VERSION ""

NS_ :

BS_:

BU_: EBOOST_CE TRCM_CE CGM_CE EPS_JR_CE MSB1_CE MSB2_CE ARS_CE SDM_CE EBCM_OBD_CE HCP_T_CE LCMS_CE APA_CE HCP_CE EOCM_F_CE MCP_C_CE MCP_B_CE MCP_A_CE FCM_CE ICCM_CE Dummy_CE TestTool_CE ACC_CE RDCM_CE EBCM_CE SADS_CE IMU_CE SAS_CE EPS_CE

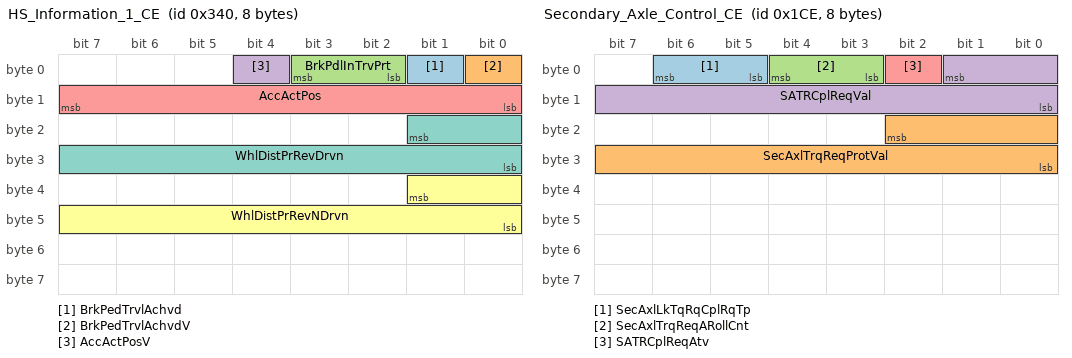
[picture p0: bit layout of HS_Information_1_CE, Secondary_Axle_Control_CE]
BO_ 832 HS_Information_1_CE: 8 EBCM_CE
 SG_ BrkPedTrvlAchvd : 1|1@0+ (1,0) [0|1] ""  SDM_CE,MSB1_CE,MSB2_CE,EPS_JR_CE
 SG_ BrkPedTrvlAchvdV : 0|1@0+ (1,0) [0|1] ""  SDM_CE,MSB1_CE,MSB2_CE,EPS_JR_CE
 SG_ BrkPdlInTrvPrt : 3|2@0+ (1,0) [0|3] ""  EPS_JR_CE
 SG_ AccActPosV : 4|1@0+ (1,0) [0|1] ""  FCM_CE,MSB1_CE,MSB2_CE
 SG_ AccActPos : 15|8@0+ (0.392157,0) [0|100.000035] "%"  FCM_CE,MSB1_CE,MSB2_CE
 SG_ WhlDistPrRevNDrvn : 33|10@0+ (3,800) [800|3869] "mm"  ARS_CE,EPS_CE,EPS_JR_CE,SDM_CE,APA_CE
 SG_ WhlDistPrRevDrvn : 17|10@0+ (3,800) [800|3869] "mm"  ARS_CE,EPS_JR_CE,EPS_CE,SDM_CE,APA_CE

BO_ 462 Secondary_Axle_Control_CE: 8 EBCM_CE
 SG_ SecAxlLkTqRqCplRqTp : 6|2@0+ (1,0) [0|3] ""  RDCM_CE
 SG_ SecAxlTrqReqProtVal : 18|11@0+ (1,0) [0|2047] "Counts"  RDCM_CE
 SG_ SecAxlTrqReqARollCnt : 4|2@0+ (1,0) [0|3] "Counts"  RDCM_CE
 SG_ SATRCplReqVal : 1|10@0+ (10,0) [0|10230] "Nm"  RDCM_CE
 SG_ SATRCplReqAtv : 2|1@0+ (1,0) [0|1] ""  RDCM_CE

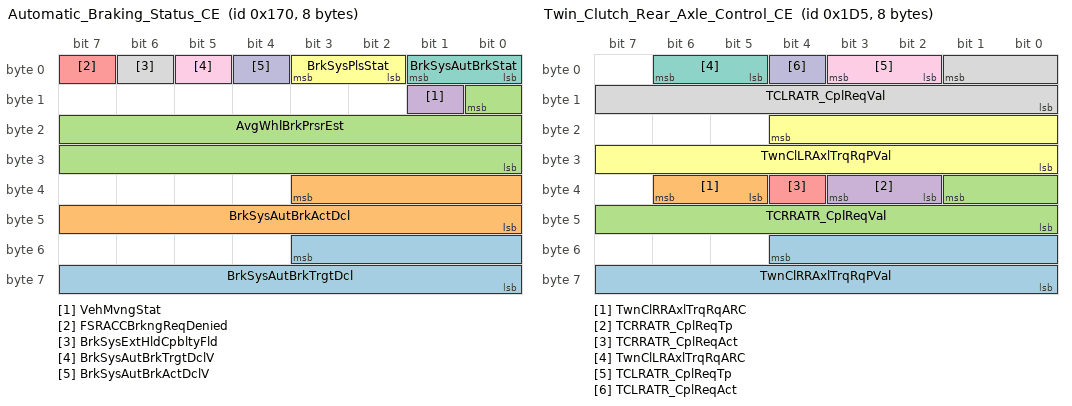
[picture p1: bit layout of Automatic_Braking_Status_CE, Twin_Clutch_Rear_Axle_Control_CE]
BO_ 368 Automatic_Braking_Status_CE: 8 EBCM_CE
 SG_ BrkSysAutBrkTrgtDcl : 51|12@0- (0.01,0) [-20.48|20.47] "m/s^2"  APA_CE,SADS_CE,ACC_CE,EOCM_F_CE
 SG_ BrkSysAutBrkActDcl : 35|12@0- (0.01,0) [-20.48|20.47] "m/s^2"  APA_CE,EOCM_F_CE,ACC_CE,SADS_CE
 SG_ AvgWhlBrkPrsrEst : 8|17@0+ (0.1,0) [0|13107.1] "kPa"  APA_CE,ACC_CE,EOCM_F_CE,SADS_CE
 SG_ VehMvngStat : 9|1@0+ (1,0) [0|1] ""  APA_CE,ACC_CE,EOCM_F_CE
 SG_ FSRACCBrkngReqDenied : 7|1@0+ (1,0) [0|1] ""  APA_CE,ACC_CE,EOCM_F_CE
 SG_ BrkSysPlsStat : 3|2@0+ (1,0) [0|3] ""  APA_CE,EOCM_F_CE
 SG_ BrkSysAutBrkStat : 1|2@0+ (1,0) [0|3] ""  ICCM_CE,APA_CE,SADS_CE,ACC_CE,EOCM_F_CE
 SG_ BrkSysExtHldCpbltyFld : 6|1@0+ (1,0) [0|1] ""  ICCM_CE,APA_CE,ACC_CE,EOCM_F_CE
 SG_ BrkSysAutBrkTrgtDclV : 5|1@0+ (1,0) [0|1] ""  APA_CE,SADS_CE,ACC_CE,EOCM_F_CE
 SG_ BrkSysAutBrkActDclV : 4|1@0+ (1,0) [0|1] ""  APA_CE,EOCM_F_CE,SADS_CE,ACC_CE

BO_ 469 Twin_Clutch_Rear_Axle_Control_CE: 8 EBCM_CE
 SG_ TwnClRRAxlTrqRqPVal : 52|13@0+ (1,0) [0|8191] ""  RDCM_CE
 SG_ TwnClRRAxlTrqRqARC : 38|2@0+ (1,0) [0|3] ""  RDCM_CE
 SG_ TCRRATR_CplReqVal : 33|10@0+ (10,0) [0|10230] "Nm"  RDCM_CE
 SG_ TCRRATR_CplReqTp : 35|2@0+ (1,0) [0|3] ""  RDCM_CE
 SG_ TCRRATR_CplReqAct : 36|1@0+ (1,0) [0|1] ""  RDCM_CE
 SG_ TwnClLRAxlTrqRqPVal : 20|13@0+ (1,0) [0|8191] ""  RDCM_CE
 SG_ TwnClLRAxlTrqRqARC : 6|2@0+ (1,0) [0|3] ""  RDCM_CE
 SG_ TCLRATR_CplReqVal : 1|10@0+ (10,0) [0|10230] "Nm"  RDCM_CE
 SG_ TCLRATR_CplReqTp : 3|2@0+ (1,0) [0|3] ""  RDCM_CE
 SG_ TCLRATR_CplReqAct : 4|1@0+ (1,0) [0|1] ""  RDCM_CE

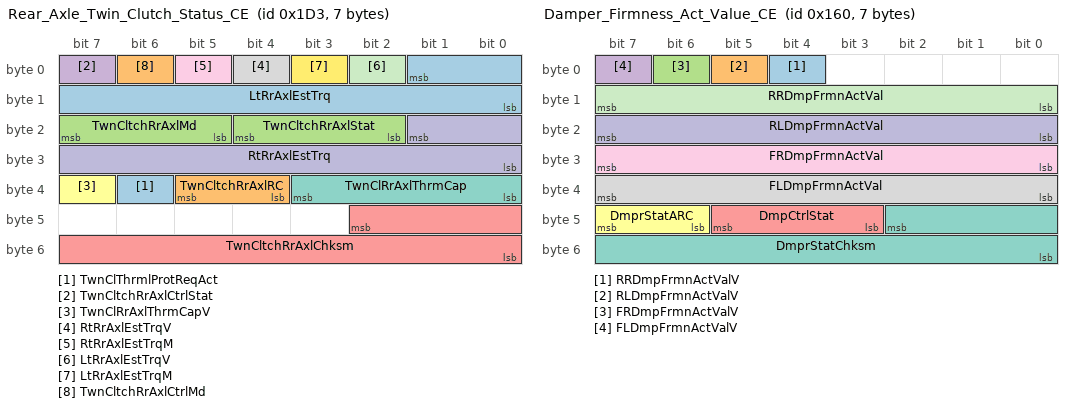
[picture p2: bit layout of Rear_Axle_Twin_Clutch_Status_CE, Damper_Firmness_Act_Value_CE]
BO_ 467 Rear_Axle_Twin_Clutch_Status_CE: 7 RDCM_CE
 SG_ TwnClThrmlProtReqAct : 38|1@0+ (1,0) [0|1] ""  EBCM_OBD_CE,EBCM_CE
 SG_ TwnCltchRrAxlRC : 37|2@0+ (1,0) [0|3] ""  EBCM_OBD_CE,EBCM_CE
 SG_ TwnCltchRrAxlMd : 23|3@0+ (1,0) [0|7] ""  EBCM_OBD_CE,EBCM_CE
 SG_ TwnCltchRrAxlCtrlStat : 7|1@0+ (1,0) [0|1] ""  EBCM_OBD_CE,EBCM_CE
 SG_ TwnCltchRrAxlChksm : 42|11@0+ (1,0) [0|2047] ""  EBCM_OBD_CE,EBCM_CE
 SG_ TwnClRrAxlThrmCapV : 39|1@0+ (1,0) [0|1] ""  EBCM_OBD_CE,EBCM_CE
 SG_ TwnClRrAxlThrmCap : 35|4@0+ (6.7,0) [0|100.5] "%"  EBCM_OBD_CE,EBCM_CE
 SG_ RtRrAxlEstTrqV : 4|1@0+ (1,0) [0|1] ""  EBCM_OBD_CE,EBCM_CE
 SG_ RtRrAxlEstTrqM : 5|1@0+ (1,0) [0|1] ""  EBCM_OBD_CE,EBCM_CE
 SG_ RtRrAxlEstTrq : 17|10@0+ (10,0) [0|10230] "Nm"  EBCM_OBD_CE,EBCM_CE
 SG_ LtRrAxlEstTrqV : 2|1@0+ (1,0) [0|1] ""  EBCM_OBD_CE,EBCM_CE
 SG_ LtRrAxlEstTrqM : 3|1@0+ (1,0) [0|1] ""  EBCM_OBD_CE,EBCM_CE
 SG_ LtRrAxlEstTrq : 1|10@0+ (10,0) [0|10230] "Nm"  EBCM_OBD_CE,EBCM_CE
 SG_ TwnCltchRrAxlCtrlMd : 6|1@0+ (1,0) [0|1] ""  EBCM_OBD_CE,EBCM_CE
 SG_ TwnCltchRrAxlStat : 20|3@0+ (1,0) [0|7] ""  EBCM_OBD_CE,EBCM_CE

BO_ 352 Damper_Firmness_Act_Value_CE: 7 SADS_CE
 SG_ RRDmpFrmnActValV : 4|1@0+ (1,0) [0|1] ""  EBCM_OBD_CE,EBCM_CE
 SG_ RLDmpFrmnActValV : 5|1@0+ (1,0) [0|1] ""  EBCM_OBD_CE,EBCM_CE
 SG_ FRDmpFrmnActValV : 6|1@0+ (1,0) [0|1] ""  EBCM_OBD_CE,EBCM_CE
 SG_ FLDmpFrmnActValV : 7|1@0+ (1,0) [0|1] ""  EBCM_OBD_CE,EBCM_CE
 SG_ DmpCtrlStat : 45|3@0+ (1,0) [0|7] ""  EBCM_OBD_CE,EBCM_CE
 SG_ DmprStatARC : 47|2@0+ (1,0) [0|3] "Counts"  EBCM_OBD_CE,EBCM_CE
 SG_ DmprStatChksm : 42|11@0+ (1,0) [0|2047] ""  EBCM_OBD_CE,EBCM_CE
 SG_ FLDmpFrmnActVal : 39|8@0+ (0.392157,0) [0|100.000035] "%"  EBCM_OBD_CE,EBCM_CE
 SG_ FRDmpFrmnActVal : 31|8@0+ (0.392157,0) [0|100.000035] "%"  EBCM_OBD_CE,EBCM_CE
 SG_ RLDmpFrmnActVal : 23|8@0+ (0.392157,0) [0|100.000035] "%"  EBCM_OBD_CE,EBCM_CE
 SG_ RRDmpFrmnActVal : 15|8@0+ (0.392157,0) [0|100.000035] "%"  EBCM_OBD_CE,EBCM_CE

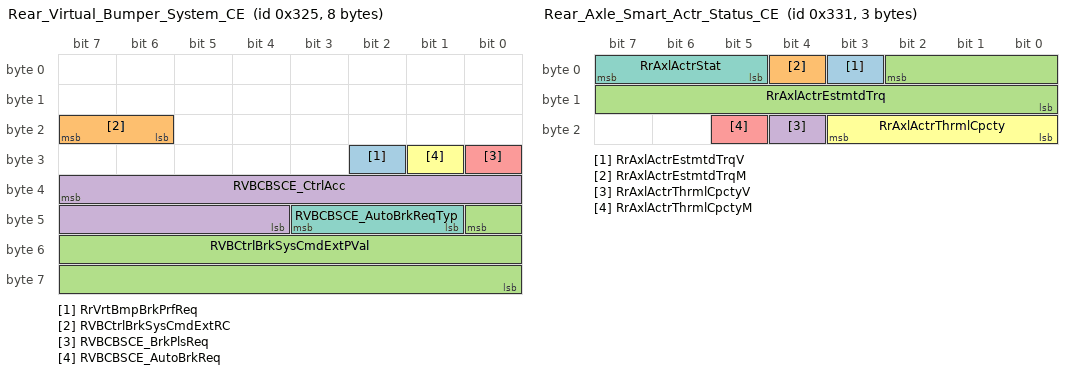
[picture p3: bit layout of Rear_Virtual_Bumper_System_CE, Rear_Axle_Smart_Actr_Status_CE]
BO_ 805 Rear_Virtual_Bumper_System_CE: 8 EOCM_F_CE
 SG_ RrVrtBmpBrkPrfReq : 26|1@0+ (1,0) [0|1] ""  EBCM_OBD_CE,EBCM_CE
 SG_ RVBCtrlBrkSysCmdExtRC : 23|2@0+ (1,0) [0|3] ""  EBCM_OBD_CE,EBCM_CE
 SG_ RVBCtrlBrkSysCmdExtPVal : 40|17@0+ (1,0) [0|131071] ""  EBCM_OBD_CE,EBCM_CE
 SG_ RVBCBSCE_CtrlAcc : 39|12@0- (0.01,0) [-20.48|20.47] "m/s^2"  EBCM_OBD_CE,EBCM_CE
 SG_ RVBCBSCE_BrkPlsReq : 24|1@0+ (1,0) [0|1] ""  EBCM_OBD_CE,EBCM_CE
 SG_ RVBCBSCE_AutoBrkReq : 25|1@0+ (1,0) [0|1] ""  EBCM_OBD_CE,EBCM_CE
 SG_ RVBCBSCE_AutoBrkReqTyp : 43|3@0+ (1,0) [0|7] ""  EBCM_OBD_CE,EBCM_CE

BO_ 257 USDT_Req_to_All_CE_ECUs: 8 TestTool_CE
 SG_ DgnInf : 7|64@0+ (1,0) [0|1.84467440737096E+019] ""  SDM_CE,EBCM_OBD_CE,HCP_T_CE,HCP_CE,ARS_CE,ICCM_CE,ACC_CE,MCP_C_CE,APA_CE,MCP_B_CE,MCP_A_CE,EBOOST_CE,MSB2_CE,MSB1_CE,SAS_CE,SADS_CE,RDCM_CE,IMU_CE,Dummy_CE,EPS_JR_CE,EPS_CE,EBCM_CE,CGM_CE,TRCM_CE,EOCM_F_CE,FCM_CE

BO_ 1375 UUDT_Resp_From_Free_5F_CE: 8 Dummy_CE
 SG_ DgnInf_CE55F : 7|64@0+ (1,0) [0|1.84467440737096E+019] ""  TestTool_CE

BO_ 1374 UUDT_Resp_From_Free_5E_CE: 8 Dummy_CE
 SG_ DgnInf_CE55E : 7|64@0+ (1,0) [0|1.84467440737096E+019] ""  TestTool_CE

BO_ 1373 UUDT_Resp_From_ARS_CE: 8 ARS_CE
 SG_ DgnInf_CE55D : 7|64@0+ (1,0) [0|1.84467440737096E+019] ""  TestTool_CE

BO_ 1371 UUDT_Resp_From_ACC_CE: 8 ACC_CE
 SG_ DgnInf_CE55B : 7|64@0+ (1,0) [0|1.84467440737096E+019] ""  TestTool_CE

BO_ 1370 UUDT_Resp_From_MCP_C_CE: 8 MCP_C_CE
 SG_ DgnInf_CE55A : 7|64@0+ (1,0) [0|1.84467440737096E+019] ""  TestTool_CE

BO_ 1369 UUDT_Resp_From_APA_CE: 8 APA_CE
 SG_ DgnInf_CE559 : 7|64@0+ (1,0) [0|1.84467440737096E+019] ""  TestTool_CE

BO_ 1372 UUDT_Resp_From_ICCM_CE: 8 ICCM_CE
 SG_ DgnInf_CE55C : 7|64@0+ (1,0) [0|1.84467440737096E+019] ""  TestTool_CE

BO_ 1367 UUDT_Resp_From_MCP_A_CE: 8 MCP_A_CE
 SG_ DgnInf_CE557 : 7|64@0+ (1,0) [0|1.84467440737096E+019] ""  TestTool_CE

BO_ 1366 UUDT_Resp_From_Free_56_CE: 8 Dummy_CE
 SG_ DgnInf_CE556 : 7|64@0+ (1,0) [0|1.84467440737096E+019] ""  TestTool_CE

BO_ 1365 UUDT_Resp_From_TRCM_CE: 8 TRCM_CE
 SG_ DgnInf_CE555 : 7|64@0+ (1,0) [0|1.84467440737096E+019] ""  TestTool_CE

BO_ 1368 UUDT_Resp_From_MCP_B_CE: 8 MCP_B_CE
 SG_ DgnInf_CE558 : 7|64@0+ (1,0) [0|1.84467440737096E+019] ""  TestTool_CE

BO_ 1363 UUDT_Resp_From_CGM_CE: 8 CGM_CE
 SG_ DgnInf_CE553 : 7|64@0+ (1,0) [0|1.84467440737096E+019] ""  TestTool_CE

BO_ 1362 UUDT_Resp_From_Free_52_CE: 8 Dummy_CE
 SG_ DgnInf_CE552 : 7|64@0+ (1,0) [0|1.84467440737096E+019] ""  TestTool_CE

BO_ 1361 UUDT_Resp_From_Free_51_CE: 8 Dummy_CE
 SG_ DgnInf_CE551 : 7|64@0+ (1,0) [0|1.84467440737096E+019] ""  TestTool_CE

BO_ 1518 UUDT_Resp_From_EBOOST_CE: 8 EBOOST_CE
 SG_ DgnInf_CE554 : 7|64@0+ (1,0) [0|1.84467440737096E+019] ""  TestTool_CE

BO_ 1359 UUDT_Resp_From_RDCM_CE: 8 RDCM_CE
 SG_ DgnInf_CE54F : 7|64@0+ (1,0) [0|1.84467440737096E+019] ""  TestTool_CE

BO_ 1358 UUDT_Resp_From_SADS_CE: 8 SADS_CE
 SG_ DgnInf_CE54E : 7|64@0+ (1,0) [0|1.84467440737096E+019] ""  TestTool_CE

BO_ 1357 UUDT_Resp_From_Free_4D_CE: 8 Dummy_CE
 SG_ DgnInf_CE54D : 7|64@0+ (1,0) [0|1.84467440737096E+019] ""  TestTool_CE

BO_ 1360 UUDT_Resp_From_Free_50_CE: 8 Dummy_CE
 SG_ DgnInf_CE550 : 7|64@0+ (1,0) [0|1.84467440737096E+019] ""  TestTool_CE

BO_ 1355 UUDT_Resp_From_EOCM_FCM_CE: 8 FCM_CE
 SG_ DgnInf_CE54B : 7|64@0+ (1,0) [0|1.84467440737096E+019] ""  TestTool_CE

BO_ 1352 UUDT_Resp_From_MSB1_CE: 8 MSB1_CE
 SG_ DgnInf_CE548 : 7|64@0+ (1,0) [0|1.84467440737096E+019] ""  TestTool_CE

BO_ 1353 UUDT_Resp_From_MSB2_CE: 8 MSB2_CE
 SG_ DgnInf_CE549 : 7|64@0+ (1,0) [0|1.84467440737096E+019] ""  TestTool_CE

BO_ 1351 UUDT_Resp_From_SDM_CE: 8 SDM_CE
 SG_ DgnInf_CE547 : 7|64@0+ (1,0) [0|1.84467440737096E+019] ""  TestTool_CE

BO_ 1350 UUDT_Resp_From_Free_46_CE: 8 Dummy_CE
 SG_ DgnInf_CE546 : 7|64@0+ (1,0) [0|1.84467440737096E+019] ""  TestTool_CE

BO_ 1349 UUDT_Resp_From_Free_45_CE: 8 Dummy_CE
 SG_ DgnInf_CE545 : 7|64@0+ (1,0) [0|1.84467440737096E+019] ""  TestTool_CE

BO_ 1356 UUDT_Resp_From_Free_48_CE: 8 Dummy_CE
 SG_ DgnInf_CE54C : 7|64@0+ (1,0) [0|1.84467440737096E+019] ""  TestTool_CE

BO_ 1348 UUDT_Resp_From_IMU_CE: 8 IMU_CE
 SG_ DgnInf_CE544 : 7|64@0+ (1,0) [0|1.84467440737096E+019] ""  TestTool_CE

BO_ 1347 UUDT_Resp_From_EBCM_CE: 8 EBCM_CE
 SG_ DgnInf_CE543 : 7|64@0+ (1,0) [0|1.84467440737096E+019] ""  TestTool_CE

BO_ 1354 UUDT_Resp_From_EPS_EPS_JR_CE: 8 EPS_CE
 SG_ DgnInf_CE542 : 7|64@0+ (1,0) [0|1.84467440737096E+019] ""  TestTool_CE

BO_ 1345 UUDT_Resp_From_Free_41_CE: 8 Dummy_CE
 SG_ DgnInf_CE541 : 7|64@0+ (1,0) [0|1.84467440737096E+019] ""  TestTool_CE

BO_ 1631 USDT_Resp_From_Free_5F_CE: 8 Dummy_CE
 SG_ DgnInf : 7|64@0+ (1,0) [0|1.84467440737096E+019] ""  TestTool_CE

BO_ 1630 USDT_Resp_From_Free_5E_CE: 8 Dummy_CE
 SG_ DgnInf : 7|64@0+ (1,0) [0|1.84467440737096E+019] ""  TestTool_CE

BO_ 1629 USDT_Resp_From_ARS_CE: 8 ARS_CE
 SG_ DgnInf : 7|64@0+ (1,0) [0|1.84467440737096E+019] ""  TestTool_CE

BO_ 1627 USDT_Resp_From_ACC_CE: 8 ACC_CE
 SG_ DgnInf : 7|64@0+ (1,0) [0|1.84467440737096E+019] ""  TestTool_CE

BO_ 1626 USDT_Resp_From_MCP_C_CE: 8 MCP_C_CE
 SG_ DgnInf : 7|64@0+ (1,0) [0|1.84467440737096E+019] ""  TestTool_CE

BO_ 1625 USDT_Resp_From_APA_CE: 8 APA_CE
 SG_ DgnInf : 7|64@0+ (1,0) [0|1.84467440737096E+019] ""  TestTool_CE

BO_ 1628 USDT_Resp_From_ICCM_CE: 8 ICCM_CE
 SG_ DgnInf : 7|64@0+ (1,0) [0|1.84467440737096E+019] ""  TestTool_CE

BO_ 1623 USDT_Resp_From_MCP_A_CE: 8 MCP_A_CE
 SG_ DgnInf : 7|64@0+ (1,0) [0|1.84467440737096E+019] ""  TestTool_CE

BO_ 1622 USDT_Resp_From_Free_56_CE: 8 Dummy_CE
 SG_ DgnInf : 7|64@0+ (1,0) [0|1.84467440737096E+019] ""  TestTool_CE

BO_ 1621 USDT_Resp_From_TRCM_CE: 8 TRCM_CE
 SG_ DgnInf : 7|64@0+ (1,0) [0|1.84467440737096E+019] ""  TestTool_CE

BO_ 1624 USDT_Resp_From_MCP_B_CE: 8 MCP_B_CE
 SG_ DgnInf : 7|64@0+ (1,0) [0|1.84467440737096E+019] ""  TestTool_CE

BO_ 1619 USDT_Resp_From_CGM_CE: 8 CGM_CE
 SG_ DgnInf : 7|64@0+ (1,0) [0|1.84467440737096E+019] ""  TestTool_CE

BO_ 1618 USDT_Resp_From_Free_52_CE: 8 Dummy_CE
 SG_ DgnInf : 7|64@0+ (1,0) [0|1.84467440737096E+019] ""  TestTool_CE

BO_ 1617 USDT_Resp_From_Free_51_CE: 8 Dummy_CE
 SG_ DgnInf : 7|64@0+ (1,0) [0|1.84467440737096E+019] ""  TestTool_CE

BO_ 2030 USDT_Resp_From_EBOOST_CE: 8 EBOOST_CE
 SG_ DgnInf : 7|64@0+ (1,0) [0|1.84467440737096E+019] ""  TestTool_CE

BO_ 1615 USDT_Resp_From_RDCM_CE: 8 RDCM_CE
 SG_ DgnInf : 7|64@0+ (1,0) [0|1.84467440737096E+019] ""  TestTool_CE

BO_ 1614 USDT_Resp_From_SADS_CE: 8 SADS_CE
 SG_ DgnInf : 7|64@0+ (1,0) [0|1.84467440737096E+019] ""  TestTool_CE

BO_ 1613 USDT_Resp_From_Free_4D_CE: 8 Dummy_CE
 SG_ DgnInf : 7|64@0+ (1,0) [0|1.84467440737096E+019] ""  TestTool_CE

BO_ 1616 USDT_Resp_From_Free_50_CE: 8 Dummy_CE
 SG_ DgnInf : 7|64@0+ (1,0) [0|1.84467440737096E+019] ""  TestTool_CE

BO_ 1611 USDT_Resp_From_EOCM_FCM_CE: 8 FCM_CE
 SG_ DgnInf : 7|64@0+ (1,0) [0|1.84467440737096E+019] ""  TestTool_CE

BO_ 1608 USDT_Resp_From_MSB1_CE: 8 MSB1_CE
 SG_ DgnInf : 7|64@0+ (1,0) [0|1.84467440737096E+019] ""  TestTool_CE

BO_ 1609 USDT_Resp_From_MSB2_CE: 8 MSB2_CE
 SG_ DgnInf : 7|64@0+ (1,0) [0|1.84467440737096E+019] ""  TestTool_CE

BO_ 1607 USDT_Resp_From_SDM_CE: 8 SDM_CE
 SG_ DgnInf : 7|64@0+ (1,0) [0|1.84467440737096E+019] ""  TestTool_CE

BO_ 1606 USDT_Resp_From_Free_46_CE: 8 Dummy_CE
 SG_ DgnInf : 7|64@0+ (1,0) [0|1.84467440737096E+019] ""  TestTool_CE

BO_ 1605 USDT_Resp_From_Free_45_CE: 8 Dummy_CE
 SG_ DgnInf : 7|64@0+ (1,0) [0|1.84467440737096E+019] ""  TestTool_CE

BO_ 1612 USDT_Resp_From_Free_48_CE: 8 Dummy_CE
 SG_ DgnInf : 7|64@0+ (1,0) [0|1.84467440737096E+019] ""  TestTool_CE

BO_ 1604 USDT_Resp_From_IMU_CE: 8 IMU_CE
 SG_ DgnInf : 7|64@0+ (1,0) [0|1.84467440737096E+019] ""  TestTool_CE

BO_ 1603 USDT_Resp_From_EBCM_CE: 8 EBCM_CE
 SG_ DgnInf : 7|64@0+ (1,0) [0|1.84467440737096E+019] ""  TestTool_CE

BO_ 1610 USDT_Resp_From_EPS_EPS_JR_CE: 8 EPS_CE
 SG_ DgnInf : 7|64@0+ (1,0) [0|1.84467440737096E+019] ""  TestTool_CE

BO_ 1601 USDT_Resp_From_Free_41_CE: 8 Dummy_CE
 SG_ DgnInf : 7|64@0+ (1,0) [0|1.84467440737096E+019] ""  TestTool_CE

BO_ 607 USDT_Req_to_Free_5F_CE: 8 TestTool_CE
 SG_ DgnInf : 7|64@0+ (1,0) [0|1.84467440737096E+019] ""  Dummy_CE

BO_ 606 USDT_Req_to_Free_5E_CE: 8 TestTool_CE
 SG_ DgnInf : 7|64@0+ (1,0) [0|1.84467440737096E+019] ""  Dummy_CE

BO_ 605 USDT_Req_to_ARS_CE: 8 TestTool_CE
 SG_ DgnInf : 7|64@0+ (1,0) [0|1.84467440737096E+019] ""  ARS_CE

BO_ 604 USDT_Req_to_ICCM_CE: 8 TestTool_CE
 SG_ DgnInf : 7|64@0+ (1,0) [0|1.84467440737096E+019] ""  ICCM_CE

BO_ 603 USDT_Req_to_ACC_CE: 8 TestTool_CE
 SG_ DgnInf : 7|64@0+ (1,0) [0|1.84467440737096E+019] ""  ACC_CE

BO_ 602 USDT_Req_to_MCP_C_CE: 8 TestTool_CE
 SG_ DgnInf : 7|64@0+ (1,0) [0|1.84467440737096E+019] ""  MCP_C_CE

BO_ 601 USDT_Req_to_APA_CE: 8 TestTool_CE
 SG_ DgnInf : 7|64@0+ (1,0) [0|1.84467440737096E+019] ""  APA_CE

BO_ 600 USDT_Req_to_MCP_B_CE: 8 TestTool_CE
 SG_ DgnInf : 7|64@0+ (1,0) [0|1.84467440737096E+019] ""  MCP_B_CE

BO_ 599 USDT_Req_to_MCP_A_CE: 8 TestTool_CE
 SG_ DgnInf : 7|64@0+ (1,0) [0|1.84467440737096E+019] ""  MCP_A_CE

BO_ 598 USDT_Req_to_Free_56_CE: 8 TestTool_CE
 SG_ DgnInf : 7|64@0+ (1,0) [0|1.84467440737096E+019] ""  Dummy_CE

BO_ 597 USDT_Req_To_TRCM_CE: 8 TestTool_CE
 SG_ DgnInf : 7|64@0+ (1,0) [0|1.84467440737096E+019] ""  TRCM_CE

BO_ 2022 USDT_Req_to_EBOOST_CE: 8 TestTool_CE
 SG_ DgnInf : 7|64@0+ (1,0) [0|1.84467440737096E+019] ""  EBOOST_CE

BO_ 595 USDT_Req_to_CGM_CE: 8 TestTool_CE
 SG_ DgnInf : 7|64@0+ (1,0) [0|1.84467440737096E+019] ""  CGM_CE

BO_ 594 USDT_Req_to_Free_52_CE: 8 TestTool_CE
 SG_ DgnInf : 7|64@0+ (1,0) [0|1.84467440737096E+019] ""  Dummy_CE

BO_ 593 USDT_Req_to_Free_51_CE: 8 TestTool_CE
 SG_ DgnInf : 7|64@0+ (1,0) [0|1.84467440737096E+019] ""  Dummy_CE

BO_ 592 USDT_Req_to_Free_50_CE: 8 TestTool_CE
 SG_ DgnInf : 7|64@0+ (1,0) [0|1.84467440737096E+019] ""  Dummy_CE

BO_ 591 USDT_Req_to_RDCM_CE: 8 TestTool_CE
 SG_ DgnInf : 7|64@0+ (1,0) [0|1.84467440737096E+019] ""  RDCM_CE

BO_ 590 USDT_Req_to_SADS_CE: 8 TestTool_CE
 SG_ DgnInf : 7|64@0+ (1,0) [0|1.84467440737096E+019] ""  SADS_CE

BO_ 589 USDT_Req_to_Free_4D_CE: 8 TestTool_CE
 SG_ DgnInf : 7|64@0+ (1,0) [0|1.84467440737096E+019] ""  Dummy_CE

BO_ 585 USDT_Req_to_MSB2_CE: 8 TestTool_CE
 SG_ DgnInf : 7|64@0+ (1,0) [0|1.84467440737096E+019] ""  MSB2_CE

BO_ 587 USDT_Req_to_EOCM_CE: 8 TestTool_CE
 SG_ DgnInf : 7|64@0+ (1,0) [0|1.84467440737096E+019] ""  EOCM_F_CE,FCM_CE

BO_ 584 USDT_Req_to_MSB1_CE: 8 TestTool_CE
 SG_ DgnInf : 7|64@0+ (1,0) [0|1.84467440737096E+019] ""  MSB1_CE

BO_ 588 USDT_Req_to_Free_48_CE: 8 TestTool_CE
 SG_ DgnInf : 7|64@0+ (1,0) [0|1.84467440737096E+019] ""  Dummy_CE

BO_ 583 USDT_Req_to_SDM_CE: 8 TestTool_CE
 SG_ DgnInf : 7|64@0+ (1,0) [0|1.84467440737096E+019] ""  SDM_CE

BO_ 582 USDT_Req_to_Free_46_CE: 8 TestTool_CE
 SG_ DgnInf : 7|64@0+ (1,0) [0|1.84467440737096E+019] ""  Dummy_CE

BO_ 581 USDT_Req_to_Free_45_CE: 8 TestTool_CE
 SG_ DgnInf : 7|64@0+ (1,0) [0|1.84467440737096E+019] ""  Dummy_CE

BO_ 817 Rear_Axle_Smart_Actr_Status_CE: 3 RDCM_CE
 SG_ RrAxlActrEstmtdTrqV : 3|1@0+ (1,0) [0|1] ""  ICCM_CE
 SG_ RrAxlActrEstmtdTrqM : 4|1@0+ (1,0) [0|1] ""  ICCM_CE
 SG_ RrAxlActrEstmtdTrq : 2|11@0+ (5,-5120) [-5120|5115] "Nm"  ICCM_CE
 SG_ RrAxlActrThrmlCpctyV : 20|1@0+ (1,0) [0|1] ""  ICCM_CE
 SG_ RrAxlActrThrmlCpctyM : 21|1@0+ (1,0) [0|1] ""  ICCM_CE
 SG_ RrAxlActrThrmlCpcty : 19|4@0+ (6.7,0) [0|100.5] "%"  ICCM_CE
 SG_ RrAxlActrStat : 7|3@0+ (1,0) [0|7] ""  ICCM_CE

BO_ 580 USDT_Req_to_IMU_CE: 8 TestTool_CE
 SG_ DgnInf : 7|64@0+ (1,0) [0|1.84467440737096E+019] ""  IMU_CE

BO_ 579 USDT_Req_to_EBCM_CE: 8 TestTool_CE
 SG_ DgnInf : 7|64@0+ (1,0) [0|1.84467440737096E+019] ""  EBCM_CE

BO_ 578 USDT_Req_to_EPS_EPS_JR_CE: 8 TestTool_CE
 SG_ DgnInf : 7|64@0+ (1,0) [0|1.84467440737096E+019] ""  EPS_JR_CE,EPS_CE

BO_ 577 USDT_Req_to_Free_41_CE: 8 TestTool_CE
 SG_ DgnInf : 7|64@0+ (1,0) [0|1.84467440737096E+019] ""  Dummy_CE

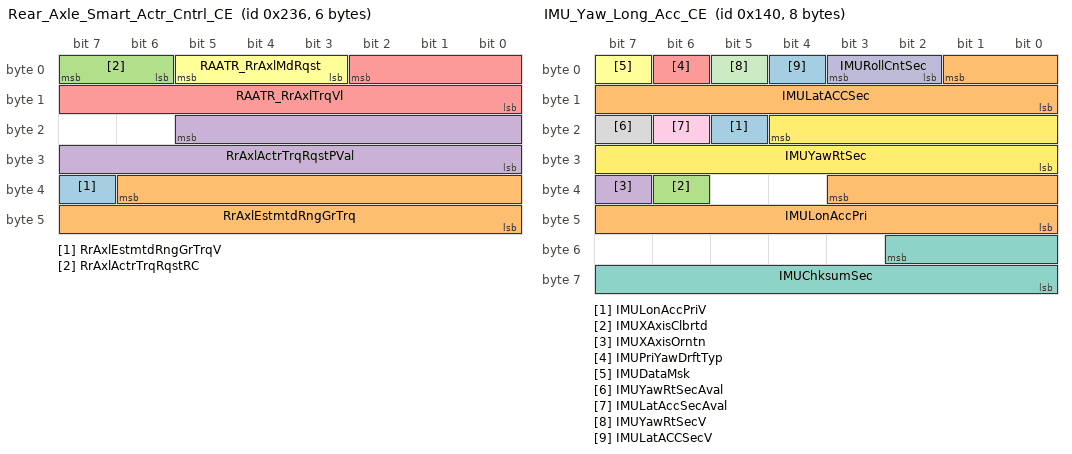
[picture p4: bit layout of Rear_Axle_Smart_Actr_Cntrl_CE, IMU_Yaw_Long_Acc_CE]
BO_ 566 Rear_Axle_Smart_Actr_Cntrl_CE: 6 ICCM_CE
 SG_ RrAxlEstmtdRngGrTrqV : 39|1@0+ (1,0) [0|1] ""  RDCM_CE
 SG_ RrAxlEstmtdRngGrTrq : 38|15@0+ (2,-22534) [-22534|43000] "Nm"  RDCM_CE
 SG_ RrAxlActrTrqRqstRC : 7|2@0+ (1,0) [0|3] ""  RDCM_CE
 SG_ RrAxlActrTrqRqstPVal : 21|14@0+ (1,0) [0|16383] ""  RDCM_CE
 SG_ RAATR_RrAxlTrqVl : 2|11@0+ (5,-5120) [-5120|5115] "Nm"  RDCM_CE
 SG_ RAATR_RrAxlMdRqst : 5|3@0+ (1,0) [0|7] ""  RDCM_CE

BO_ 320 IMU_Yaw_Long_Acc_CE: 8 IMU_CE
 SG_ IMULonAccPriV : 21|1@0+ (1,0) [0|1] ""  FCM_CE,ICCM_CE,APA_CE,SADS_CE,ACC_CE,EBCM_OBD_CE,EBCM_CE,RDCM_CE,SDM_CE,EOCM_F_CE,EPS_JR_CE,EPS_CE
 SG_ IMULonAccPri : 35|12@0- (0.015625,0) [-32|31.984375] "m/s^2"  FCM_CE,ICCM_CE,APA_CE,SADS_CE,ACC_CE,EBCM_OBD_CE,EBCM_CE,RDCM_CE,SDM_CE,EOCM_F_CE,EPS_JR_CE,EPS_CE
 SG_ IMUXAxisClbrtd : 38|1@0+ (1,0) [0|1] ""  APA_CE,FCM_CE,ICCM_CE,ACC_CE,SADS_CE,RDCM_CE,EBCM_OBD_CE,EBCM_CE,SDM_CE,EOCM_F_CE,EPS_JR_CE,EPS_CE
 SG_ IMUXAxisOrntn : 39|1@0+ (1,0) [0|1] ""  APA_CE,FCM_CE,ICCM_CE,ACC_CE,SADS_CE,RDCM_CE,EBCM_OBD_CE,EBCM_CE,SDM_CE,EOCM_F_CE,EPS_JR_CE,EPS_CE
 SG_ IMUPriYawDrftTyp : 6|1@0+ (1,0) [0|1] ""  APA_CE,FCM_CE,ICCM_CE,ACC_CE,SADS_CE,RDCM_CE,EBCM_OBD_CE,EBCM_CE,SDM_CE,EOCM_F_CE,EPS_JR_CE,EPS_CE
 SG_ IMUDataMsk : 7|1@0+ (1,0) [0|1] ""  APA_CE,EPS_JR_CE,FCM_CE,ACC_CE,SADS_CE,RDCM_CE,EBCM_OBD_CE,EBCM_CE,EPS_CE,SDM_CE,EOCM_F_CE
 SG_ IMUChksumSec : 50|11@0+ (1,0) [0|2047] ""  APA_CE,FCM_CE,ICCM_CE,ACC_CE,SDM_CE,EOCM_F_CE,RDCM_CE,EPS_JR_CE,EPS_CE,EBCM_OBD_CE,EBCM_CE,SADS_CE
 SG_ IMUYawRtSecAval : 23|1@0+ (1,0) [0|1] ""  APA_CE,FCM_CE,ICCM_CE,SADS_CE,SDM_CE,ACC_CE,EOCM_F_CE,EPS_JR_CE,EPS_CE,EBCM_OBD_CE,EBCM_CE,RDCM_CE
 SG_ IMULatAccSecAval : 22|1@0+ (1,0) [0|1] ""  APA_CE,FCM_CE,ICCM_CE,ACC_CE,SADS_CE,SDM_CE,RDCM_CE,EOCM_F_CE,EPS_JR_CE,EPS_CE,EBCM_OBD_CE,EBCM_CE
 SG_ IMURollCntSec : 3|2@0+ (1,0) [0|3] ""  APA_CE,FCM_CE,ICCM_CE,ACC_CE,SADS_CE,SDM_CE,EOCM_F_CE,RDCM_CE,EPS_JR_CE,EPS_CE,EBCM_OBD_CE,EBCM_CE
 SG_ IMUYawRtSecV : 5|1@0+ (1,0) [0|1] ""  APA_CE,FCM_CE,ICCM_CE,SADS_CE,SDM_CE,ACC_CE,EOCM_F_CE,EPS_JR_CE,EPS_CE,EBCM_OBD_CE,EBCM_CE,RDCM_CE
 SG_ IMUYawRtSec : 20|13@0- (0.024,0) [-98.304|98.28] "deg/sec"  APA_CE,FCM_CE,ICCM_CE,SADS_CE,SDM_CE,ACC_CE,EOCM_F_CE,EPS_JR_CE,EPS_CE,EBCM_OBD_CE,EBCM_CE,RDCM_CE
 SG_ IMULatACCSecV : 4|1@0+ (1,0) [0|1] ""  APA_CE,FCM_CE,ICCM_CE,SADS_CE,SDM_CE,ACC_CE,RDCM_CE,EPS_JR_CE,EOCM_F_CE,EPS_CE,EBCM_OBD_CE,EBCM_CE
 SG_ IMULatACCSec : 1|10@0- (0.0625,0) [-32|31.9375] "m/s^2"  APA_CE,FCM_CE,ICCM_CE,SADS_CE,SDM_CE,ACC_CE,RDCM_CE,EOCM_F_CE,EPS_JR_CE,EPS_CE,EBCM_OBD_CE,EBCM_CE

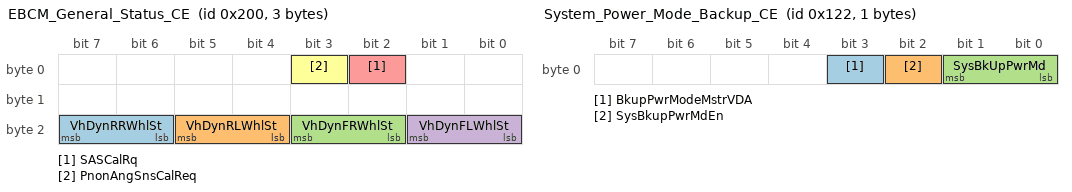
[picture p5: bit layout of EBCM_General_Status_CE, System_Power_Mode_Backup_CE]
BO_ 512 EBCM_General_Status_CE: 3 EBCM_CE
 SG_ VhDynRRWhlSt : 23|2@0+ (1,0) [0|3] ""  SADS_CE
 SG_ VhDynRLWhlSt : 21|2@0+ (1,0) [0|3] ""  SADS_CE
 SG_ VhDynFRWhlSt : 19|2@0+ (1,0) [0|3] ""  SADS_CE
 SG_ VhDynFLWhlSt : 17|2@0+ (1,0) [0|3] ""  SADS_CE
 SG_ SASCalRq : 2|1@0+ (1,0) [0|1] ""  SAS_CE
 SG_ PnonAngSnsCalReq : 3|1@0+ (1,0) [0|1] ""  SAS_CE

BO_ 290 System_Power_Mode_Backup_CE: 1 EBCM_CE
 SG_ BkupPwrModeMstrVDA : 3|1@0+ (1,0) [0|1] ""  EBOOST_CE,TRCM_CE,EPS_JR_CE,MSB1_CE,MSB2_CE,SDM_CE,FCM_CE,IMU_CE,SAS_CE
 SG_ SysBkupPwrMdEn : 2|1@0+ (1,0) [0|1] ""  EBOOST_CE,TRCM_CE,EPS_JR_CE,MSB1_CE,MSB2_CE,SDM_CE,FCM_CE,IMU_CE,SAS_CE
 SG_ SysBkUpPwrMd : 1|2@0+ (1,0) [0|3] ""  EBOOST_CE,TRCM_CE,EPS_JR_CE,MSB1_CE,MSB2_CE,SDM_CE,FCM_CE,IMU_CE,SAS_CE

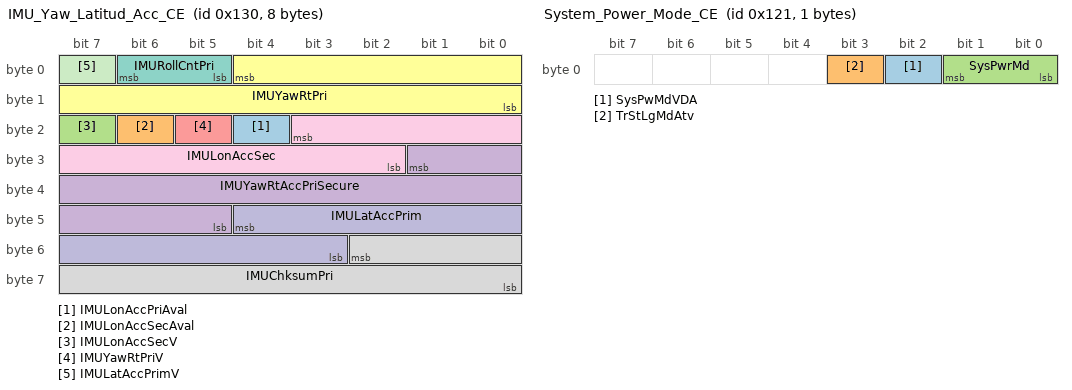
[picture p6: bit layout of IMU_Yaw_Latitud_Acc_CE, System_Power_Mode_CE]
BO_ 304 IMU_Yaw_Latitud_Acc_CE: 8 IMU_CE
 SG_ IMULonAccPriAval : 20|1@0+ (1,0) [0|1] ""  APA_CE,FCM_CE,ICCM_CE,SADS_CE,RDCM_CE,EBCM_OBD_CE,EBCM_CE,ACC_CE,SDM_CE,EOCM_F_CE,EPS_JR_CE,EPS_CE
 SG_ IMULonAccSecAval : 22|1@0+ (1,0) [0|1] ""  APA_CE,FCM_CE,ICCM_CE,SADS_CE,RDCM_CE,EBCM_OBD_CE,EBCM_CE,ACC_CE,SDM_CE,EOCM_F_CE,EPS_JR_CE,EPS_CE
 SG_ IMULonAccSecV : 23|1@0+ (1,0) [0|1] ""  APA_CE,FCM_CE,ICCM_CE,SADS_CE,RDCM_CE,EBCM_OBD_CE,EBCM_CE,ACC_CE,SDM_CE,EOCM_F_CE,EPS_JR_CE,EPS_CE
 SG_ IMUYawRtAccPriSecure : 25|13@0- (0.25,0) [-1024|1023.75] "deg/s^2"  APA_CE,FCM_CE,ICCM_CE,SADS_CE,RDCM_CE,EBCM_OBD_CE,EBCM_CE,ACC_CE,EOCM_F_CE,EPS_JR_CE,SDM_CE,EPS_CE
 SG_ IMUYawRtPriV : 21|1@0+ (1,0) [0|1] ""  FCM_CE,ICCM_CE,APA_CE,EPS_JR_CE,EOCM_F_CE,SDM_CE,EPS_CE,ACC_CE,EBCM_OBD_CE,EBCM_CE,RDCM_CE,SADS_CE
 SG_ IMUYawRtPri : 4|13@0- (0.024,0) [-98.304|98.28] "deg/sec"  FCM_CE,ICCM_CE,APA_CE,EPS_JR_CE,EOCM_F_CE,SDM_CE,EPS_CE,ACC_CE,EBCM_OBD_CE,EBCM_CE,RDCM_CE,SADS_CE
 SG_ IMURollCntPri : 6|2@0+ (1,0) [0|3] ""  APA_CE,FCM_CE,ICCM_CE,SDM_CE,EOCM_F_CE,EPS_JR_CE,EPS_CE,ACC_CE,EBCM_OBD_CE,EBCM_CE,RDCM_CE,SADS_CE
 SG_ IMUChksumPri : 50|11@0+ (1,0) [0|2047] ""  APA_CE,FCM_CE,ICCM_CE,SDM_CE,EOCM_F_CE,EPS_JR_CE,EPS_CE,EBCM_OBD_CE,EBCM_CE,RDCM_CE,SADS_CE,ACC_CE
 SG_ IMULonAccSec : 19|10@0- (0.0625,0) [-32|31.9375] "m/s^2"  APA_CE,FCM_CE,ICCM_CE,SADS_CE,RDCM_CE,EBCM_OBD_CE,EBCM_CE,ACC_CE,SDM_CE,EOCM_F_CE,EPS_JR_CE,EPS_CE
 SG_ IMULatAccPrim : 44|10@0- (0.0625,0) [-32|31.9375] "m/s^2"  FCM_CE,ICCM_CE,SDM_CE,APA_CE,EPS_JR_CE,EPS_CE,EOCM_F_CE,EBCM_OBD_CE,EBCM_CE,RDCM_CE,SADS_CE,ACC_CE
 SG_ IMULatAccPrimV : 7|1@0+ (1,0) [0|1] ""  FCM_CE,ICCM_CE,SDM_CE,APA_CE,EPS_JR_CE,EPS_CE,EOCM_F_CE,EBCM_OBD_CE,EBCM_CE,RDCM_CE,SADS_CE,ACC_CE

BO_ 289 System_Power_Mode_CE: 1 EBCM_CE
 SG_ SysPwMdVDA : 2|1@0+ (1,0) [0|1] ""  EBOOST_CE,TRCM_CE,EPS_JR_CE,MSB1_CE,MSB2_CE,SDM_CE,FCM_CE,IMU_CE,SAS_CE
 SG_ TrStLgMdAtv : 3|1@0+ (1,0) [0|1] ""  EBOOST_CE,TRCM_CE,EPS_JR_CE,MSB1_CE,MSB2_CE,FCM_CE,IMU_CE,SAS_CE
 SG_ SysPwrMd : 1|2@0+ (1,0) [0|3] ""  RDCM_CE,EBOOST_CE,TRCM_CE,EPS_JR_CE,MSB1_CE,MSB2_CE,SDM_CE,FCM_CE,IMU_CE,SAS_CE

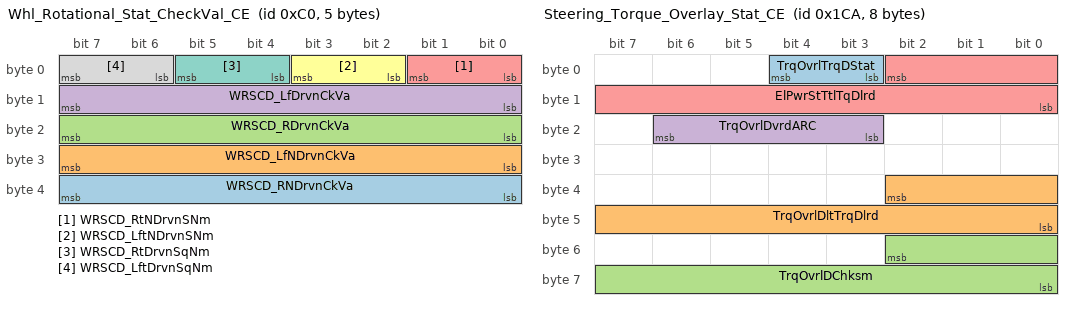
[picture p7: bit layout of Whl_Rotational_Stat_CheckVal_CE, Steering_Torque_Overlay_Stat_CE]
BO_ 192 Whl_Rotational_Stat_CheckVal_CE: 5 EBCM_CE
 SG_ WRSCD_RNDrvnCkVa : 39|8@0+ (1,0) [0|255] ""  EPS_JR_CE,ARS_CE,EOCM_F_CE
 SG_ WRSCD_LfNDrvnCkVa : 31|8@0+ (1,0) [0|255] ""  EPS_JR_CE,ARS_CE,EOCM_F_CE
 SG_ WRSCD_RDrvnCkVa : 23|8@0+ (1,0) [0|255] ""  EPS_JR_CE,ARS_CE,EOCM_F_CE
 SG_ WRSCD_LfDrvnCkVa : 15|8@0+ (1,0) [0|255] ""  EPS_JR_CE,ARS_CE,EOCM_F_CE
 SG_ WRSCD_RtNDrvnSNm : 1|2@0+ (1,0) [0|3] ""  EPS_JR_CE,ARS_CE,EOCM_F_CE
 SG_ WRSCD_LftNDrvnSNm : 3|2@0+ (1,0) [0|3] ""  EPS_JR_CE,ARS_CE,EOCM_F_CE
 SG_ WRSCD_RtDrvnSqNm : 5|2@0+ (1,0) [0|3] ""  EPS_JR_CE,ARS_CE,EOCM_F_CE
 SG_ WRSCD_LftDrvnSqNm : 7|2@0+ (1,0) [0|3] ""  EPS_JR_CE,ARS_CE,EOCM_F_CE

BO_ 328 Power_Steering_Information_CE: 1 EPS_JR_CE
 SG_ StrngAsstRdcdIO : 1|1@0+ (1,0) [0|1] ""  EBCM_OBD_CE,EBCM_CE
 SG_ PwrStrIO : 0|1@0+ (1,0) [0|1] ""  EBCM_OBD_CE,EBCM_CE

BO_ 458 Steering_Torque_Overlay_Stat_CE: 8 EPS_JR_CE
 SG_ TrqOvrlTrqDStat : 4|2@0+ (1,0) [0|3] ""  EBCM_OBD_CE,EBCM_CE
 SG_ TrqOvrlDltTrqDlrd : 34|11@0- (0.01,0) [-10.24|10.23] "Nm"  EBCM_OBD_CE,EBCM_CE
 SG_ TrqOvrlDChksm : 50|11@0+ (1,0) [0|2047] ""  EBCM_OBD_CE,EBCM_CE
 SG_ TrqOvrlDvrdARC : 22|4@0+ (1,0) [0|15] "counts"  EBCM_OBD_CE,EBCM_CE
 SG_ ElPwrStTtlTqDlrd : 2|11@0- (0.01,0) [-10.24|10.23] "Nm"  EBCM_OBD_CE,EBCM_CE

BO_TX_BU_ 832 : EBCM_OBD_CE,EBCM_CE;
BO_TX_BU_ 462 : EBCM_OBD_CE,EBCM_CE;
BO_TX_BU_ 368 : EBCM_OBD_CE,EBCM_CE;
BO_TX_BU_ 469 : EBCM_OBD_CE,EBCM_CE;
BO_TX_BU_ 1355 : EOCM_F_CE,FCM_CE;
BO_TX_BU_ 1354 : EPS_JR_CE,EPS_CE;
BO_TX_BU_ 1611 : EOCM_F_CE,FCM_CE;
BO_TX_BU_ 1610 : EPS_JR_CE,EPS_CE;
BO_TX_BU_ 320 : SDM_CE,IMU_CE;
BO_TX_BU_ 512 : EBCM_OBD_CE,EBCM_CE;
BO_TX_BU_ 290 : EBCM_OBD_CE,EBCM_CE;
BO_TX_BU_ 304 : SDM_CE,IMU_CE;
BO_TX_BU_ 289 : EBCM_OBD_CE,EBCM_CE;
BO_TX_BU_ 192 : EBCM_OBD_CE,EBCM_CE;
CM_ BO_ 805 "Application Is Tx ing this frame at the rate of 40 ms
";
CM_ SG_ 304 IMULatAccPrim "Inertial Measurement Unit Lateral Acceleration Primary";
CM_ BO_ 192 "Application Is Tx ing this frame at the rate of 10 ms";
BA_DEF_ SG_  "VNSigSLHS_VNReq" ENUM  "No","Yes";
BA_DEF_ SG_  "VNSigSLHSSharedDiagnostic" ENUM  "No","Yes";
BA_DEF_ SG_  "SignalType" STRING ;
BA_DEF_ SG_  "PacketOrder" INT 0 65535;
BA_DEF_ SG_  "SignalLongName" STRING ;
BA_DEF_ SG_  "GenSigStartValue" INT 0 65535;
BA_DEF_ SG_  "VNSigAllNodes" ENUM  "No","Yes";
BA_DEF_ SG_  "GenSigDeltaValue" INT 0 0;
BA_DEF_ SG_  "GenSigSendType" ENUM  "not used","not used","not used","not used","not used","not used","not used","NoSigSendType","not used","not used","OnAnyChange","OnChangeIfActive","OnDelta";
BA_DEF_ SG_  "GenSigSendOnInit" ENUM  "Not Initialized","Application","Handler";
BA_DEF_ BO_  "AppGenMsgCycleTime" INT 0 0;
BA_DEF_ BO_  "GenMsgILSupport" ENUM  "No","Yes";
BA_DEF_ BO_  "TpApplType" STRING ;
BA_DEF_ BO_  "Prio" INT 0 7;
BA_DEF_ BO_  "MessageSubnet" ENUM  "LS","MS","HS","CE","PE","HV","FO","S1","HE","LE","HE2";
BA_DEF_ BO_  "GenMsgMandatoryToSupervision" ENUM  "No","Yes";
BA_DEF_ BO_  "DiagState" ENUM  "No","Yes";
BA_DEF_ BO_  "GenMsgDelayTime" INT 0 100000;
BA_DEF_ BO_  "GenMsgCycleTime" INT 0 100000;
BA_DEF_ BO_  "GenMsgSendType" ENUM  "cyclicX","spontanX","cyclicIfActiveX","spontanWithDelay","cyclicAndSpontanX","cyclicAndSpontanWithDelay","spontanWithRepitition","cyclicIfActiveAndSpontanWD";
BA_DEF_ BO_  "DiagResponse" ENUM  "No","Yes";
BA_DEF_ BO_  "DiagRequest" ENUM  "No","Yes";
BA_DEF_ BO_  "NmMessage" ENUM  "No","Yes";
BA_DEF_REL_ BU_SG_REL_  "GenSigSuprvRespComment" STRING ;
BA_DEF_REL_ BU_SG_REL_  "GenSigVBitResp" ENUM  "No","Yes";
BA_DEF_REL_ BU_SG_REL_  "GenSigVBitRespComment" STRING ;
BA_DEF_REL_ BU_SG_REL_  "GenSigVDAFailComment" STRING ;
BA_DEF_REL_ BU_SG_REL_  "GenSigVDAFailResp" ENUM  "No","Yes";
BA_DEF_REL_ BU_SG_REL_  "GenSigRxStartValue" STRING ;
BA_DEF_REL_ BU_SG_REL_  "GenSigSuprvResp" ENUM  "None","Notify App","Substitute Default";
BA_DEF_REL_ BU_SG_REL_  "GenSigTimeoutMsg" HEX -2147483648 268435455;
BA_DEF_REL_ BU_SG_REL_  "GenSigTimeoutTime" INT 0 15000;
BA_DEF_DEF_  "VNSigSLHS_VNReq" "No";
BA_DEF_DEF_  "VNSigSLHSSharedDiagnostic" "No";
BA_DEF_DEF_  "SignalType" "";
BA_DEF_DEF_  "PacketOrder" 0;
BA_DEF_DEF_  "SignalLongName" "";
BA_DEF_DEF_  "GenSigStartValue" 0;
BA_DEF_DEF_  "VNSigAllNodes" "No";
BA_DEF_DEF_  "GenSigDeltaValue" 0;
BA_DEF_DEF_  "GenSigSendType" "NoSigSendType";
BA_DEF_DEF_  "GenSigSendOnInit" "Not Initialized";
BA_DEF_DEF_  "AppGenMsgCycleTime" 0;
BA_DEF_DEF_  "GenMsgILSupport" "Yes";
BA_DEF_DEF_  "TpApplType" "";
BA_DEF_DEF_  "Prio" 4;
BA_DEF_DEF_  "MessageSubnet" "FO";
BA_DEF_DEF_  "GenMsgMandatoryToSupervision" "No";
BA_DEF_DEF_  "DiagState" "No";
BA_DEF_DEF_  "GenMsgDelayTime" 0;
BA_DEF_DEF_  "GenMsgCycleTime" 0;
BA_DEF_DEF_  "GenMsgSendType" "spontanX";
BA_DEF_DEF_  "DiagResponse" "No";
BA_DEF_DEF_  "DiagRequest" "No";
BA_DEF_DEF_  "NmMessage" "No";
BA_DEF_DEF_REL_ "GenSigSuprvRespComment" "";
BA_DEF_DEF_REL_ "GenSigVBitResp" "No";
BA_DEF_DEF_REL_ "GenSigVBitRespComment" "";
BA_DEF_DEF_REL_ "GenSigVDAFailComment" "";
BA_DEF_DEF_REL_ "GenSigVDAFailResp" "No";
BA_DEF_DEF_REL_ "GenSigRxStartValue" "";
BA_DEF_DEF_REL_ "GenSigSuprvResp" "None";
BA_DEF_DEF_REL_ "GenSigTimeoutMsg" 0;
BA_DEF_DEF_REL_ "GenSigTimeoutTime" 0;
BA_ "GenMsgSendType" BO_ 832 0;
BA_ "GenMsgCycleTime" BO_ 832 100;
BA_ "MessageSubnet" BO_ 832 3;
BA_ "Prio" BO_ 832 0;
BA_ "GenMsgSendType" BO_ 462 0;
BA_ "GenMsgCycleTime" BO_ 462 20;
BA_ "MessageSubnet" BO_ 462 3;
BA_ "Prio" BO_ 462 0;
BA_ "GenMsgSendType" BO_ 368 0;
BA_ "GenMsgCycleTime" BO_ 368 10;
BA_ "MessageSubnet" BO_ 368 3;
BA_ "Prio" BO_ 368 0;
BA_ "GenMsgSendType" BO_ 469 0;
BA_ "GenMsgCycleTime" BO_ 469 20;
BA_ "MessageSubnet" BO_ 469 3;
BA_ "Prio" BO_ 469 0;
BA_ "GenMsgSendType" BO_ 467 0;
BA_ "GenMsgCycleTime" BO_ 467 20;
BA_ "MessageSubnet" BO_ 467 3;
BA_ "Prio" BO_ 467 0;
BA_ "GenMsgSendType" BO_ 352 0;
BA_ "GenMsgCycleTime" BO_ 352 10;
BA_ "MessageSubnet" BO_ 352 3;
BA_ "Prio" BO_ 352 0;
BA_ "MessageSubnet" BO_ 805 3;
BA_ "Prio" BO_ 805 0;
BA_ "AppGenMsgCycleTime" BO_ 805 40;
BA_ "DiagState" BO_ 257 1;
BA_ "MessageSubnet" BO_ 257 3;
BA_ "Prio" BO_ 257 0;
BA_ "GenMsgILSupport" BO_ 257 0;
BA_ "MessageSubnet" BO_ 1375 3;
BA_ "Prio" BO_ 1375 0;
BA_ "TpApplType" BO_ 1375 "DiagUUDTResponse";
BA_ "GenMsgILSupport" BO_ 1375 0;
BA_ "MessageSubnet" BO_ 1374 3;
BA_ "Prio" BO_ 1374 0;
BA_ "TpApplType" BO_ 1374 "DiagUUDTResponse";
BA_ "GenMsgILSupport" BO_ 1374 0;
BA_ "MessageSubnet" BO_ 1373 3;
BA_ "Prio" BO_ 1373 0;
BA_ "TpApplType" BO_ 1373 "DiagUUDTResponse";
BA_ "GenMsgILSupport" BO_ 1373 0;
BA_ "MessageSubnet" BO_ 1371 3;
BA_ "Prio" BO_ 1371 0;
BA_ "TpApplType" BO_ 1371 "DiagUUDTResponse";
BA_ "GenMsgILSupport" BO_ 1371 0;
BA_ "MessageSubnet" BO_ 1370 3;
BA_ "Prio" BO_ 1370 0;
BA_ "TpApplType" BO_ 1370 "DiagUUDTResponse";
BA_ "GenMsgILSupport" BO_ 1370 0;
BA_ "MessageSubnet" BO_ 1369 3;
BA_ "Prio" BO_ 1369 0;
BA_ "TpApplType" BO_ 1369 "DiagUUDTResponse";
BA_ "GenMsgILSupport" BO_ 1369 0;
BA_ "MessageSubnet" BO_ 1372 3;
BA_ "Prio" BO_ 1372 0;
BA_ "TpApplType" BO_ 1372 "DiagUUDTResponse";
BA_ "GenMsgILSupport" BO_ 1372 0;
BA_ "MessageSubnet" BO_ 1367 3;
BA_ "Prio" BO_ 1367 0;
BA_ "TpApplType" BO_ 1367 "DiagUUDTResponse";
BA_ "GenMsgILSupport" BO_ 1367 0;
BA_ "MessageSubnet" BO_ 1366 3;
BA_ "Prio" BO_ 1366 0;
BA_ "TpApplType" BO_ 1366 "DiagUUDTResponse";
BA_ "GenMsgILSupport" BO_ 1366 0;
BA_ "MessageSubnet" BO_ 1365 3;
BA_ "Prio" BO_ 1365 0;
BA_ "TpApplType" BO_ 1365 "DiagUUDTResponse";
BA_ "GenMsgILSupport" BO_ 1365 0;
BA_ "MessageSubnet" BO_ 1368 3;
BA_ "Prio" BO_ 1368 0;
BA_ "TpApplType" BO_ 1368 "DiagUUDTResponse";
BA_ "GenMsgILSupport" BO_ 1368 0;
BA_ "MessageSubnet" BO_ 1363 3;
BA_ "Prio" BO_ 1363 0;
BA_ "TpApplType" BO_ 1363 "DiagUUDTResponse";
BA_ "GenMsgILSupport" BO_ 1363 0;
BA_ "MessageSubnet" BO_ 1362 3;
BA_ "Prio" BO_ 1362 0;
BA_ "TpApplType" BO_ 1362 "DiagUUDTResponse";
BA_ "GenMsgILSupport" BO_ 1362 0;
BA_ "MessageSubnet" BO_ 1361 3;
BA_ "Prio" BO_ 1361 0;
BA_ "TpApplType" BO_ 1361 "DiagUUDTResponse";
BA_ "GenMsgILSupport" BO_ 1361 0;
BA_ "MessageSubnet" BO_ 1518 3;
BA_ "Prio" BO_ 1518 0;
BA_ "TpApplType" BO_ 1518 "DiagUUDTResponse";
BA_ "GenMsgILSupport" BO_ 1518 0;
BA_ "MessageSubnet" BO_ 1359 3;
BA_ "Prio" BO_ 1359 0;
BA_ "TpApplType" BO_ 1359 "DiagUUDTResponse";
BA_ "GenMsgILSupport" BO_ 1359 0;
BA_ "MessageSubnet" BO_ 1358 3;
BA_ "Prio" BO_ 1358 0;
BA_ "TpApplType" BO_ 1358 "DiagUUDTResponse";
BA_ "GenMsgILSupport" BO_ 1358 0;
BA_ "MessageSubnet" BO_ 1357 3;
BA_ "Prio" BO_ 1357 0;
BA_ "TpApplType" BO_ 1357 "DiagUUDTResponse";
BA_ "GenMsgILSupport" BO_ 1357 0;
BA_ "MessageSubnet" BO_ 1360 3;
BA_ "Prio" BO_ 1360 0;
BA_ "TpApplType" BO_ 1360 "DiagUUDTResponse";
BA_ "GenMsgILSupport" BO_ 1360 0;
BA_ "MessageSubnet" BO_ 1355 3;
BA_ "Prio" BO_ 1355 0;
BA_ "TpApplType" BO_ 1355 "DiagUUDTResponse";
BA_ "GenMsgILSupport" BO_ 1355 0;
BA_ "MessageSubnet" BO_ 1352 3;
BA_ "Prio" BO_ 1352 0;
BA_ "TpApplType" BO_ 1352 "DiagUUDTResponse";
BA_ "GenMsgILSupport" BO_ 1352 0;
BA_ "MessageSubnet" BO_ 1353 3;
BA_ "Prio" BO_ 1353 0;
BA_ "TpApplType" BO_ 1353 "DiagUUDTResponse";
BA_ "GenMsgILSupport" BO_ 1353 0;
BA_ "MessageSubnet" BO_ 1351 3;
BA_ "Prio" BO_ 1351 0;
BA_ "TpApplType" BO_ 1351 "DiagUUDTResponse";
BA_ "GenMsgILSupport" BO_ 1351 0;
BA_ "MessageSubnet" BO_ 1350 3;
BA_ "Prio" BO_ 1350 0;
BA_ "TpApplType" BO_ 1350 "DiagUUDTResponse";
BA_ "GenMsgILSupport" BO_ 1350 0;
BA_ "MessageSubnet" BO_ 1349 3;
BA_ "Prio" BO_ 1349 0;
BA_ "TpApplType" BO_ 1349 "DiagUUDTResponse";
BA_ "GenMsgILSupport" BO_ 1349 0;
BA_ "MessageSubnet" BO_ 1356 3;
BA_ "Prio" BO_ 1356 0;
BA_ "TpApplType" BO_ 1356 "DiagUUDTResponse";
BA_ "GenMsgILSupport" BO_ 1356 0;
BA_ "MessageSubnet" BO_ 1348 3;
BA_ "Prio" BO_ 1348 0;
BA_ "TpApplType" BO_ 1348 "DiagUUDTResponse";
BA_ "GenMsgILSupport" BO_ 1348 0;
BA_ "MessageSubnet" BO_ 1347 3;
BA_ "Prio" BO_ 1347 0;
BA_ "TpApplType" BO_ 1347 "DiagUUDTResponse";
BA_ "GenMsgILSupport" BO_ 1347 0;
BA_ "MessageSubnet" BO_ 1354 3;
BA_ "Prio" BO_ 1354 0;
BA_ "TpApplType" BO_ 1354 "DiagUUDTResponse";
BA_ "GenMsgILSupport" BO_ 1354 0;
BA_ "MessageSubnet" BO_ 1345 3;
BA_ "Prio" BO_ 1345 0;
BA_ "TpApplType" BO_ 1345 "DiagUUDTResponse";
BA_ "GenMsgILSupport" BO_ 1345 0;
BA_ "DiagResponse" BO_ 1631 1;
BA_ "MessageSubnet" BO_ 1631 3;
BA_ "Prio" BO_ 1631 0;
BA_ "DiagResponse" BO_ 1630 1;
BA_ "MessageSubnet" BO_ 1630 3;
BA_ "Prio" BO_ 1630 0;
BA_ "DiagResponse" BO_ 1629 1;
BA_ "MessageSubnet" BO_ 1629 3;
BA_ "Prio" BO_ 1629 0;
BA_ "GenMsgILSupport" BO_ 1629 0;
BA_ "DiagResponse" BO_ 1627 1;
BA_ "MessageSubnet" BO_ 1627 3;
BA_ "Prio" BO_ 1627 0;
BA_ "DiagResponse" BO_ 1626 1;
BA_ "MessageSubnet" BO_ 1626 3;
BA_ "Prio" BO_ 1626 0;
BA_ "DiagResponse" BO_ 1625 1;
BA_ "MessageSubnet" BO_ 1625 3;
BA_ "Prio" BO_ 1625 0;
BA_ "GenMsgILSupport" BO_ 1625 0;
BA_ "DiagResponse" BO_ 1628 1;
BA_ "MessageSubnet" BO_ 1628 3;
BA_ "Prio" BO_ 1628 0;
BA_ "GenMsgILSupport" BO_ 1628 0;
BA_ "DiagResponse" BO_ 1623 1;
BA_ "MessageSubnet" BO_ 1623 3;
BA_ "Prio" BO_ 1623 0;
BA_ "DiagResponse" BO_ 1622 1;
BA_ "MessageSubnet" BO_ 1622 3;
BA_ "Prio" BO_ 1622 0;
BA_ "DiagResponse" BO_ 1621 1;
BA_ "MessageSubnet" BO_ 1621 3;
BA_ "Prio" BO_ 1621 0;
BA_ "GenMsgILSupport" BO_ 1621 0;
BA_ "DiagResponse" BO_ 1624 1;
BA_ "MessageSubnet" BO_ 1624 3;
BA_ "Prio" BO_ 1624 0;
BA_ "DiagResponse" BO_ 1619 1;
BA_ "MessageSubnet" BO_ 1619 3;
BA_ "Prio" BO_ 1619 0;
BA_ "DiagResponse" BO_ 1618 1;
BA_ "MessageSubnet" BO_ 1618 3;
BA_ "Prio" BO_ 1618 0;
BA_ "DiagResponse" BO_ 1617 1;
BA_ "MessageSubnet" BO_ 1617 3;
BA_ "Prio" BO_ 1617 0;
BA_ "DiagResponse" BO_ 2030 1;
BA_ "MessageSubnet" BO_ 2030 3;
BA_ "Prio" BO_ 2030 0;
BA_ "DiagResponse" BO_ 1615 1;
BA_ "MessageSubnet" BO_ 1615 3;
BA_ "Prio" BO_ 1615 0;
BA_ "DiagResponse" BO_ 1614 1;
BA_ "MessageSubnet" BO_ 1614 3;
BA_ "Prio" BO_ 1614 0;
BA_ "DiagResponse" BO_ 1613 1;
BA_ "MessageSubnet" BO_ 1613 3;
BA_ "Prio" BO_ 1613 0;
BA_ "DiagResponse" BO_ 1616 1;
BA_ "MessageSubnet" BO_ 1616 3;
BA_ "Prio" BO_ 1616 0;
BA_ "DiagResponse" BO_ 1611 1;
BA_ "MessageSubnet" BO_ 1611 3;
BA_ "Prio" BO_ 1611 0;
BA_ "GenMsgILSupport" BO_ 1611 0;
BA_ "DiagResponse" BO_ 1608 1;
BA_ "MessageSubnet" BO_ 1608 3;
BA_ "Prio" BO_ 1608 0;
BA_ "DiagResponse" BO_ 1609 1;
BA_ "MessageSubnet" BO_ 1609 3;
BA_ "Prio" BO_ 1609 0;
BA_ "DiagResponse" BO_ 1607 1;
BA_ "MessageSubnet" BO_ 1607 3;
BA_ "Prio" BO_ 1607 0;
BA_ "GenMsgILSupport" BO_ 1607 0;
BA_ "DiagResponse" BO_ 1606 1;
BA_ "MessageSubnet" BO_ 1606 3;
BA_ "Prio" BO_ 1606 0;
BA_ "DiagResponse" BO_ 1605 1;
BA_ "MessageSubnet" BO_ 1605 3;
BA_ "Prio" BO_ 1605 0;
BA_ "DiagResponse" BO_ 1612 1;
BA_ "MessageSubnet" BO_ 1612 3;
BA_ "Prio" BO_ 1612 0;
BA_ "DiagResponse" BO_ 1604 1;
BA_ "MessageSubnet" BO_ 1604 3;
BA_ "Prio" BO_ 1604 0;
BA_ "DiagResponse" BO_ 1603 1;
BA_ "MessageSubnet" BO_ 1603 3;
BA_ "Prio" BO_ 1603 0;
BA_ "DiagResponse" BO_ 1610 1;
BA_ "MessageSubnet" BO_ 1610 3;
BA_ "Prio" BO_ 1610 0;
BA_ "DiagResponse" BO_ 1601 1;
BA_ "MessageSubnet" BO_ 1601 3;
BA_ "Prio" BO_ 1601 0;
BA_ "DiagRequest" BO_ 607 1;
BA_ "MessageSubnet" BO_ 607 3;
BA_ "Prio" BO_ 607 0;
BA_ "DiagRequest" BO_ 606 1;
BA_ "MessageSubnet" BO_ 606 3;
BA_ "Prio" BO_ 606 0;
BA_ "DiagRequest" BO_ 605 1;
BA_ "MessageSubnet" BO_ 605 3;
BA_ "Prio" BO_ 605 0;
BA_ "GenMsgILSupport" BO_ 605 0;
BA_ "DiagRequest" BO_ 604 1;
BA_ "MessageSubnet" BO_ 604 3;
BA_ "Prio" BO_ 604 0;
BA_ "GenMsgILSupport" BO_ 604 0;
BA_ "DiagRequest" BO_ 603 1;
BA_ "MessageSubnet" BO_ 603 3;
BA_ "Prio" BO_ 603 0;
BA_ "DiagRequest" BO_ 602 1;
BA_ "MessageSubnet" BO_ 602 3;
BA_ "Prio" BO_ 602 0;
BA_ "DiagRequest" BO_ 601 1;
BA_ "MessageSubnet" BO_ 601 3;
BA_ "Prio" BO_ 601 0;
BA_ "GenMsgILSupport" BO_ 601 0;
BA_ "DiagRequest" BO_ 600 1;
BA_ "MessageSubnet" BO_ 600 3;
BA_ "Prio" BO_ 600 0;
BA_ "DiagRequest" BO_ 599 1;
BA_ "MessageSubnet" BO_ 599 3;
BA_ "Prio" BO_ 599 0;
BA_ "DiagRequest" BO_ 598 1;
BA_ "MessageSubnet" BO_ 598 3;
BA_ "Prio" BO_ 598 0;
BA_ "DiagRequest" BO_ 597 1;
BA_ "MessageSubnet" BO_ 597 3;
BA_ "Prio" BO_ 597 0;
BA_ "GenMsgILSupport" BO_ 597 0;
BA_ "DiagRequest" BO_ 2022 1;
BA_ "MessageSubnet" BO_ 2022 3;
BA_ "Prio" BO_ 2022 0;
BA_ "DiagRequest" BO_ 595 1;
BA_ "MessageSubnet" BO_ 595 3;
BA_ "Prio" BO_ 595 0;
BA_ "DiagRequest" BO_ 594 1;
BA_ "MessageSubnet" BO_ 594 3;
BA_ "Prio" BO_ 594 0;
BA_ "DiagRequest" BO_ 593 1;
BA_ "MessageSubnet" BO_ 593 3;
BA_ "Prio" BO_ 593 0;
BA_ "DiagRequest" BO_ 592 1;
BA_ "MessageSubnet" BO_ 592 3;
BA_ "Prio" BO_ 592 0;
BA_ "DiagRequest" BO_ 591 1;
BA_ "MessageSubnet" BO_ 591 3;
BA_ "Prio" BO_ 591 0;
BA_ "DiagRequest" BO_ 590 1;
BA_ "MessageSubnet" BO_ 590 3;
BA_ "Prio" BO_ 590 0;
BA_ "DiagRequest" BO_ 589 1;
BA_ "MessageSubnet" BO_ 589 3;
BA_ "Prio" BO_ 589 0;
BA_ "DiagRequest" BO_ 585 1;
BA_ "MessageSubnet" BO_ 585 3;
BA_ "Prio" BO_ 585 0;
BA_ "DiagRequest" BO_ 587 1;
BA_ "MessageSubnet" BO_ 587 3;
BA_ "Prio" BO_ 587 0;
BA_ "DiagRequest" BO_ 584 1;
BA_ "MessageSubnet" BO_ 584 3;
BA_ "Prio" BO_ 584 0;
BA_ "DiagRequest" BO_ 588 1;
BA_ "MessageSubnet" BO_ 588 3;
BA_ "Prio" BO_ 588 0;
BA_ "DiagRequest" BO_ 583 1;
BA_ "MessageSubnet" BO_ 583 3;
BA_ "Prio" BO_ 583 0;
BA_ "GenMsgILSupport" BO_ 583 0;
BA_ "DiagRequest" BO_ 582 1;
BA_ "MessageSubnet" BO_ 582 3;
BA_ "Prio" BO_ 582 0;
BA_ "DiagRequest" BO_ 581 1;
BA_ "MessageSubnet" BO_ 581 3;
BA_ "Prio" BO_ 581 0;
BA_ "GenMsgSendType" BO_ 817 0;
BA_ "GenMsgCycleTime" BO_ 817 10;
BA_ "MessageSubnet" BO_ 817 3;
BA_ "Prio" BO_ 817 0;
BA_ "DiagRequest" BO_ 580 1;
BA_ "MessageSubnet" BO_ 580 3;
BA_ "Prio" BO_ 580 0;
BA_ "DiagRequest" BO_ 579 1;
BA_ "MessageSubnet" BO_ 579 3;
BA_ "Prio" BO_ 579 0;
BA_ "DiagRequest" BO_ 578 1;
BA_ "MessageSubnet" BO_ 578 3;
BA_ "Prio" BO_ 578 0;
BA_ "DiagRequest" BO_ 577 1;
BA_ "MessageSubnet" BO_ 577 3;
BA_ "Prio" BO_ 577 0;
BA_ "GenMsgSendType" BO_ 566 0;
BA_ "GenMsgCycleTime" BO_ 566 12;
BA_ "MessageSubnet" BO_ 566 3;
BA_ "Prio" BO_ 566 0;
BA_ "GenMsgSendType" BO_ 320 0;
BA_ "GenMsgCycleTime" BO_ 320 10;
BA_ "MessageSubnet" BO_ 320 3;
BA_ "Prio" BO_ 320 0;
BA_ "GenMsgSendType" BO_ 512 0;
BA_ "GenMsgCycleTime" BO_ 512 100;
BA_ "MessageSubnet" BO_ 512 3;
BA_ "Prio" BO_ 512 0;
BA_ "GenMsgSendType" BO_ 290 0;
BA_ "GenMsgCycleTime" BO_ 290 100;
BA_ "GenMsgMandatoryToSupervision" BO_ 290 1;
BA_ "MessageSubnet" BO_ 290 3;
BA_ "Prio" BO_ 290 0;
BA_ "GenMsgSendType" BO_ 304 0;
BA_ "GenMsgCycleTime" BO_ 304 10;
BA_ "MessageSubnet" BO_ 304 3;
BA_ "Prio" BO_ 304 0;
BA_ "GenMsgSendType" BO_ 289 0;
BA_ "GenMsgCycleTime" BO_ 289 100;
BA_ "MessageSubnet" BO_ 289 3;
BA_ "Prio" BO_ 289 0;
BA_ "MessageSubnet" BO_ 192 3;
BA_ "Prio" BO_ 192 0;
BA_ "AppGenMsgCycleTime" BO_ 192 10;
BA_ "GenMsgSendType" BO_ 328 0;
BA_ "GenMsgCycleTime" BO_ 328 1000;
BA_ "MessageSubnet" BO_ 328 3;
BA_ "Prio" BO_ 328 0;
BA_ "GenMsgSendType" BO_ 458 0;
BA_ "GenMsgCycleTime" BO_ 458 100;
BA_ "MessageSubnet" BO_ 458 3;
BA_ "Prio" BO_ 458 0;
BA_ "VNSigAllNodes" SG_ 832 BrkPedTrvlAchvd 1;
BA_ "SignalLongName" SG_ 832 BrkPedTrvlAchvd "Brake Pedal Initial Travel Achieved Status : Brake Pedal Initial Travel Achieved";
BA_ "PacketOrder" SG_ 832 BrkPedTrvlAchvd 1;
BA_ "SignalType" SG_ 832 BrkPedTrvlAchvd "BLN";
BA_ "VNSigAllNodes" SG_ 832 BrkPedTrvlAchvdV 1;
BA_ "SignalLongName" SG_ 832 BrkPedTrvlAchvdV "Brake Pedal Initial Travel Achieved Status : Brake Pedal Initial Travel Achieved Validity";
BA_ "PacketOrder" SG_ 832 BrkPedTrvlAchvdV 2;
BA_ "SignalType" SG_ 832 BrkPedTrvlAchvdV "ENM";
BA_ "VNSigAllNodes" SG_ 832 BrkPdlInTrvPrt 1;
BA_ "SignalLongName" SG_ 832 BrkPdlInTrvPrt "Brake Pedal Initial Travel Achieved Protection";
BA_ "SignalType" SG_ 832 BrkPdlInTrvPrt "UNM";
BA_ "VNSigAllNodes" SG_ 832 AccActPosV 1;
BA_ "SignalLongName" SG_ 832 AccActPosV "Accelerator Actual Position Validity";
BA_ "SignalType" SG_ 832 AccActPosV "ENM";
BA_ "VNSigAllNodes" SG_ 832 AccActPos 1;
BA_ "SignalLongName" SG_ 832 AccActPos "Accelerator Actual Position";
BA_ "SignalType" SG_ 832 AccActPos "UNM";
BA_ "VNSigAllNodes" SG_ 832 WhlDistPrRevNDrvn 1;
BA_ "SignalLongName" SG_ 832 WhlDistPrRevNDrvn "Wheel Distance Per Revolution Non Driven";
BA_ "SignalType" SG_ 832 WhlDistPrRevNDrvn "UNM";
BA_ "VNSigAllNodes" SG_ 832 WhlDistPrRevDrvn 1;
BA_ "SignalLongName" SG_ 832 WhlDistPrRevDrvn "Wheel Distance Per Revolution Driven";
BA_ "SignalType" SG_ 832 WhlDistPrRevDrvn "UNM";
BA_ "VNSigAllNodes" SG_ 462 SecAxlLkTqRqCplRqTp 1;
BA_ "SignalLongName" SG_ 462 SecAxlLkTqRqCplRqTp "Secondary Axle Locking Torque Request Coupling Request Type";
BA_ "SignalType" SG_ 462 SecAxlLkTqRqCplRqTp "ENM";
BA_ "VNSigAllNodes" SG_ 462 SecAxlTrqReqProtVal 1;
BA_ "SignalLongName" SG_ 462 SecAxlTrqReqProtVal "Secondary Axle Torque Request Protection Value";
BA_ "SignalType" SG_ 462 SecAxlTrqReqProtVal "UNM";
BA_ "VNSigAllNodes" SG_ 462 SecAxlTrqReqARollCnt 1;
BA_ "SignalLongName" SG_ 462 SecAxlTrqReqARollCnt "Secondary Axle Torque Request Alive Rolling Count";
BA_ "SignalType" SG_ 462 SecAxlTrqReqARollCnt "UNM";
BA_ "VNSigAllNodes" SG_ 462 SATRCplReqVal 1;
BA_ "SignalLongName" SG_ 462 SATRCplReqVal "Secondary Axle Torque Request : Coupling Request Value";
BA_ "PacketOrder" SG_ 462 SATRCplReqVal 2;
BA_ "SignalType" SG_ 462 SATRCplReqVal "UNM";
BA_ "VNSigAllNodes" SG_ 462 SATRCplReqAtv 1;
BA_ "SignalLongName" SG_ 462 SATRCplReqAtv "Secondary Axle Torque Request : Coupling Request Active";
BA_ "PacketOrder" SG_ 462 SATRCplReqAtv 1;
BA_ "SignalType" SG_ 462 SATRCplReqAtv "BLN";
BA_ "VNSigAllNodes" SG_ 368 BrkSysAutBrkTrgtDcl 1;
BA_ "SignalLongName" SG_ 368 BrkSysAutBrkTrgtDcl "Brake System Automatic Braking Target Deceleration";
BA_ "SignalType" SG_ 368 BrkSysAutBrkTrgtDcl "SNM";
BA_ "VNSigAllNodes" SG_ 368 BrkSysAutBrkActDcl 1;
BA_ "SignalLongName" SG_ 368 BrkSysAutBrkActDcl "Brake System Automatic Braking Actual Deceleration";
BA_ "SignalType" SG_ 368 BrkSysAutBrkActDcl "SNM";
BA_ "VNSigAllNodes" SG_ 368 AvgWhlBrkPrsrEst 1;
BA_ "SignalLongName" SG_ 368 AvgWhlBrkPrsrEst "Average Wheel Brake Pressure Estimated";
BA_ "SignalType" SG_ 368 AvgWhlBrkPrsrEst "UNM";
BA_ "VNSigAllNodes" SG_ 368 VehMvngStat 1;
BA_ "SignalLongName" SG_ 368 VehMvngStat "Vehicle Moving Status";
BA_ "SignalType" SG_ 368 VehMvngStat "ENM";
BA_ "VNSigAllNodes" SG_ 368 FSRACCBrkngReqDenied 1;
BA_ "SignalLongName" SG_ 368 FSRACCBrkngReqDenied "Full Speed Range Adaptive Cruise Control Braking Request Denied";
BA_ "SignalType" SG_ 368 FSRACCBrkngReqDenied "BLN";
BA_ "VNSigAllNodes" SG_ 368 BrkSysPlsStat 1;
BA_ "SignalLongName" SG_ 368 BrkSysPlsStat "Brake System Pulse Status";
BA_ "SignalType" SG_ 368 BrkSysPlsStat "ENM";
BA_ "VNSigAllNodes" SG_ 368 BrkSysAutBrkStat 1;
BA_ "SignalLongName" SG_ 368 BrkSysAutBrkStat "Brake System Automatic Braking Status";
BA_ "SignalType" SG_ 368 BrkSysAutBrkStat "ENM";
BA_ "VNSigAllNodes" SG_ 368 BrkSysExtHldCpbltyFld 1;
BA_ "SignalLongName" SG_ 368 BrkSysExtHldCpbltyFld "Brake System Extended Hold Capability Failed";
BA_ "SignalType" SG_ 368 BrkSysExtHldCpbltyFld "BLN";
BA_ "VNSigAllNodes" SG_ 368 BrkSysAutBrkTrgtDclV 1;
BA_ "SignalLongName" SG_ 368 BrkSysAutBrkTrgtDclV "Brake System Automatic Braking Target Deceleration Validity";
BA_ "SignalType" SG_ 368 BrkSysAutBrkTrgtDclV "ENM";
BA_ "VNSigAllNodes" SG_ 368 BrkSysAutBrkActDclV 1;
BA_ "SignalLongName" SG_ 368 BrkSysAutBrkActDclV "Brake System Automatic Braking Actual Deceleration Validity";
BA_ "SignalType" SG_ 368 BrkSysAutBrkActDclV "ENM";
BA_ "VNSigAllNodes" SG_ 469 TwnClRRAxlTrqRqPVal 1;
BA_ "SignalLongName" SG_ 469 TwnClRRAxlTrqRqPVal "Twin Clutch Right Rear Axle Torque Request Protection Value";
BA_ "SignalType" SG_ 469 TwnClRRAxlTrqRqPVal "UNM";
BA_ "VNSigAllNodes" SG_ 469 TwnClRRAxlTrqRqARC 1;
BA_ "SignalLongName" SG_ 469 TwnClRRAxlTrqRqARC "Twin Clutch Right Rear Axle Torque Request Alive Rolling Count";
BA_ "SignalType" SG_ 469 TwnClRRAxlTrqRqARC "UNM";
BA_ "VNSigAllNodes" SG_ 469 TCRRATR_CplReqVal 1;
BA_ "SignalLongName" SG_ 469 TCRRATR_CplReqVal "Twin Clutch Right Rear Axle Torque Request : Coupling Request Value";
BA_ "PacketOrder" SG_ 469 TCRRATR_CplReqVal 3;
BA_ "SignalType" SG_ 469 TCRRATR_CplReqVal "UNM";
BA_ "VNSigAllNodes" SG_ 469 TCRRATR_CplReqTp 1;
BA_ "SignalLongName" SG_ 469 TCRRATR_CplReqTp "Twin Clutch Right Rear Axle Torque Request : Coupling Request Type";
BA_ "PacketOrder" SG_ 469 TCRRATR_CplReqTp 2;
BA_ "SignalType" SG_ 469 TCRRATR_CplReqTp "ENM";
BA_ "VNSigAllNodes" SG_ 469 TCRRATR_CplReqAct 1;
BA_ "SignalLongName" SG_ 469 TCRRATR_CplReqAct "Twin Clutch Right Rear Axle Torque Request : Coupling Request Active";
BA_ "PacketOrder" SG_ 469 TCRRATR_CplReqAct 1;
BA_ "SignalType" SG_ 469 TCRRATR_CplReqAct "BLN";
BA_ "VNSigAllNodes" SG_ 469 TwnClLRAxlTrqRqPVal 1;
BA_ "SignalLongName" SG_ 469 TwnClLRAxlTrqRqPVal "Twin Clutch Left Rear Axle Torque Request Protection Value";
BA_ "SignalType" SG_ 469 TwnClLRAxlTrqRqPVal "UNM";
BA_ "VNSigAllNodes" SG_ 469 TwnClLRAxlTrqRqARC 1;
BA_ "SignalLongName" SG_ 469 TwnClLRAxlTrqRqARC "Twin Clutch Left Rear Axle Torque Request Alive Rolling Count";
BA_ "SignalType" SG_ 469 TwnClLRAxlTrqRqARC "UNM";
BA_ "VNSigAllNodes" SG_ 469 TCLRATR_CplReqVal 1;
BA_ "SignalLongName" SG_ 469 TCLRATR_CplReqVal "Twin Clutch Left Rear Axle Torque Request : Coupling Request Value";
BA_ "PacketOrder" SG_ 469 TCLRATR_CplReqVal 3;
BA_ "SignalType" SG_ 469 TCLRATR_CplReqVal "UNM";
BA_ "VNSigAllNodes" SG_ 469 TCLRATR_CplReqTp 1;
BA_ "SignalLongName" SG_ 469 TCLRATR_CplReqTp "Twin Clutch Left Rear Axle Torque Request : Coupling Request Type";
BA_ "PacketOrder" SG_ 469 TCLRATR_CplReqTp 2;
BA_ "SignalType" SG_ 469 TCLRATR_CplReqTp "ENM";
BA_ "VNSigAllNodes" SG_ 469 TCLRATR_CplReqAct 1;
BA_ "SignalLongName" SG_ 469 TCLRATR_CplReqAct "Twin Clutch Left Rear Axle Torque Request : Coupling Request Active";
BA_ "PacketOrder" SG_ 469 TCLRATR_CplReqAct 1;
BA_ "SignalType" SG_ 469 TCLRATR_CplReqAct "BLN";
BA_ "VNSigAllNodes" SG_ 467 TwnClThrmlProtReqAct 1;
BA_ "SignalLongName" SG_ 467 TwnClThrmlProtReqAct "Twin Clutch Thermal Protection Request Active";
BA_ "SignalType" SG_ 467 TwnClThrmlProtReqAct "BLN";
BA_ "VNSigAllNodes" SG_ 467 TwnCltchRrAxlRC 1;
BA_ "SignalLongName" SG_ 467 TwnCltchRrAxlRC "Twin Clutch Rear Axle Rolling Count";
BA_ "SignalType" SG_ 467 TwnCltchRrAxlRC "UNM";
BA_ "VNSigAllNodes" SG_ 467 TwnCltchRrAxlMd 1;
BA_ "SignalLongName" SG_ 467 TwnCltchRrAxlMd "Twin Clutch Rear Axle Mode";
BA_ "SignalType" SG_ 467 TwnCltchRrAxlMd "ENM";
BA_ "VNSigAllNodes" SG_ 467 TwnCltchRrAxlCtrlStat 1;
BA_ "SignalLongName" SG_ 467 TwnCltchRrAxlCtrlStat "Twin Clutch Rear Axle Control Status";
BA_ "SignalType" SG_ 467 TwnCltchRrAxlCtrlStat "ENM";
BA_ "VNSigAllNodes" SG_ 467 TwnCltchRrAxlChksm 1;
BA_ "SignalLongName" SG_ 467 TwnCltchRrAxlChksm "Twin Clutch Rear Axle Checksum";
BA_ "SignalType" SG_ 467 TwnCltchRrAxlChksm "UNM";
BA_ "VNSigAllNodes" SG_ 467 TwnClRrAxlThrmCapV 1;
BA_ "SignalLongName" SG_ 467 TwnClRrAxlThrmCapV "Twin Clutch Rear Axle Thermal Capacity Validity";
BA_ "SignalType" SG_ 467 TwnClRrAxlThrmCapV "ENM";
BA_ "VNSigAllNodes" SG_ 467 TwnClRrAxlThrmCap 1;
BA_ "SignalLongName" SG_ 467 TwnClRrAxlThrmCap "Twin Clutch Rear Axle Thermal Capacity";
BA_ "SignalType" SG_ 467 TwnClRrAxlThrmCap "UNM";
BA_ "VNSigAllNodes" SG_ 467 RtRrAxlEstTrqV 1;
BA_ "SignalLongName" SG_ 467 RtRrAxlEstTrqV "Right Rear Axle Estimated Torque Validity";
BA_ "SignalType" SG_ 467 RtRrAxlEstTrqV "ENM";
BA_ "VNSigAllNodes" SG_ 467 RtRrAxlEstTrqM 1;
BA_ "SignalLongName" SG_ 467 RtRrAxlEstTrqM "Right Rear Axle Estimated Torque Mask";
BA_ "SignalType" SG_ 467 RtRrAxlEstTrqM "ENM";
BA_ "VNSigAllNodes" SG_ 467 RtRrAxlEstTrq 1;
BA_ "SignalLongName" SG_ 467 RtRrAxlEstTrq "Right Rear Axle Estimated Torque";
BA_ "SignalType" SG_ 467 RtRrAxlEstTrq "UNM";
BA_ "VNSigAllNodes" SG_ 467 LtRrAxlEstTrqV 1;
BA_ "SignalLongName" SG_ 467 LtRrAxlEstTrqV "Left Rear Axle Estimated Torque Validity";
BA_ "SignalType" SG_ 467 LtRrAxlEstTrqV "ENM";
BA_ "VNSigAllNodes" SG_ 467 LtRrAxlEstTrqM 1;
BA_ "SignalLongName" SG_ 467 LtRrAxlEstTrqM "Left Rear Axle Estimated Torque Mask";
BA_ "SignalType" SG_ 467 LtRrAxlEstTrqM "ENM";
BA_ "VNSigAllNodes" SG_ 467 LtRrAxlEstTrq 1;
BA_ "SignalLongName" SG_ 467 LtRrAxlEstTrq "Left Rear Axle Estimated Torque";
BA_ "SignalType" SG_ 467 LtRrAxlEstTrq "UNM";
BA_ "VNSigAllNodes" SG_ 467 TwnCltchRrAxlCtrlMd 1;
BA_ "SignalLongName" SG_ 467 TwnCltchRrAxlCtrlMd "Twin Clutch Rear Axle Control Mode";
BA_ "SignalType" SG_ 467 TwnCltchRrAxlCtrlMd "ENM";
BA_ "VNSigAllNodes" SG_ 467 TwnCltchRrAxlStat 1;
BA_ "SignalLongName" SG_ 467 TwnCltchRrAxlStat "Twin Clutch Rear Axle Status";
BA_ "SignalType" SG_ 467 TwnCltchRrAxlStat "ENM";
BA_ "VNSigAllNodes" SG_ 352 RRDmpFrmnActValV 1;
BA_ "SignalLongName" SG_ 352 RRDmpFrmnActValV "Rear Right Damper Firmness Actual Value Validity";
BA_ "SignalType" SG_ 352 RRDmpFrmnActValV "ENM";
BA_ "VNSigAllNodes" SG_ 352 RLDmpFrmnActValV 1;
BA_ "SignalLongName" SG_ 352 RLDmpFrmnActValV "Rear Left Damper Firmness Actual Value Validity";
BA_ "SignalType" SG_ 352 RLDmpFrmnActValV "ENM";
BA_ "VNSigAllNodes" SG_ 352 FRDmpFrmnActValV 1;
BA_ "SignalLongName" SG_ 352 FRDmpFrmnActValV "Front Right Damper Firmness Actual Value Validity";
BA_ "SignalType" SG_ 352 FRDmpFrmnActValV "ENM";
BA_ "VNSigAllNodes" SG_ 352 FLDmpFrmnActValV 1;
BA_ "SignalLongName" SG_ 352 FLDmpFrmnActValV "Front Left Damper Firmness Actual Value Validity";
BA_ "SignalType" SG_ 352 FLDmpFrmnActValV "ENM";
BA_ "VNSigAllNodes" SG_ 352 DmpCtrlStat 1;
BA_ "SignalLongName" SG_ 352 DmpCtrlStat "Damper Control Status";
BA_ "SignalType" SG_ 352 DmpCtrlStat "ENM";
BA_ "VNSigAllNodes" SG_ 352 DmprStatARC 1;
BA_ "SignalLongName" SG_ 352 DmprStatARC "Damper Status Alive Rolling Count";
BA_ "SignalType" SG_ 352 DmprStatARC "UNM";
BA_ "VNSigAllNodes" SG_ 352 DmprStatChksm 1;
BA_ "SignalLongName" SG_ 352 DmprStatChksm "Damper Status Checksum";
BA_ "SignalType" SG_ 352 DmprStatChksm "UNM";
BA_ "VNSigAllNodes" SG_ 352 FLDmpFrmnActVal 1;
BA_ "SignalLongName" SG_ 352 FLDmpFrmnActVal "Front Left Damper Firmness Actual Value";
BA_ "SignalType" SG_ 352 FLDmpFrmnActVal "UNM";
BA_ "VNSigAllNodes" SG_ 352 FRDmpFrmnActVal 1;
BA_ "SignalLongName" SG_ 352 FRDmpFrmnActVal "Front Right Damper Firmness Actual Value";
BA_ "SignalType" SG_ 352 FRDmpFrmnActVal "UNM";
BA_ "VNSigAllNodes" SG_ 352 RLDmpFrmnActVal 1;
BA_ "SignalLongName" SG_ 352 RLDmpFrmnActVal "Rear Left Damper Firmness Actual Value";
BA_ "SignalType" SG_ 352 RLDmpFrmnActVal "UNM";
BA_ "VNSigAllNodes" SG_ 352 RRDmpFrmnActVal 1;
BA_ "SignalLongName" SG_ 352 RRDmpFrmnActVal "Rear Right Damper Firmness Actual Value";
BA_ "SignalType" SG_ 352 RRDmpFrmnActVal "UNM";
BA_ "VNSigAllNodes" SG_ 805 RrVrtBmpBrkPrfReq 1;
BA_ "SignalLongName" SG_ 805 RrVrtBmpBrkPrfReq "Rear Virtual Bumper Brake Prefill Request";
BA_ "SignalType" SG_ 805 RrVrtBmpBrkPrfReq "BLN";
BA_ "VNSigAllNodes" SG_ 805 RVBCtrlBrkSysCmdExtRC 1;
BA_ "SignalLongName" SG_ 805 RVBCtrlBrkSysCmdExtRC "Rear Virtual Bumper Control Brake System Command Extended Rolling Count";
BA_ "SignalType" SG_ 805 RVBCtrlBrkSysCmdExtRC "UNM";
BA_ "VNSigAllNodes" SG_ 805 RVBCtrlBrkSysCmdExtPVal 1;
BA_ "SignalLongName" SG_ 805 RVBCtrlBrkSysCmdExtPVal "Rear Virtual Bumper Control Brake System Command Extended Protection Value";
BA_ "SignalType" SG_ 805 RVBCtrlBrkSysCmdExtPVal "UNM";
BA_ "VNSigAllNodes" SG_ 805 RVBCBSCE_CtrlAcc 1;
BA_ "SignalLongName" SG_ 805 RVBCBSCE_CtrlAcc "Rear Virtual Bumper Control Brake System Command Extended : Control Acceleration";
BA_ "PacketOrder" SG_ 805 RVBCBSCE_CtrlAcc 3;
BA_ "SignalType" SG_ 805 RVBCBSCE_CtrlAcc "SNM";
BA_ "VNSigAllNodes" SG_ 805 RVBCBSCE_BrkPlsReq 1;
BA_ "SignalLongName" SG_ 805 RVBCBSCE_BrkPlsReq "Rear Virtual Bumper Control Brake System Command Extended : Brake Pulse Requested";
BA_ "PacketOrder" SG_ 805 RVBCBSCE_BrkPlsReq 2;
BA_ "SignalType" SG_ 805 RVBCBSCE_BrkPlsReq "BLN";
BA_ "VNSigAllNodes" SG_ 805 RVBCBSCE_AutoBrkReq 1;
BA_ "SignalLongName" SG_ 805 RVBCBSCE_AutoBrkReq "Rear Virtual Bumper Control Brake System Command Extended : Automatic Braking Requested";
BA_ "PacketOrder" SG_ 805 RVBCBSCE_AutoBrkReq 1;
BA_ "SignalType" SG_ 805 RVBCBSCE_AutoBrkReq "BLN";
BA_ "VNSigAllNodes" SG_ 805 RVBCBSCE_AutoBrkReqTyp 1;
BA_ "SignalLongName" SG_ 805 RVBCBSCE_AutoBrkReqTyp "Rear Virtual Bumper Control Brake System Command Extended : Automatic Braking Request Type";
BA_ "PacketOrder" SG_ 805 RVBCBSCE_AutoBrkReqTyp 4;
BA_ "SignalType" SG_ 805 RVBCBSCE_AutoBrkReqTyp "ENM";
BA_ "VNSigAllNodes" SG_ 257 DgnInf 1;
BA_ "SignalLongName" SG_ 257 DgnInf "Diagnostic Information";
BA_ "SignalType" SG_ 257 DgnInf "UNM";
BA_ "VNSigSLHSSharedDiagnostic" SG_ 257 DgnInf 1;
BA_ "VNSigAllNodes" SG_ 1375 DgnInf_CE55F 1;
BA_ "SignalLongName" SG_ 1375 DgnInf_CE55F "Diagnostic Information CE55F";
BA_ "SignalType" SG_ 1375 DgnInf_CE55F "UNM";
BA_ "VNSigSLHSSharedDiagnostic" SG_ 1375 DgnInf_CE55F 1;
BA_ "VNSigAllNodes" SG_ 1374 DgnInf_CE55E 1;
BA_ "SignalLongName" SG_ 1374 DgnInf_CE55E "Diagnostic Information CE55E";
BA_ "SignalType" SG_ 1374 DgnInf_CE55E "UNM";
BA_ "VNSigSLHSSharedDiagnostic" SG_ 1374 DgnInf_CE55E 1;
BA_ "VNSigAllNodes" SG_ 1373 DgnInf_CE55D 1;
BA_ "SignalLongName" SG_ 1373 DgnInf_CE55D "Diagnostic Information CE55D";
BA_ "SignalType" SG_ 1373 DgnInf_CE55D "UNM";
BA_ "VNSigSLHSSharedDiagnostic" SG_ 1373 DgnInf_CE55D 1;
BA_ "VNSigAllNodes" SG_ 1371 DgnInf_CE55B 1;
BA_ "SignalLongName" SG_ 1371 DgnInf_CE55B "Diagnostic Information CE55B";
BA_ "SignalType" SG_ 1371 DgnInf_CE55B "UNM";
BA_ "VNSigSLHSSharedDiagnostic" SG_ 1371 DgnInf_CE55B 1;
BA_ "VNSigAllNodes" SG_ 1370 DgnInf_CE55A 1;
BA_ "SignalLongName" SG_ 1370 DgnInf_CE55A "Diagnostic Information CE55A";
BA_ "SignalType" SG_ 1370 DgnInf_CE55A "UNM";
BA_ "VNSigSLHSSharedDiagnostic" SG_ 1370 DgnInf_CE55A 1;
BA_ "VNSigAllNodes" SG_ 1369 DgnInf_CE559 1;
BA_ "SignalLongName" SG_ 1369 DgnInf_CE559 "Diagnostic Information CE559";
BA_ "SignalType" SG_ 1369 DgnInf_CE559 "UNM";
BA_ "VNSigSLHSSharedDiagnostic" SG_ 1369 DgnInf_CE559 1;
BA_ "VNSigAllNodes" SG_ 1372 DgnInf_CE55C 1;
BA_ "SignalLongName" SG_ 1372 DgnInf_CE55C "Diagnostic Information CE55C";
BA_ "SignalType" SG_ 1372 DgnInf_CE55C "UNM";
BA_ "VNSigSLHSSharedDiagnostic" SG_ 1372 DgnInf_CE55C 1;
BA_ "VNSigAllNodes" SG_ 1367 DgnInf_CE557 1;
BA_ "SignalLongName" SG_ 1367 DgnInf_CE557 "Diagnostic Information CE557";
BA_ "SignalType" SG_ 1367 DgnInf_CE557 "UNM";
BA_ "VNSigSLHSSharedDiagnostic" SG_ 1367 DgnInf_CE557 1;
BA_ "VNSigAllNodes" SG_ 1366 DgnInf_CE556 1;
BA_ "SignalLongName" SG_ 1366 DgnInf_CE556 "Diagnostic Information CE556";
BA_ "SignalType" SG_ 1366 DgnInf_CE556 "UNM";
BA_ "VNSigSLHSSharedDiagnostic" SG_ 1366 DgnInf_CE556 1;
BA_ "VNSigAllNodes" SG_ 1365 DgnInf_CE555 1;
BA_ "SignalLongName" SG_ 1365 DgnInf_CE555 "Diagnostic Information CE555";
BA_ "SignalType" SG_ 1365 DgnInf_CE555 "UNM";
BA_ "VNSigSLHSSharedDiagnostic" SG_ 1365 DgnInf_CE555 1;
BA_ "GenSigDeltaValue" SG_ 1365 DgnInf_CE555 1;
BA_ "VNSigAllNodes" SG_ 1368 DgnInf_CE558 1;
BA_ "SignalLongName" SG_ 1368 DgnInf_CE558 "Diagnostic Information CE558";
BA_ "SignalType" SG_ 1368 DgnInf_CE558 "UNM";
BA_ "VNSigSLHSSharedDiagnostic" SG_ 1368 DgnInf_CE558 1;
BA_ "VNSigAllNodes" SG_ 1363 DgnInf_CE553 1;
BA_ "SignalLongName" SG_ 1363 DgnInf_CE553 "Diagnostic Information CE553";
BA_ "SignalType" SG_ 1363 DgnInf_CE553 "UNM";
BA_ "VNSigSLHSSharedDiagnostic" SG_ 1363 DgnInf_CE553 1;
BA_ "VNSigAllNodes" SG_ 1362 DgnInf_CE552 1;
BA_ "SignalLongName" SG_ 1362 DgnInf_CE552 "Diagnostic Information CE552";
BA_ "SignalType" SG_ 1362 DgnInf_CE552 "UNM";
BA_ "VNSigSLHSSharedDiagnostic" SG_ 1362 DgnInf_CE552 1;
BA_ "VNSigAllNodes" SG_ 1361 DgnInf_CE551 1;
BA_ "SignalLongName" SG_ 1361 DgnInf_CE551 "Diagnostic Information CE551";
BA_ "SignalType" SG_ 1361 DgnInf_CE551 "UNM";
BA_ "VNSigSLHSSharedDiagnostic" SG_ 1361 DgnInf_CE551 1;
BA_ "VNSigAllNodes" SG_ 1518 DgnInf_CE554 1;
BA_ "SignalLongName" SG_ 1518 DgnInf_CE554 "Diagnostic Information CE554";
BA_ "SignalType" SG_ 1518 DgnInf_CE554 "UNM";
BA_ "VNSigSLHSSharedDiagnostic" SG_ 1518 DgnInf_CE554 1;
BA_ "VNSigAllNodes" SG_ 1359 DgnInf_CE54F 1;
BA_ "SignalLongName" SG_ 1359 DgnInf_CE54F "Diagnostic Information CE54F";
BA_ "SignalType" SG_ 1359 DgnInf_CE54F "UNM";
BA_ "VNSigSLHSSharedDiagnostic" SG_ 1359 DgnInf_CE54F 1;
BA_ "VNSigAllNodes" SG_ 1358 DgnInf_CE54E 1;
BA_ "SignalLongName" SG_ 1358 DgnInf_CE54E "Diagnostic Information CE54E";
BA_ "SignalType" SG_ 1358 DgnInf_CE54E "UNM";
BA_ "VNSigSLHSSharedDiagnostic" SG_ 1358 DgnInf_CE54E 1;
BA_ "VNSigAllNodes" SG_ 1357 DgnInf_CE54D 1;
BA_ "SignalLongName" SG_ 1357 DgnInf_CE54D "Diagnostic Information CE54D";
BA_ "SignalType" SG_ 1357 DgnInf_CE54D "UNM";
BA_ "VNSigSLHSSharedDiagnostic" SG_ 1357 DgnInf_CE54D 1;
BA_ "VNSigAllNodes" SG_ 1360 DgnInf_CE550 1;
BA_ "SignalLongName" SG_ 1360 DgnInf_CE550 "Diagnostic Information CE550";
BA_ "SignalType" SG_ 1360 DgnInf_CE550 "UNM";
BA_ "VNSigSLHSSharedDiagnostic" SG_ 1360 DgnInf_CE550 1;
BA_ "VNSigAllNodes" SG_ 1355 DgnInf_CE54B 1;
BA_ "SignalLongName" SG_ 1355 DgnInf_CE54B "Diagnostic Information CE54B";
BA_ "SignalType" SG_ 1355 DgnInf_CE54B "UNM";
BA_ "VNSigSLHSSharedDiagnostic" SG_ 1355 DgnInf_CE54B 1;
BA_ "VNSigAllNodes" SG_ 1352 DgnInf_CE548 1;
BA_ "SignalLongName" SG_ 1352 DgnInf_CE548 "Diagnostic Information CE548";
BA_ "SignalType" SG_ 1352 DgnInf_CE548 "UNM";
BA_ "VNSigSLHSSharedDiagnostic" SG_ 1352 DgnInf_CE548 1;
BA_ "VNSigAllNodes" SG_ 1353 DgnInf_CE549 1;
BA_ "SignalLongName" SG_ 1353 DgnInf_CE549 "Diagnostic Information CE549";
BA_ "SignalType" SG_ 1353 DgnInf_CE549 "UNM";
BA_ "VNSigSLHSSharedDiagnostic" SG_ 1353 DgnInf_CE549 1;
BA_ "VNSigAllNodes" SG_ 1351 DgnInf_CE547 1;
BA_ "SignalLongName" SG_ 1351 DgnInf_CE547 "Diagnostic Information CE547";
BA_ "SignalType" SG_ 1351 DgnInf_CE547 "UNM";
BA_ "VNSigSLHSSharedDiagnostic" SG_ 1351 DgnInf_CE547 1;
BA_ "VNSigAllNodes" SG_ 1350 DgnInf_CE546 1;
BA_ "SignalLongName" SG_ 1350 DgnInf_CE546 "Diagnostic Information CE546";
BA_ "SignalType" SG_ 1350 DgnInf_CE546 "UNM";
BA_ "VNSigSLHSSharedDiagnostic" SG_ 1350 DgnInf_CE546 1;
BA_ "VNSigAllNodes" SG_ 1349 DgnInf_CE545 1;
BA_ "SignalLongName" SG_ 1349 DgnInf_CE545 "Diagnostic Information CE545";
BA_ "SignalType" SG_ 1349 DgnInf_CE545 "UNM";
BA_ "VNSigSLHSSharedDiagnostic" SG_ 1349 DgnInf_CE545 1;
BA_ "VNSigAllNodes" SG_ 1356 DgnInf_CE54C 1;
BA_ "SignalLongName" SG_ 1356 DgnInf_CE54C "Diagnostic Information CE54C";
BA_ "SignalType" SG_ 1356 DgnInf_CE54C "UNM";
BA_ "VNSigSLHSSharedDiagnostic" SG_ 1356 DgnInf_CE54C 1;
BA_ "VNSigAllNodes" SG_ 1348 DgnInf_CE544 1;
BA_ "SignalLongName" SG_ 1348 DgnInf_CE544 "Diagnostic Information CE544";
BA_ "SignalType" SG_ 1348 DgnInf_CE544 "UNM";
BA_ "VNSigSLHSSharedDiagnostic" SG_ 1348 DgnInf_CE544 1;
BA_ "VNSigAllNodes" SG_ 1347 DgnInf_CE543 1;
BA_ "SignalLongName" SG_ 1347 DgnInf_CE543 "Diagnostic Information CE543";
BA_ "SignalType" SG_ 1347 DgnInf_CE543 "UNM";
BA_ "VNSigSLHSSharedDiagnostic" SG_ 1347 DgnInf_CE543 1;
BA_ "VNSigAllNodes" SG_ 1354 DgnInf_CE542 1;
BA_ "SignalLongName" SG_ 1354 DgnInf_CE542 "Diagnostic Information CE542";
BA_ "SignalType" SG_ 1354 DgnInf_CE542 "UNM";
BA_ "VNSigSLHSSharedDiagnostic" SG_ 1354 DgnInf_CE542 1;
BA_ "VNSigAllNodes" SG_ 1345 DgnInf_CE541 1;
BA_ "SignalLongName" SG_ 1345 DgnInf_CE541 "Diagnostic Information CE541";
BA_ "SignalType" SG_ 1345 DgnInf_CE541 "UNM";
BA_ "VNSigSLHSSharedDiagnostic" SG_ 1345 DgnInf_CE541 1;
BA_ "VNSigAllNodes" SG_ 1631 DgnInf 1;
BA_ "SignalLongName" SG_ 1631 DgnInf "Diagnostic Information";
BA_ "SignalType" SG_ 1631 DgnInf "UNM";
BA_ "VNSigSLHSSharedDiagnostic" SG_ 1631 DgnInf 1;
BA_ "VNSigAllNodes" SG_ 1630 DgnInf 1;
BA_ "SignalLongName" SG_ 1630 DgnInf "Diagnostic Information";
BA_ "SignalType" SG_ 1630 DgnInf "UNM";
BA_ "VNSigSLHSSharedDiagnostic" SG_ 1630 DgnInf 1;
BA_ "VNSigAllNodes" SG_ 1629 DgnInf 1;
BA_ "SignalLongName" SG_ 1629 DgnInf "Diagnostic Information";
BA_ "SignalType" SG_ 1629 DgnInf "UNM";
BA_ "VNSigSLHSSharedDiagnostic" SG_ 1629 DgnInf 1;
BA_ "VNSigAllNodes" SG_ 1627 DgnInf 1;
BA_ "SignalLongName" SG_ 1627 DgnInf "Diagnostic Information";
BA_ "SignalType" SG_ 1627 DgnInf "UNM";
BA_ "VNSigSLHSSharedDiagnostic" SG_ 1627 DgnInf 1;
BA_ "VNSigAllNodes" SG_ 1626 DgnInf 1;
BA_ "SignalLongName" SG_ 1626 DgnInf "Diagnostic Information";
BA_ "SignalType" SG_ 1626 DgnInf "UNM";
BA_ "VNSigSLHSSharedDiagnostic" SG_ 1626 DgnInf 1;
BA_ "VNSigAllNodes" SG_ 1625 DgnInf 1;
BA_ "SignalLongName" SG_ 1625 DgnInf "Diagnostic Information";
BA_ "SignalType" SG_ 1625 DgnInf "UNM";
BA_ "VNSigSLHSSharedDiagnostic" SG_ 1625 DgnInf 1;
BA_ "VNSigAllNodes" SG_ 1628 DgnInf 1;
BA_ "SignalLongName" SG_ 1628 DgnInf "Diagnostic Information";
BA_ "SignalType" SG_ 1628 DgnInf "UNM";
BA_ "VNSigSLHSSharedDiagnostic" SG_ 1628 DgnInf 1;
BA_ "VNSigAllNodes" SG_ 1623 DgnInf 1;
BA_ "SignalLongName" SG_ 1623 DgnInf "Diagnostic Information";
BA_ "SignalType" SG_ 1623 DgnInf "UNM";
BA_ "VNSigSLHSSharedDiagnostic" SG_ 1623 DgnInf 1;
BA_ "VNSigAllNodes" SG_ 1622 DgnInf 1;
BA_ "SignalLongName" SG_ 1622 DgnInf "Diagnostic Information";
BA_ "SignalType" SG_ 1622 DgnInf "UNM";
BA_ "VNSigSLHSSharedDiagnostic" SG_ 1622 DgnInf 1;
BA_ "VNSigAllNodes" SG_ 1621 DgnInf 1;
BA_ "SignalLongName" SG_ 1621 DgnInf "Diagnostic Information";
BA_ "SignalType" SG_ 1621 DgnInf "UNM";
BA_ "VNSigSLHSSharedDiagnostic" SG_ 1621 DgnInf 1;
BA_ "VNSigAllNodes" SG_ 1624 DgnInf 1;
BA_ "SignalLongName" SG_ 1624 DgnInf "Diagnostic Information";
BA_ "SignalType" SG_ 1624 DgnInf "UNM";
BA_ "VNSigSLHSSharedDiagnostic" SG_ 1624 DgnInf 1;
BA_ "VNSigAllNodes" SG_ 1619 DgnInf 1;
BA_ "SignalLongName" SG_ 1619 DgnInf "Diagnostic Information";
BA_ "SignalType" SG_ 1619 DgnInf "UNM";
BA_ "VNSigSLHSSharedDiagnostic" SG_ 1619 DgnInf 1;
BA_ "VNSigAllNodes" SG_ 1618 DgnInf 1;
BA_ "SignalLongName" SG_ 1618 DgnInf "Diagnostic Information";
BA_ "SignalType" SG_ 1618 DgnInf "UNM";
BA_ "VNSigSLHSSharedDiagnostic" SG_ 1618 DgnInf 1;
BA_ "VNSigAllNodes" SG_ 1617 DgnInf 1;
BA_ "SignalLongName" SG_ 1617 DgnInf "Diagnostic Information";
BA_ "SignalType" SG_ 1617 DgnInf "UNM";
BA_ "VNSigSLHSSharedDiagnostic" SG_ 1617 DgnInf 1;
BA_ "VNSigAllNodes" SG_ 2030 DgnInf 1;
BA_ "SignalLongName" SG_ 2030 DgnInf "Diagnostic Information";
BA_ "SignalType" SG_ 2030 DgnInf "UNM";
BA_ "VNSigSLHSSharedDiagnostic" SG_ 2030 DgnInf 1;
BA_ "VNSigAllNodes" SG_ 1615 DgnInf 1;
BA_ "SignalLongName" SG_ 1615 DgnInf "Diagnostic Information";
BA_ "SignalType" SG_ 1615 DgnInf "UNM";
BA_ "VNSigSLHSSharedDiagnostic" SG_ 1615 DgnInf 1;
BA_ "VNSigAllNodes" SG_ 1614 DgnInf 1;
BA_ "SignalLongName" SG_ 1614 DgnInf "Diagnostic Information";
BA_ "SignalType" SG_ 1614 DgnInf "UNM";
BA_ "VNSigSLHSSharedDiagnostic" SG_ 1614 DgnInf 1;
BA_ "VNSigAllNodes" SG_ 1613 DgnInf 1;
BA_ "SignalLongName" SG_ 1613 DgnInf "Diagnostic Information";
BA_ "SignalType" SG_ 1613 DgnInf "UNM";
BA_ "VNSigSLHSSharedDiagnostic" SG_ 1613 DgnInf 1;
BA_ "VNSigAllNodes" SG_ 1616 DgnInf 1;
BA_ "SignalLongName" SG_ 1616 DgnInf "Diagnostic Information";
BA_ "SignalType" SG_ 1616 DgnInf "UNM";
BA_ "VNSigSLHSSharedDiagnostic" SG_ 1616 DgnInf 1;
BA_ "VNSigAllNodes" SG_ 1611 DgnInf 1;
BA_ "SignalLongName" SG_ 1611 DgnInf "Diagnostic Information";
BA_ "SignalType" SG_ 1611 DgnInf "UNM";
BA_ "VNSigSLHSSharedDiagnostic" SG_ 1611 DgnInf 1;
BA_ "VNSigAllNodes" SG_ 1608 DgnInf 1;
BA_ "SignalLongName" SG_ 1608 DgnInf "Diagnostic Information";
BA_ "SignalType" SG_ 1608 DgnInf "UNM";
BA_ "VNSigSLHSSharedDiagnostic" SG_ 1608 DgnInf 1;
BA_ "VNSigAllNodes" SG_ 1609 DgnInf 1;
BA_ "SignalLongName" SG_ 1609 DgnInf "Diagnostic Information";
BA_ "SignalType" SG_ 1609 DgnInf "UNM";
BA_ "VNSigSLHSSharedDiagnostic" SG_ 1609 DgnInf 1;
BA_ "VNSigAllNodes" SG_ 1607 DgnInf 1;
BA_ "SignalLongName" SG_ 1607 DgnInf "Diagnostic Information";
BA_ "SignalType" SG_ 1607 DgnInf "UNM";
BA_ "VNSigSLHSSharedDiagnostic" SG_ 1607 DgnInf 1;
BA_ "VNSigAllNodes" SG_ 1606 DgnInf 1;
BA_ "SignalLongName" SG_ 1606 DgnInf "Diagnostic Information";
BA_ "SignalType" SG_ 1606 DgnInf "UNM";
BA_ "VNSigSLHSSharedDiagnostic" SG_ 1606 DgnInf 1;
BA_ "VNSigAllNodes" SG_ 1605 DgnInf 1;
BA_ "SignalLongName" SG_ 1605 DgnInf "Diagnostic Information";
BA_ "SignalType" SG_ 1605 DgnInf "UNM";
BA_ "VNSigSLHSSharedDiagnostic" SG_ 1605 DgnInf 1;
BA_ "VNSigAllNodes" SG_ 1612 DgnInf 1;
BA_ "SignalLongName" SG_ 1612 DgnInf "Diagnostic Information";
BA_ "SignalType" SG_ 1612 DgnInf "UNM";
BA_ "VNSigSLHSSharedDiagnostic" SG_ 1612 DgnInf 1;
BA_ "VNSigAllNodes" SG_ 1604 DgnInf 1;
BA_ "SignalLongName" SG_ 1604 DgnInf "Diagnostic Information";
BA_ "SignalType" SG_ 1604 DgnInf "UNM";
BA_ "VNSigSLHSSharedDiagnostic" SG_ 1604 DgnInf 1;
BA_ "VNSigAllNodes" SG_ 1603 DgnInf 1;
BA_ "SignalLongName" SG_ 1603 DgnInf "Diagnostic Information";
BA_ "SignalType" SG_ 1603 DgnInf "UNM";
BA_ "VNSigSLHSSharedDiagnostic" SG_ 1603 DgnInf 1;
BA_ "VNSigAllNodes" SG_ 1610 DgnInf 1;
BA_ "SignalLongName" SG_ 1610 DgnInf "Diagnostic Information";
BA_ "SignalType" SG_ 1610 DgnInf "UNM";
BA_ "VNSigSLHSSharedDiagnostic" SG_ 1610 DgnInf 1;
BA_ "VNSigAllNodes" SG_ 1601 DgnInf 1;
BA_ "SignalLongName" SG_ 1601 DgnInf "Diagnostic Information";
BA_ "SignalType" SG_ 1601 DgnInf "UNM";
BA_ "VNSigSLHSSharedDiagnostic" SG_ 1601 DgnInf 1;
BA_ "VNSigAllNodes" SG_ 607 DgnInf 1;
BA_ "SignalLongName" SG_ 607 DgnInf "Diagnostic Information";
BA_ "SignalType" SG_ 607 DgnInf "UNM";
BA_ "VNSigSLHSSharedDiagnostic" SG_ 607 DgnInf 1;
BA_ "VNSigAllNodes" SG_ 606 DgnInf 1;
BA_ "SignalLongName" SG_ 606 DgnInf "Diagnostic Information";
BA_ "SignalType" SG_ 606 DgnInf "UNM";
BA_ "VNSigSLHSSharedDiagnostic" SG_ 606 DgnInf 1;
BA_ "VNSigAllNodes" SG_ 605 DgnInf 1;
BA_ "SignalLongName" SG_ 605 DgnInf "Diagnostic Information";
BA_ "SignalType" SG_ 605 DgnInf "UNM";
BA_ "VNSigSLHSSharedDiagnostic" SG_ 605 DgnInf 1;
BA_ "VNSigAllNodes" SG_ 604 DgnInf 1;
BA_ "SignalLongName" SG_ 604 DgnInf "Diagnostic Information";
BA_ "SignalType" SG_ 604 DgnInf "UNM";
BA_ "VNSigSLHSSharedDiagnostic" SG_ 604 DgnInf 1;
BA_ "VNSigAllNodes" SG_ 603 DgnInf 1;
BA_ "SignalLongName" SG_ 603 DgnInf "Diagnostic Information";
BA_ "SignalType" SG_ 603 DgnInf "UNM";
BA_ "VNSigSLHSSharedDiagnostic" SG_ 603 DgnInf 1;
BA_ "VNSigAllNodes" SG_ 602 DgnInf 1;
BA_ "SignalLongName" SG_ 602 DgnInf "Diagnostic Information";
BA_ "SignalType" SG_ 602 DgnInf "UNM";
BA_ "VNSigSLHSSharedDiagnostic" SG_ 602 DgnInf 1;
BA_ "VNSigAllNodes" SG_ 601 DgnInf 1;
BA_ "SignalLongName" SG_ 601 DgnInf "Diagnostic Information";
BA_ "SignalType" SG_ 601 DgnInf "UNM";
BA_ "VNSigSLHSSharedDiagnostic" SG_ 601 DgnInf 1;
BA_ "VNSigAllNodes" SG_ 600 DgnInf 1;
BA_ "SignalLongName" SG_ 600 DgnInf "Diagnostic Information";
BA_ "SignalType" SG_ 600 DgnInf "UNM";
BA_ "VNSigSLHSSharedDiagnostic" SG_ 600 DgnInf 1;
BA_ "VNSigAllNodes" SG_ 599 DgnInf 1;
BA_ "SignalLongName" SG_ 599 DgnInf "Diagnostic Information";
BA_ "SignalType" SG_ 599 DgnInf "UNM";
BA_ "VNSigSLHSSharedDiagnostic" SG_ 599 DgnInf 1;
BA_ "VNSigAllNodes" SG_ 598 DgnInf 1;
BA_ "SignalLongName" SG_ 598 DgnInf "Diagnostic Information";
BA_ "SignalType" SG_ 598 DgnInf "UNM";
BA_ "VNSigSLHSSharedDiagnostic" SG_ 598 DgnInf 1;
BA_ "VNSigAllNodes" SG_ 597 DgnInf 1;
BA_ "SignalLongName" SG_ 597 DgnInf "Diagnostic Information";
BA_ "SignalType" SG_ 597 DgnInf "UNM";
BA_ "VNSigSLHSSharedDiagnostic" SG_ 597 DgnInf 1;
BA_ "VNSigAllNodes" SG_ 2022 DgnInf 1;
BA_ "SignalLongName" SG_ 2022 DgnInf "Diagnostic Information";
BA_ "SignalType" SG_ 2022 DgnInf "UNM";
BA_ "VNSigSLHSSharedDiagnostic" SG_ 2022 DgnInf 1;
BA_ "VNSigAllNodes" SG_ 595 DgnInf 1;
BA_ "SignalLongName" SG_ 595 DgnInf "Diagnostic Information";
BA_ "SignalType" SG_ 595 DgnInf "UNM";
BA_ "VNSigSLHSSharedDiagnostic" SG_ 595 DgnInf 1;
BA_ "VNSigAllNodes" SG_ 594 DgnInf 1;
BA_ "SignalLongName" SG_ 594 DgnInf "Diagnostic Information";
BA_ "SignalType" SG_ 594 DgnInf "UNM";
BA_ "VNSigSLHSSharedDiagnostic" SG_ 594 DgnInf 1;
BA_ "VNSigAllNodes" SG_ 593 DgnInf 1;
BA_ "SignalLongName" SG_ 593 DgnInf "Diagnostic Information";
BA_ "SignalType" SG_ 593 DgnInf "UNM";
BA_ "VNSigSLHSSharedDiagnostic" SG_ 593 DgnInf 1;
BA_ "VNSigAllNodes" SG_ 592 DgnInf 1;
BA_ "SignalLongName" SG_ 592 DgnInf "Diagnostic Information";
BA_ "SignalType" SG_ 592 DgnInf "UNM";
BA_ "VNSigSLHSSharedDiagnostic" SG_ 592 DgnInf 1;
BA_ "VNSigAllNodes" SG_ 591 DgnInf 1;
BA_ "SignalLongName" SG_ 591 DgnInf "Diagnostic Information";
BA_ "SignalType" SG_ 591 DgnInf "UNM";
BA_ "VNSigSLHSSharedDiagnostic" SG_ 591 DgnInf 1;
BA_ "VNSigAllNodes" SG_ 590 DgnInf 1;
BA_ "SignalLongName" SG_ 590 DgnInf "Diagnostic Information";
BA_ "SignalType" SG_ 590 DgnInf "UNM";
BA_ "VNSigSLHSSharedDiagnostic" SG_ 590 DgnInf 1;
BA_ "VNSigAllNodes" SG_ 589 DgnInf 1;
BA_ "SignalLongName" SG_ 589 DgnInf "Diagnostic Information";
BA_ "SignalType" SG_ 589 DgnInf "UNM";
BA_ "VNSigSLHSSharedDiagnostic" SG_ 589 DgnInf 1;
BA_ "VNSigAllNodes" SG_ 585 DgnInf 1;
BA_ "SignalLongName" SG_ 585 DgnInf "Diagnostic Information";
BA_ "SignalType" SG_ 585 DgnInf "UNM";
BA_ "VNSigSLHSSharedDiagnostic" SG_ 585 DgnInf 1;
BA_ "VNSigAllNodes" SG_ 587 DgnInf 1;
BA_ "SignalLongName" SG_ 587 DgnInf "Diagnostic Information";
BA_ "SignalType" SG_ 587 DgnInf "UNM";
BA_ "VNSigSLHSSharedDiagnostic" SG_ 587 DgnInf 1;
BA_ "VNSigAllNodes" SG_ 584 DgnInf 1;
BA_ "SignalLongName" SG_ 584 DgnInf "Diagnostic Information";
BA_ "SignalType" SG_ 584 DgnInf "UNM";
BA_ "VNSigSLHSSharedDiagnostic" SG_ 584 DgnInf 1;
BA_ "VNSigAllNodes" SG_ 588 DgnInf 1;
BA_ "SignalLongName" SG_ 588 DgnInf "Diagnostic Information";
BA_ "SignalType" SG_ 588 DgnInf "UNM";
BA_ "VNSigSLHSSharedDiagnostic" SG_ 588 DgnInf 1;
BA_ "VNSigAllNodes" SG_ 583 DgnInf 1;
BA_ "SignalLongName" SG_ 583 DgnInf "Diagnostic Information";
BA_ "SignalType" SG_ 583 DgnInf "UNM";
BA_ "VNSigSLHSSharedDiagnostic" SG_ 583 DgnInf 1;
BA_ "VNSigAllNodes" SG_ 582 DgnInf 1;
BA_ "SignalLongName" SG_ 582 DgnInf "Diagnostic Information";
BA_ "SignalType" SG_ 582 DgnInf "UNM";
BA_ "VNSigSLHSSharedDiagnostic" SG_ 582 DgnInf 1;
BA_ "VNSigAllNodes" SG_ 581 DgnInf 1;
BA_ "SignalLongName" SG_ 581 DgnInf "Diagnostic Information";
BA_ "SignalType" SG_ 581 DgnInf "UNM";
BA_ "VNSigSLHSSharedDiagnostic" SG_ 581 DgnInf 1;
BA_ "VNSigAllNodes" SG_ 817 RrAxlActrEstmtdTrqV 1;
BA_ "SignalLongName" SG_ 817 RrAxlActrEstmtdTrqV "Rear Axle Actuator Estimated Torque Validity";
BA_ "SignalType" SG_ 817 RrAxlActrEstmtdTrqV "ENM";
BA_ "VNSigAllNodes" SG_ 817 RrAxlActrEstmtdTrqM 1;
BA_ "SignalLongName" SG_ 817 RrAxlActrEstmtdTrqM "Rear Axle Actuator Estimated Torque Mask";
BA_ "SignalType" SG_ 817 RrAxlActrEstmtdTrqM "ENM";
BA_ "VNSigAllNodes" SG_ 817 RrAxlActrEstmtdTrq 1;
BA_ "GenSigStartValue" SG_ 817 RrAxlActrEstmtdTrq 1024;
BA_ "SignalLongName" SG_ 817 RrAxlActrEstmtdTrq "Rear Axle Actuator Estimated Torque";
BA_ "SignalType" SG_ 817 RrAxlActrEstmtdTrq "UNM";
BA_ "VNSigAllNodes" SG_ 817 RrAxlActrThrmlCpctyV 1;
BA_ "SignalLongName" SG_ 817 RrAxlActrThrmlCpctyV "Rear Axle Actuator Thermal Capacity Validity";
BA_ "SignalType" SG_ 817 RrAxlActrThrmlCpctyV "ENM";
BA_ "VNSigAllNodes" SG_ 817 RrAxlActrThrmlCpctyM 1;
BA_ "SignalLongName" SG_ 817 RrAxlActrThrmlCpctyM "Rear Axle Actuator Thermal Capacity Mask";
BA_ "SignalType" SG_ 817 RrAxlActrThrmlCpctyM "ENM";
BA_ "VNSigAllNodes" SG_ 817 RrAxlActrThrmlCpcty 1;
BA_ "SignalLongName" SG_ 817 RrAxlActrThrmlCpcty "Rear Axle Actuator Thermal Capacity";
BA_ "SignalType" SG_ 817 RrAxlActrThrmlCpcty "UNM";
BA_ "VNSigAllNodes" SG_ 817 RrAxlActrStat 1;
BA_ "SignalLongName" SG_ 817 RrAxlActrStat "Rear Axle Actuator Status";
BA_ "SignalType" SG_ 817 RrAxlActrStat "ENM";
BA_ "VNSigAllNodes" SG_ 580 DgnInf 1;
BA_ "SignalLongName" SG_ 580 DgnInf "Diagnostic Information";
BA_ "SignalType" SG_ 580 DgnInf "UNM";
BA_ "VNSigSLHSSharedDiagnostic" SG_ 580 DgnInf 1;
BA_ "VNSigAllNodes" SG_ 579 DgnInf 1;
BA_ "SignalLongName" SG_ 579 DgnInf "Diagnostic Information";
BA_ "SignalType" SG_ 579 DgnInf "UNM";
BA_ "VNSigSLHSSharedDiagnostic" SG_ 579 DgnInf 1;
BA_ "VNSigAllNodes" SG_ 578 DgnInf 1;
BA_ "SignalLongName" SG_ 578 DgnInf "Diagnostic Information";
BA_ "SignalType" SG_ 578 DgnInf "UNM";
BA_ "VNSigSLHSSharedDiagnostic" SG_ 578 DgnInf 1;
BA_ "VNSigAllNodes" SG_ 577 DgnInf 1;
BA_ "SignalLongName" SG_ 577 DgnInf "Diagnostic Information";
BA_ "SignalType" SG_ 577 DgnInf "UNM";
BA_ "VNSigSLHSSharedDiagnostic" SG_ 577 DgnInf 1;
BA_ "VNSigAllNodes" SG_ 566 RrAxlEstmtdRngGrTrqV 1;
BA_ "SignalLongName" SG_ 566 RrAxlEstmtdRngGrTrqV "Rear Axle Estimated Ring Gear Torque Validity";
BA_ "SignalType" SG_ 566 RrAxlEstmtdRngGrTrqV "ENM";
BA_ "VNSigAllNodes" SG_ 566 RrAxlEstmtdRngGrTrq 1;
BA_ "GenSigStartValue" SG_ 566 RrAxlEstmtdRngGrTrq 11267;
BA_ "SignalLongName" SG_ 566 RrAxlEstmtdRngGrTrq "Rear Axle Estimated Ring Gear Torque";
BA_ "SignalType" SG_ 566 RrAxlEstmtdRngGrTrq "UNM";
BA_ "VNSigAllNodes" SG_ 566 RrAxlActrTrqRqstRC 1;
BA_ "SignalLongName" SG_ 566 RrAxlActrTrqRqstRC "Rear Axle Actuator Torque Request Rolling Count";
BA_ "SignalType" SG_ 566 RrAxlActrTrqRqstRC "UNM";
BA_ "VNSigAllNodes" SG_ 566 RrAxlActrTrqRqstPVal 1;
BA_ "SignalLongName" SG_ 566 RrAxlActrTrqRqstPVal "Rear Axle Actuator Torque Request Protection Value";
BA_ "SignalType" SG_ 566 RrAxlActrTrqRqstPVal "UNM";
BA_ "VNSigAllNodes" SG_ 566 RAATR_RrAxlTrqVl 1;
BA_ "SignalLongName" SG_ 566 RAATR_RrAxlTrqVl "Rear Axle Actuator Torque Request : Rear Axle Torque Value";
BA_ "PacketOrder" SG_ 566 RAATR_RrAxlTrqVl 2;
BA_ "SignalType" SG_ 566 RAATR_RrAxlTrqVl "UNM";
BA_ "GenSigStartValue" SG_ 566 RAATR_RrAxlTrqVl 1024;
BA_ "VNSigAllNodes" SG_ 566 RAATR_RrAxlMdRqst 1;
BA_ "SignalLongName" SG_ 566 RAATR_RrAxlMdRqst "Rear Axle Actuator Torque Request : Rear Axle Mode Request";
BA_ "PacketOrder" SG_ 566 RAATR_RrAxlMdRqst 1;
BA_ "SignalType" SG_ 566 RAATR_RrAxlMdRqst "ENM";
BA_ "VNSigAllNodes" SG_ 320 IMULonAccPriV 1;
BA_ "SignalLongName" SG_ 320 IMULonAccPriV "Inertial Measurement Unit Longitudinal Acceleration Primary Validity";
BA_ "SignalType" SG_ 320 IMULonAccPriV "ENM";
BA_ "VNSigAllNodes" SG_ 320 IMULonAccPri 1;
BA_ "SignalLongName" SG_ 320 IMULonAccPri "Inertial Measurement Unit Longitudinal Acceleration Primary";
BA_ "SignalType" SG_ 320 IMULonAccPri "SNM";
BA_ "VNSigAllNodes" SG_ 320 IMUXAxisClbrtd 1;
BA_ "SignalLongName" SG_ 320 IMUXAxisClbrtd "Inertial Measurement Unit X Axis Calibrated";
BA_ "SignalType" SG_ 320 IMUXAxisClbrtd "ENM";
BA_ "VNSigAllNodes" SG_ 320 IMUXAxisOrntn 1;
BA_ "SignalLongName" SG_ 320 IMUXAxisOrntn "Inertial Measurement Unit X Axis Orientation";
BA_ "SignalType" SG_ 320 IMUXAxisOrntn "ENM";
BA_ "VNSigAllNodes" SG_ 320 IMUPriYawDrftTyp 1;
BA_ "SignalLongName" SG_ 320 IMUPriYawDrftTyp "Inertial Measurement Unit Primary Yaw Drift Type";
BA_ "SignalType" SG_ 320 IMUPriYawDrftTyp "ENM";
BA_ "VNSigAllNodes" SG_ 320 IMUDataMsk 1;
BA_ "SignalLongName" SG_ 320 IMUDataMsk "Inertial Measurement Unit Data Mask";
BA_ "SignalType" SG_ 320 IMUDataMsk "BLN";
BA_ "VNSigAllNodes" SG_ 320 IMUChksumSec 1;
BA_ "SignalLongName" SG_ 320 IMUChksumSec "Inertial Measurement Unit Checksum Secondary";
BA_ "SignalType" SG_ 320 IMUChksumSec "UNM";
BA_ "VNSigAllNodes" SG_ 320 IMUYawRtSecAval 1;
BA_ "SignalLongName" SG_ 320 IMUYawRtSecAval "Inertial Measurement Unit Yaw Rate Secondary Available";
BA_ "SignalType" SG_ 320 IMUYawRtSecAval "BLN";
BA_ "VNSigAllNodes" SG_ 320 IMULatAccSecAval 1;
BA_ "SignalLongName" SG_ 320 IMULatAccSecAval "Inertial Measurement Unit Lateral Acceleration Secondary Available";
BA_ "SignalType" SG_ 320 IMULatAccSecAval "BLN";
BA_ "VNSigAllNodes" SG_ 320 IMURollCntSec 1;
BA_ "SignalLongName" SG_ 320 IMURollCntSec "Inertial Measurement Unit Rolling Count Secondary";
BA_ "SignalType" SG_ 320 IMURollCntSec "UNM";
BA_ "VNSigAllNodes" SG_ 320 IMUYawRtSecV 1;
BA_ "SignalLongName" SG_ 320 IMUYawRtSecV "Inertial Measurement Unit Yaw Rate Secondary Validity";
BA_ "SignalType" SG_ 320 IMUYawRtSecV "ENM";
BA_ "VNSigAllNodes" SG_ 320 IMUYawRtSec 1;
BA_ "SignalLongName" SG_ 320 IMUYawRtSec "Inertial Measurement Unit Yaw Rate Secondary";
BA_ "SignalType" SG_ 320 IMUYawRtSec "SNM";
BA_ "VNSigAllNodes" SG_ 320 IMULatACCSecV 1;
BA_ "SignalLongName" SG_ 320 IMULatACCSecV "Inertial Measurement Unit Lateral Acceleration Secondary Validity";
BA_ "SignalType" SG_ 320 IMULatACCSecV "ENM";
BA_ "VNSigAllNodes" SG_ 320 IMULatACCSec 1;
BA_ "SignalLongName" SG_ 320 IMULatACCSec "Inertial Measurement Unit Lateral Acceleration Secondary";
BA_ "SignalType" SG_ 320 IMULatACCSec "SNM";
BA_ "VNSigAllNodes" SG_ 512 VhDynRRWhlSt 1;
BA_ "SignalLongName" SG_ 512 VhDynRRWhlSt "Vehicle Dynamics Control Rear Right Wheel Status";
BA_ "SignalType" SG_ 512 VhDynRRWhlSt "ENM";
BA_ "VNSigAllNodes" SG_ 512 VhDynRLWhlSt 1;
BA_ "SignalLongName" SG_ 512 VhDynRLWhlSt "Vehicle Dynamics Control Rear Left Wheel Status";
BA_ "SignalType" SG_ 512 VhDynRLWhlSt "ENM";
BA_ "VNSigAllNodes" SG_ 512 VhDynFRWhlSt 1;
BA_ "SignalLongName" SG_ 512 VhDynFRWhlSt "Vehicle Dynamics Control Front Right Wheel Status";
BA_ "SignalType" SG_ 512 VhDynFRWhlSt "ENM";
BA_ "VNSigAllNodes" SG_ 512 VhDynFLWhlSt 1;
BA_ "SignalLongName" SG_ 512 VhDynFLWhlSt "Vehicle Dynamics Control Front Left Wheel Status";
BA_ "SignalType" SG_ 512 VhDynFLWhlSt "ENM";
BA_ "VNSigAllNodes" SG_ 512 SASCalRq 1;
BA_ "SignalLongName" SG_ 512 SASCalRq "Steering Wheel Angle Sensor Calibration Request";
BA_ "SignalType" SG_ 512 SASCalRq "ENM";
BA_ "VNSigAllNodes" SG_ 512 PnonAngSnsCalReq 1;
BA_ "SignalLongName" SG_ 512 PnonAngSnsCalReq "Pinion Angle Sensor Calibration Request";
BA_ "SignalType" SG_ 512 PnonAngSnsCalReq "BLN";
BA_ "VNSigAllNodes" SG_ 290 BkupPwrModeMstrVDA 1;
BA_ "GenSigStartValue" SG_ 290 BkupPwrModeMstrVDA 1;
BA_ "SignalLongName" SG_ 290 BkupPwrModeMstrVDA "Backup Power Mode Master Virtual Device Availability";
BA_ "SignalType" SG_ 290 BkupPwrModeMstrVDA "ENM";
BA_ "VNSigAllNodes" SG_ 290 SysBkupPwrMdEn 1;
BA_ "SignalLongName" SG_ 290 SysBkupPwrMdEn "System Backup Power Mode Enabled";
BA_ "SignalType" SG_ 290 SysBkupPwrMdEn "BLN";
BA_ "VNSigAllNodes" SG_ 290 SysBkUpPwrMd 1;
BA_ "SignalLongName" SG_ 290 SysBkUpPwrMd "System Backup Power Mode";
BA_ "SignalType" SG_ 290 SysBkUpPwrMd "ENM";
BA_ "VNSigAllNodes" SG_ 304 IMULonAccPriAval 1;
BA_ "SignalLongName" SG_ 304 IMULonAccPriAval "Inertial Measurement Unit Longitudinal Acceleration Primary Available";
BA_ "SignalType" SG_ 304 IMULonAccPriAval "BLN";
BA_ "VNSigAllNodes" SG_ 304 IMULonAccSecAval 1;
BA_ "SignalLongName" SG_ 304 IMULonAccSecAval "Inertial Measurement Unit Longitudinal Acceleration Secondary Available";
BA_ "SignalType" SG_ 304 IMULonAccSecAval "BLN";
BA_ "VNSigAllNodes" SG_ 304 IMULonAccSecV 1;
BA_ "SignalLongName" SG_ 304 IMULonAccSecV "Inertial Measurement Unit Longitudinal Acceleration Secondary Validity";
BA_ "SignalType" SG_ 304 IMULonAccSecV "ENM";
BA_ "VNSigAllNodes" SG_ 304 IMUYawRtAccPriSecure 1;
BA_ "SignalLongName" SG_ 304 IMUYawRtAccPriSecure "Inertial Measurement Unit Yaw Rate Acceleration Primary Secure";
BA_ "SignalType" SG_ 304 IMUYawRtAccPriSecure "SNM";
BA_ "VNSigAllNodes" SG_ 304 IMUYawRtPriV 1;
BA_ "SignalLongName" SG_ 304 IMUYawRtPriV "Inertial Measurement Unit Yaw Rate Primary Validity";
BA_ "SignalType" SG_ 304 IMUYawRtPriV "ENM";
BA_ "VNSigAllNodes" SG_ 304 IMUYawRtPri 1;
BA_ "SignalLongName" SG_ 304 IMUYawRtPri "Inertial Measurement Unit Yaw Rate Primary";
BA_ "SignalType" SG_ 304 IMUYawRtPri "SNM";
BA_ "VNSigAllNodes" SG_ 304 IMURollCntPri 1;
BA_ "SignalLongName" SG_ 304 IMURollCntPri "Inertial Measurement Unit Rolling Count Primary";
BA_ "SignalType" SG_ 304 IMURollCntPri "UNM";
BA_ "VNSigAllNodes" SG_ 304 IMUChksumPri 1;
BA_ "SignalLongName" SG_ 304 IMUChksumPri "Inertial Measurement Unit Checksum Primary";
BA_ "SignalType" SG_ 304 IMUChksumPri "UNM";
BA_ "VNSigAllNodes" SG_ 304 IMULonAccSec 1;
BA_ "SignalLongName" SG_ 304 IMULonAccSec "Inertial Measurement Unit Longitudinal Acceleration Secondary";
BA_ "SignalType" SG_ 304 IMULonAccSec "SNM";
BA_ "VNSigAllNodes" SG_ 304 IMULatAccPrim 1;
BA_ "SignalLongName" SG_ 304 IMULatAccPrim "Inertial Measurement Unit Lateral Acceleration Primary";
BA_ "SignalType" SG_ 304 IMULatAccPrim "SNM";
BA_ "VNSigAllNodes" SG_ 304 IMULatAccPrimV 1;
BA_ "SignalLongName" SG_ 304 IMULatAccPrimV "Inertial Measurement Unit Lateral Acceleration Primary Validity";
BA_ "SignalType" SG_ 304 IMULatAccPrimV "ENM";
BA_ "VNSigAllNodes" SG_ 289 SysPwMdVDA 1;
BA_ "GenSigStartValue" SG_ 289 SysPwMdVDA 1;
BA_ "SignalLongName" SG_ 289 SysPwMdVDA "System Power Mode Virtual Device Availability";
BA_ "SignalType" SG_ 289 SysPwMdVDA "ENM";
BA_ "VNSigAllNodes" SG_ 289 TrStLgMdAtv 1;
BA_ "SignalLongName" SG_ 289 TrStLgMdAtv "Transport Storage Logistic Mode Active";
BA_ "SignalType" SG_ 289 TrStLgMdAtv "BLN";
BA_ "VNSigAllNodes" SG_ 289 SysPwrMd 1;
BA_ "SignalLongName" SG_ 289 SysPwrMd "System Power Mode";
BA_ "SignalType" SG_ 289 SysPwrMd "ENM";
BA_ "VNSigAllNodes" SG_ 192 WRSCD_RNDrvnCkVa 1;
BA_ "SignalLongName" SG_ 192 WRSCD_RNDrvnCkVa "Wheel Rotational Status Check Data : Right Non Driven Check Value";
BA_ "PacketOrder" SG_ 192 WRSCD_RNDrvnCkVa 8;
BA_ "SignalType" SG_ 192 WRSCD_RNDrvnCkVa "UNM";
BA_ "VNSigAllNodes" SG_ 192 WRSCD_LfNDrvnCkVa 1;
BA_ "SignalLongName" SG_ 192 WRSCD_LfNDrvnCkVa "Wheel Rotational Status Check Data : Left Non Driven Check Value";
BA_ "PacketOrder" SG_ 192 WRSCD_LfNDrvnCkVa 7;
BA_ "SignalType" SG_ 192 WRSCD_LfNDrvnCkVa "UNM";
BA_ "VNSigAllNodes" SG_ 192 WRSCD_RDrvnCkVa 1;
BA_ "SignalLongName" SG_ 192 WRSCD_RDrvnCkVa "Wheel Rotational Status Check Data : Right Driven Check Value";
BA_ "PacketOrder" SG_ 192 WRSCD_RDrvnCkVa 6;
BA_ "SignalType" SG_ 192 WRSCD_RDrvnCkVa "UNM";
BA_ "VNSigAllNodes" SG_ 192 WRSCD_LfDrvnCkVa 1;
BA_ "SignalLongName" SG_ 192 WRSCD_LfDrvnCkVa "Wheel Rotational Status Check Data : Left Driven Check Value";
BA_ "PacketOrder" SG_ 192 WRSCD_LfDrvnCkVa 5;
BA_ "SignalType" SG_ 192 WRSCD_LfDrvnCkVa "UNM";
BA_ "VNSigAllNodes" SG_ 192 WRSCD_RtNDrvnSNm 1;
BA_ "SignalLongName" SG_ 192 WRSCD_RtNDrvnSNm "Wheel Rotational Status Check Data : Right Non Driven Sequence Number";
BA_ "PacketOrder" SG_ 192 WRSCD_RtNDrvnSNm 4;
BA_ "SignalType" SG_ 192 WRSCD_RtNDrvnSNm "UNM";
BA_ "VNSigAllNodes" SG_ 192 WRSCD_LftNDrvnSNm 1;
BA_ "SignalLongName" SG_ 192 WRSCD_LftNDrvnSNm "Wheel Rotational Status Check Data : Left Non Driven Sequence Number";
BA_ "PacketOrder" SG_ 192 WRSCD_LftNDrvnSNm 3;
BA_ "SignalType" SG_ 192 WRSCD_LftNDrvnSNm "UNM";
BA_ "VNSigAllNodes" SG_ 192 WRSCD_RtDrvnSqNm 1;
BA_ "SignalLongName" SG_ 192 WRSCD_RtDrvnSqNm "Wheel Rotational Status Check Data : Right Driven Sequence Number";
BA_ "PacketOrder" SG_ 192 WRSCD_RtDrvnSqNm 2;
BA_ "SignalType" SG_ 192 WRSCD_RtDrvnSqNm "UNM";
BA_ "VNSigAllNodes" SG_ 192 WRSCD_LftDrvnSqNm 1;
BA_ "SignalLongName" SG_ 192 WRSCD_LftDrvnSqNm "Wheel Rotational Status Check Data : Left Driven Sequence Number";
BA_ "PacketOrder" SG_ 192 WRSCD_LftDrvnSqNm 1;
BA_ "SignalType" SG_ 192 WRSCD_LftDrvnSqNm "UNM";
BA_ "VNSigAllNodes" SG_ 328 StrngAsstRdcdIO 1;
BA_ "SignalLongName" SG_ 328 StrngAsstRdcdIO "Steering Assist Reduced Indication On";
BA_ "SignalType" SG_ 328 StrngAsstRdcdIO "BLN";
BA_ "VNSigAllNodes" SG_ 328 PwrStrIO 1;
BA_ "SignalLongName" SG_ 328 PwrStrIO "Power Steering Indication On";
BA_ "SignalType" SG_ 328 PwrStrIO "BLN";
BA_ "VNSigAllNodes" SG_ 458 TrqOvrlTrqDStat 1;
BA_ "SignalLongName" SG_ 458 TrqOvrlTrqDStat "Torque Overlay Torque Delivered Status";
BA_ "SignalType" SG_ 458 TrqOvrlTrqDStat "ENM";
BA_ "VNSigAllNodes" SG_ 458 TrqOvrlDltTrqDlrd 1;
BA_ "SignalLongName" SG_ 458 TrqOvrlDltTrqDlrd "Torque Overlay Delta Torque Delivered";
BA_ "SignalType" SG_ 458 TrqOvrlDltTrqDlrd "SNM";
BA_ "VNSigAllNodes" SG_ 458 TrqOvrlDChksm 1;
BA_ "SignalLongName" SG_ 458 TrqOvrlDChksm "Torque Overlay Delivered Checksum";
BA_ "SignalType" SG_ 458 TrqOvrlDChksm "UNM";
BA_ "VNSigAllNodes" SG_ 458 TrqOvrlDvrdARC 1;
BA_ "SignalLongName" SG_ 458 TrqOvrlDvrdARC "Torque Overlay Delivered Alive Rolling Count";
BA_ "SignalType" SG_ 458 TrqOvrlDvrdARC "UNM";
BA_ "VNSigAllNodes" SG_ 458 ElPwrStTtlTqDlrd 1;
BA_ "SignalLongName" SG_ 458 ElPwrStTtlTqDlrd "Electrical Power Steering Total Torque Delivered";
BA_ "SignalType" SG_ 458 ElPwrStTtlTqDlrd "SNM";
BA_REL_ "GenSigTimeoutTime" BU_SG_REL_ SDM_CE SG_ 832 BrkPedTrvlAchvd 250;
BA_REL_ "GenSigTimeoutMsg" BU_SG_REL_ SDM_CE SG_ 832 BrkPedTrvlAchvd 832;
BA_REL_ "GenSigSuprvResp" BU_SG_REL_ SDM_CE SG_ 832 BrkPedTrvlAchvd 1;
BA_REL_ "GenSigTimeoutTime" BU_SG_REL_ MSB1_CE SG_ 832 BrkPedTrvlAchvd 250;
BA_REL_ "GenSigTimeoutMsg" BU_SG_REL_ MSB1_CE SG_ 832 BrkPedTrvlAchvd 832;
BA_REL_ "GenSigSuprvResp" BU_SG_REL_ MSB1_CE SG_ 832 BrkPedTrvlAchvd 1;
BA_REL_ "GenSigTimeoutTime" BU_SG_REL_ MSB2_CE SG_ 832 BrkPedTrvlAchvd 250;
BA_REL_ "GenSigTimeoutMsg" BU_SG_REL_ MSB2_CE SG_ 832 BrkPedTrvlAchvd 832;
BA_REL_ "GenSigSuprvResp" BU_SG_REL_ MSB2_CE SG_ 832 BrkPedTrvlAchvd 1;
BA_REL_ "GenSigTimeoutTime" BU_SG_REL_ EPS_JR_CE SG_ 832 BrkPedTrvlAchvd 250;
BA_REL_ "GenSigTimeoutMsg" BU_SG_REL_ EPS_JR_CE SG_ 832 BrkPedTrvlAchvd 832;
BA_REL_ "GenSigSuprvResp" BU_SG_REL_ EPS_JR_CE SG_ 832 BrkPedTrvlAchvd 1;
BA_REL_ "GenSigTimeoutTime" BU_SG_REL_ SDM_CE SG_ 832 BrkPedTrvlAchvdV 250;
BA_REL_ "GenSigTimeoutMsg" BU_SG_REL_ SDM_CE SG_ 832 BrkPedTrvlAchvdV 832;
BA_REL_ "GenSigSuprvResp" BU_SG_REL_ SDM_CE SG_ 832 BrkPedTrvlAchvdV 1;
BA_REL_ "GenSigTimeoutTime" BU_SG_REL_ MSB1_CE SG_ 832 BrkPedTrvlAchvdV 250;
BA_REL_ "GenSigTimeoutMsg" BU_SG_REL_ MSB1_CE SG_ 832 BrkPedTrvlAchvdV 832;
BA_REL_ "GenSigSuprvResp" BU_SG_REL_ MSB1_CE SG_ 832 BrkPedTrvlAchvdV 1;
BA_REL_ "GenSigTimeoutTime" BU_SG_REL_ MSB2_CE SG_ 832 BrkPedTrvlAchvdV 250;
BA_REL_ "GenSigTimeoutMsg" BU_SG_REL_ MSB2_CE SG_ 832 BrkPedTrvlAchvdV 832;
BA_REL_ "GenSigSuprvResp" BU_SG_REL_ MSB2_CE SG_ 832 BrkPedTrvlAchvdV 1;
BA_REL_ "GenSigTimeoutTime" BU_SG_REL_ EPS_JR_CE SG_ 832 BrkPedTrvlAchvdV 250;
BA_REL_ "GenSigTimeoutMsg" BU_SG_REL_ EPS_JR_CE SG_ 832 BrkPedTrvlAchvdV 832;
BA_REL_ "GenSigSuprvResp" BU_SG_REL_ EPS_JR_CE SG_ 832 BrkPedTrvlAchvdV 1;
BA_REL_ "GenSigTimeoutTime" BU_SG_REL_ EPS_JR_CE SG_ 832 BrkPdlInTrvPrt 250;
BA_REL_ "GenSigTimeoutMsg" BU_SG_REL_ EPS_JR_CE SG_ 832 BrkPdlInTrvPrt 832;
BA_REL_ "GenSigSuprvResp" BU_SG_REL_ EPS_JR_CE SG_ 832 BrkPdlInTrvPrt 1;
BA_REL_ "GenSigTimeoutTime" BU_SG_REL_ FCM_CE SG_ 832 AccActPos 250;
BA_REL_ "GenSigTimeoutMsg" BU_SG_REL_ FCM_CE SG_ 832 AccActPos 832;
BA_REL_ "GenSigSuprvResp" BU_SG_REL_ FCM_CE SG_ 832 AccActPos 1;
BA_REL_ "GenSigTimeoutTime" BU_SG_REL_ MSB1_CE SG_ 832 AccActPos 250;
BA_REL_ "GenSigTimeoutMsg" BU_SG_REL_ MSB1_CE SG_ 832 AccActPos 832;
BA_REL_ "GenSigSuprvResp" BU_SG_REL_ MSB1_CE SG_ 832 AccActPos 1;
BA_REL_ "GenSigTimeoutTime" BU_SG_REL_ MSB2_CE SG_ 832 AccActPos 250;
BA_REL_ "GenSigTimeoutMsg" BU_SG_REL_ MSB2_CE SG_ 832 AccActPos 832;
BA_REL_ "GenSigSuprvResp" BU_SG_REL_ MSB2_CE SG_ 832 AccActPos 1;
BA_REL_ "GenSigTimeoutTime" BU_SG_REL_ ARS_CE SG_ 832 WhlDistPrRevNDrvn 250;
BA_REL_ "GenSigTimeoutMsg" BU_SG_REL_ ARS_CE SG_ 832 WhlDistPrRevNDrvn 832;
BA_REL_ "GenSigSuprvResp" BU_SG_REL_ ARS_CE SG_ 832 WhlDistPrRevNDrvn 1;
BA_REL_ "GenSigTimeoutTime" BU_SG_REL_ EPS_CE SG_ 832 WhlDistPrRevNDrvn 250;
BA_REL_ "GenSigTimeoutMsg" BU_SG_REL_ EPS_CE SG_ 832 WhlDistPrRevNDrvn 832;
BA_REL_ "GenSigSuprvResp" BU_SG_REL_ EPS_CE SG_ 832 WhlDistPrRevNDrvn 1;
BA_REL_ "GenSigTimeoutTime" BU_SG_REL_ EPS_JR_CE SG_ 832 WhlDistPrRevNDrvn 250;
BA_REL_ "GenSigTimeoutMsg" BU_SG_REL_ EPS_JR_CE SG_ 832 WhlDistPrRevNDrvn 832;
BA_REL_ "GenSigSuprvResp" BU_SG_REL_ EPS_JR_CE SG_ 832 WhlDistPrRevNDrvn 1;
BA_REL_ "GenSigTimeoutTime" BU_SG_REL_ ARS_CE SG_ 832 WhlDistPrRevDrvn 250;
BA_REL_ "GenSigTimeoutMsg" BU_SG_REL_ ARS_CE SG_ 832 WhlDistPrRevDrvn 832;
BA_REL_ "GenSigSuprvResp" BU_SG_REL_ ARS_CE SG_ 832 WhlDistPrRevDrvn 1;
BA_REL_ "GenSigTimeoutTime" BU_SG_REL_ EPS_JR_CE SG_ 832 WhlDistPrRevDrvn 250;
BA_REL_ "GenSigTimeoutMsg" BU_SG_REL_ EPS_JR_CE SG_ 832 WhlDistPrRevDrvn 832;
BA_REL_ "GenSigSuprvResp" BU_SG_REL_ EPS_JR_CE SG_ 832 WhlDistPrRevDrvn 1;
BA_REL_ "GenSigTimeoutTime" BU_SG_REL_ EPS_CE SG_ 832 WhlDistPrRevDrvn 250;
BA_REL_ "GenSigTimeoutMsg" BU_SG_REL_ EPS_CE SG_ 832 WhlDistPrRevDrvn 832;
BA_REL_ "GenSigSuprvResp" BU_SG_REL_ EPS_CE SG_ 832 WhlDistPrRevDrvn 1;
BA_REL_ "GenSigTimeoutTime" BU_SG_REL_ RDCM_CE SG_ 462 SecAxlLkTqRqCplRqTp 250;
BA_REL_ "GenSigTimeoutMsg" BU_SG_REL_ RDCM_CE SG_ 462 SecAxlLkTqRqCplRqTp 462;
BA_REL_ "GenSigSuprvResp" BU_SG_REL_ RDCM_CE SG_ 462 SecAxlLkTqRqCplRqTp 1;
BA_REL_ "GenSigTimeoutTime" BU_SG_REL_ RDCM_CE SG_ 462 SATRCplReqVal 250;
BA_REL_ "GenSigTimeoutMsg" BU_SG_REL_ RDCM_CE SG_ 462 SATRCplReqVal 462;
BA_REL_ "GenSigSuprvResp" BU_SG_REL_ RDCM_CE SG_ 462 SATRCplReqVal 1;
BA_REL_ "GenSigTimeoutTime" BU_SG_REL_ RDCM_CE SG_ 462 SATRCplReqAtv 250;
BA_REL_ "GenSigTimeoutMsg" BU_SG_REL_ RDCM_CE SG_ 462 SATRCplReqAtv 462;
BA_REL_ "GenSigSuprvResp" BU_SG_REL_ RDCM_CE SG_ 462 SATRCplReqAtv 1;
BA_REL_ "GenSigTimeoutTime" BU_SG_REL_ APA_CE SG_ 368 BrkSysAutBrkTrgtDcl 250;
BA_REL_ "GenSigTimeoutMsg" BU_SG_REL_ APA_CE SG_ 368 BrkSysAutBrkTrgtDcl 368;
BA_REL_ "GenSigSuprvResp" BU_SG_REL_ APA_CE SG_ 368 BrkSysAutBrkTrgtDcl 1;
BA_REL_ "GenSigTimeoutTime" BU_SG_REL_ SADS_CE SG_ 368 BrkSysAutBrkTrgtDcl 250;
BA_REL_ "GenSigTimeoutMsg" BU_SG_REL_ SADS_CE SG_ 368 BrkSysAutBrkTrgtDcl 368;
BA_REL_ "GenSigSuprvResp" BU_SG_REL_ SADS_CE SG_ 368 BrkSysAutBrkTrgtDcl 1;
BA_REL_ "GenSigTimeoutTime" BU_SG_REL_ EOCM_F_CE SG_ 368 BrkSysAutBrkTrgtDcl 120;
BA_REL_ "GenSigTimeoutMsg" BU_SG_REL_ EOCM_F_CE SG_ 368 BrkSysAutBrkTrgtDcl 368;
BA_REL_ "GenSigSuprvResp" BU_SG_REL_ EOCM_F_CE SG_ 368 BrkSysAutBrkTrgtDcl 1;
BA_REL_ "GenSigTimeoutTime" BU_SG_REL_ APA_CE SG_ 368 BrkSysAutBrkActDcl 250;
BA_REL_ "GenSigTimeoutMsg" BU_SG_REL_ APA_CE SG_ 368 BrkSysAutBrkActDcl 368;
BA_REL_ "GenSigSuprvResp" BU_SG_REL_ APA_CE SG_ 368 BrkSysAutBrkActDcl 1;
BA_REL_ "GenSigTimeoutTime" BU_SG_REL_ EOCM_F_CE SG_ 368 BrkSysAutBrkActDcl 120;
BA_REL_ "GenSigTimeoutMsg" BU_SG_REL_ EOCM_F_CE SG_ 368 BrkSysAutBrkActDcl 368;
BA_REL_ "GenSigSuprvResp" BU_SG_REL_ EOCM_F_CE SG_ 368 BrkSysAutBrkActDcl 1;
BA_REL_ "GenSigTimeoutTime" BU_SG_REL_ ACC_CE SG_ 368 BrkSysAutBrkActDcl 120;
BA_REL_ "GenSigTimeoutMsg" BU_SG_REL_ ACC_CE SG_ 368 BrkSysAutBrkActDcl 368;
BA_REL_ "GenSigSuprvResp" BU_SG_REL_ ACC_CE SG_ 368 BrkSysAutBrkActDcl 1;
BA_REL_ "GenSigTimeoutTime" BU_SG_REL_ SADS_CE SG_ 368 BrkSysAutBrkActDcl 250;
BA_REL_ "GenSigTimeoutMsg" BU_SG_REL_ SADS_CE SG_ 368 BrkSysAutBrkActDcl 368;
BA_REL_ "GenSigSuprvResp" BU_SG_REL_ SADS_CE SG_ 368 BrkSysAutBrkActDcl 1;
BA_REL_ "GenSigTimeoutTime" BU_SG_REL_ APA_CE SG_ 368 AvgWhlBrkPrsrEst 250;
BA_REL_ "GenSigTimeoutMsg" BU_SG_REL_ APA_CE SG_ 368 AvgWhlBrkPrsrEst 368;
BA_REL_ "GenSigSuprvResp" BU_SG_REL_ APA_CE SG_ 368 AvgWhlBrkPrsrEst 1;
BA_REL_ "GenSigTimeoutTime" BU_SG_REL_ ACC_CE SG_ 368 AvgWhlBrkPrsrEst 250;
BA_REL_ "GenSigTimeoutMsg" BU_SG_REL_ ACC_CE SG_ 368 AvgWhlBrkPrsrEst 368;
BA_REL_ "GenSigSuprvResp" BU_SG_REL_ ACC_CE SG_ 368 AvgWhlBrkPrsrEst 1;
BA_REL_ "GenSigRxStartValue" BU_SG_REL_ ACC_CE SG_ 368 AvgWhlBrkPrsrEst "0";
BA_REL_ "GenSigTimeoutTime" BU_SG_REL_ EOCM_F_CE SG_ 368 AvgWhlBrkPrsrEst 120;
BA_REL_ "GenSigTimeoutMsg" BU_SG_REL_ EOCM_F_CE SG_ 368 AvgWhlBrkPrsrEst 368;
BA_REL_ "GenSigSuprvResp" BU_SG_REL_ EOCM_F_CE SG_ 368 AvgWhlBrkPrsrEst 1;
BA_REL_ "GenSigTimeoutTime" BU_SG_REL_ SADS_CE SG_ 368 AvgWhlBrkPrsrEst 250;
BA_REL_ "GenSigTimeoutMsg" BU_SG_REL_ SADS_CE SG_ 368 AvgWhlBrkPrsrEst 368;
BA_REL_ "GenSigSuprvResp" BU_SG_REL_ SADS_CE SG_ 368 AvgWhlBrkPrsrEst 1;
BA_REL_ "GenSigTimeoutTime" BU_SG_REL_ APA_CE SG_ 368 VehMvngStat 250;
BA_REL_ "GenSigTimeoutMsg" BU_SG_REL_ APA_CE SG_ 368 VehMvngStat 368;
BA_REL_ "GenSigSuprvResp" BU_SG_REL_ APA_CE SG_ 368 VehMvngStat 1;
BA_REL_ "GenSigTimeoutTime" BU_SG_REL_ ACC_CE SG_ 368 VehMvngStat 250;
BA_REL_ "GenSigTimeoutMsg" BU_SG_REL_ ACC_CE SG_ 368 VehMvngStat 368;
BA_REL_ "GenSigSuprvResp" BU_SG_REL_ ACC_CE SG_ 368 VehMvngStat 1;
BA_REL_ "GenSigRxStartValue" BU_SG_REL_ ACC_CE SG_ 368 VehMvngStat "0";
BA_REL_ "GenSigTimeoutTime" BU_SG_REL_ EOCM_F_CE SG_ 368 VehMvngStat 120;
BA_REL_ "GenSigTimeoutMsg" BU_SG_REL_ EOCM_F_CE SG_ 368 VehMvngStat 368;
BA_REL_ "GenSigSuprvResp" BU_SG_REL_ EOCM_F_CE SG_ 368 VehMvngStat 1;
BA_REL_ "GenSigTimeoutTime" BU_SG_REL_ APA_CE SG_ 368 FSRACCBrkngReqDenied 250;
BA_REL_ "GenSigTimeoutMsg" BU_SG_REL_ APA_CE SG_ 368 FSRACCBrkngReqDenied 368;
BA_REL_ "GenSigSuprvResp" BU_SG_REL_ APA_CE SG_ 368 FSRACCBrkngReqDenied 1;
BA_REL_ "GenSigTimeoutTime" BU_SG_REL_ ACC_CE SG_ 368 FSRACCBrkngReqDenied 250;
BA_REL_ "GenSigTimeoutMsg" BU_SG_REL_ ACC_CE SG_ 368 FSRACCBrkngReqDenied 368;
BA_REL_ "GenSigSuprvResp" BU_SG_REL_ ACC_CE SG_ 368 FSRACCBrkngReqDenied 1;
BA_REL_ "GenSigRxStartValue" BU_SG_REL_ ACC_CE SG_ 368 FSRACCBrkngReqDenied "0";
BA_REL_ "GenSigTimeoutTime" BU_SG_REL_ EOCM_F_CE SG_ 368 FSRACCBrkngReqDenied 120;
BA_REL_ "GenSigTimeoutMsg" BU_SG_REL_ EOCM_F_CE SG_ 368 FSRACCBrkngReqDenied 368;
BA_REL_ "GenSigSuprvResp" BU_SG_REL_ EOCM_F_CE SG_ 368 FSRACCBrkngReqDenied 1;
BA_REL_ "GenSigTimeoutTime" BU_SG_REL_ APA_CE SG_ 368 BrkSysPlsStat 250;
BA_REL_ "GenSigTimeoutMsg" BU_SG_REL_ APA_CE SG_ 368 BrkSysPlsStat 368;
BA_REL_ "GenSigSuprvResp" BU_SG_REL_ APA_CE SG_ 368 BrkSysPlsStat 1;
BA_REL_ "GenSigTimeoutTime" BU_SG_REL_ EOCM_F_CE SG_ 368 BrkSysPlsStat 120;
BA_REL_ "GenSigTimeoutMsg" BU_SG_REL_ EOCM_F_CE SG_ 368 BrkSysPlsStat 368;
BA_REL_ "GenSigSuprvResp" BU_SG_REL_ EOCM_F_CE SG_ 368 BrkSysPlsStat 1;
BA_REL_ "GenSigTimeoutTime" BU_SG_REL_ ICCM_CE SG_ 368 BrkSysAutBrkStat 250;
BA_REL_ "GenSigTimeoutMsg" BU_SG_REL_ ICCM_CE SG_ 368 BrkSysAutBrkStat 368;
BA_REL_ "GenSigSuprvResp" BU_SG_REL_ ICCM_CE SG_ 368 BrkSysAutBrkStat 1;
BA_REL_ "GenSigTimeoutTime" BU_SG_REL_ APA_CE SG_ 368 BrkSysAutBrkStat 250;
BA_REL_ "GenSigTimeoutMsg" BU_SG_REL_ APA_CE SG_ 368 BrkSysAutBrkStat 368;
BA_REL_ "GenSigSuprvResp" BU_SG_REL_ APA_CE SG_ 368 BrkSysAutBrkStat 1;
BA_REL_ "GenSigTimeoutTime" BU_SG_REL_ SADS_CE SG_ 368 BrkSysAutBrkStat 250;
BA_REL_ "GenSigTimeoutMsg" BU_SG_REL_ SADS_CE SG_ 368 BrkSysAutBrkStat 368;
BA_REL_ "GenSigSuprvResp" BU_SG_REL_ SADS_CE SG_ 368 BrkSysAutBrkStat 1;
BA_REL_ "GenSigTimeoutTime" BU_SG_REL_ ACC_CE SG_ 368 BrkSysAutBrkStat 250;
BA_REL_ "GenSigTimeoutMsg" BU_SG_REL_ ACC_CE SG_ 368 BrkSysAutBrkStat 368;
BA_REL_ "GenSigSuprvResp" BU_SG_REL_ ACC_CE SG_ 368 BrkSysAutBrkStat 1;
BA_REL_ "GenSigRxStartValue" BU_SG_REL_ ACC_CE SG_ 368 BrkSysAutBrkStat "0";
BA_REL_ "GenSigTimeoutTime" BU_SG_REL_ EOCM_F_CE SG_ 368 BrkSysAutBrkStat 120;
BA_REL_ "GenSigTimeoutMsg" BU_SG_REL_ EOCM_F_CE SG_ 368 BrkSysAutBrkStat 368;
BA_REL_ "GenSigSuprvResp" BU_SG_REL_ EOCM_F_CE SG_ 368 BrkSysAutBrkStat 1;
BA_REL_ "GenSigTimeoutTime" BU_SG_REL_ ICCM_CE SG_ 368 BrkSysExtHldCpbltyFld 250;
BA_REL_ "GenSigTimeoutMsg" BU_SG_REL_ ICCM_CE SG_ 368 BrkSysExtHldCpbltyFld 368;
BA_REL_ "GenSigSuprvResp" BU_SG_REL_ ICCM_CE SG_ 368 BrkSysExtHldCpbltyFld 1;
BA_REL_ "GenSigTimeoutTime" BU_SG_REL_ APA_CE SG_ 368 BrkSysExtHldCpbltyFld 250;
BA_REL_ "GenSigTimeoutMsg" BU_SG_REL_ APA_CE SG_ 368 BrkSysExtHldCpbltyFld 368;
BA_REL_ "GenSigSuprvResp" BU_SG_REL_ APA_CE SG_ 368 BrkSysExtHldCpbltyFld 1;
BA_REL_ "GenSigTimeoutTime" BU_SG_REL_ ACC_CE SG_ 368 BrkSysExtHldCpbltyFld 250;
BA_REL_ "GenSigTimeoutMsg" BU_SG_REL_ ACC_CE SG_ 368 BrkSysExtHldCpbltyFld 368;
BA_REL_ "GenSigSuprvResp" BU_SG_REL_ ACC_CE SG_ 368 BrkSysExtHldCpbltyFld 1;
BA_REL_ "GenSigRxStartValue" BU_SG_REL_ ACC_CE SG_ 368 BrkSysExtHldCpbltyFld "0";
BA_REL_ "GenSigTimeoutTime" BU_SG_REL_ EOCM_F_CE SG_ 368 BrkSysExtHldCpbltyFld 120;
BA_REL_ "GenSigTimeoutMsg" BU_SG_REL_ EOCM_F_CE SG_ 368 BrkSysExtHldCpbltyFld 368;
BA_REL_ "GenSigSuprvResp" BU_SG_REL_ EOCM_F_CE SG_ 368 BrkSysExtHldCpbltyFld 1;
BA_REL_ "GenSigTimeoutTime" BU_SG_REL_ APA_CE SG_ 368 BrkSysAutBrkTrgtDclV 250;
BA_REL_ "GenSigTimeoutMsg" BU_SG_REL_ APA_CE SG_ 368 BrkSysAutBrkTrgtDclV 368;
BA_REL_ "GenSigSuprvResp" BU_SG_REL_ APA_CE SG_ 368 BrkSysAutBrkTrgtDclV 1;
BA_REL_ "GenSigTimeoutTime" BU_SG_REL_ APA_CE SG_ 368 BrkSysAutBrkActDclV 250;
BA_REL_ "GenSigTimeoutMsg" BU_SG_REL_ APA_CE SG_ 368 BrkSysAutBrkActDclV 368;
BA_REL_ "GenSigSuprvResp" BU_SG_REL_ APA_CE SG_ 368 BrkSysAutBrkActDclV 1;
BA_REL_ "GenSigTimeoutTime" BU_SG_REL_ RDCM_CE SG_ 469 TwnClRRAxlTrqRqPVal 250;
BA_REL_ "GenSigTimeoutMsg" BU_SG_REL_ RDCM_CE SG_ 469 TwnClRRAxlTrqRqPVal 469;
BA_REL_ "GenSigSuprvResp" BU_SG_REL_ RDCM_CE SG_ 469 TwnClRRAxlTrqRqPVal 1;
BA_REL_ "GenSigTimeoutTime" BU_SG_REL_ RDCM_CE SG_ 469 TwnClRRAxlTrqRqARC 250;
BA_REL_ "GenSigTimeoutMsg" BU_SG_REL_ RDCM_CE SG_ 469 TwnClRRAxlTrqRqARC 469;
BA_REL_ "GenSigSuprvResp" BU_SG_REL_ RDCM_CE SG_ 469 TwnClRRAxlTrqRqARC 1;
BA_REL_ "GenSigTimeoutTime" BU_SG_REL_ RDCM_CE SG_ 469 TCRRATR_CplReqVal 250;
BA_REL_ "GenSigTimeoutMsg" BU_SG_REL_ RDCM_CE SG_ 469 TCRRATR_CplReqVal 469;
BA_REL_ "GenSigSuprvResp" BU_SG_REL_ RDCM_CE SG_ 469 TCRRATR_CplReqVal 1;
BA_REL_ "GenSigTimeoutTime" BU_SG_REL_ RDCM_CE SG_ 469 TCRRATR_CplReqTp 250;
BA_REL_ "GenSigTimeoutMsg" BU_SG_REL_ RDCM_CE SG_ 469 TCRRATR_CplReqTp 469;
BA_REL_ "GenSigSuprvResp" BU_SG_REL_ RDCM_CE SG_ 469 TCRRATR_CplReqTp 1;
BA_REL_ "GenSigTimeoutTime" BU_SG_REL_ RDCM_CE SG_ 469 TCRRATR_CplReqAct 250;
BA_REL_ "GenSigTimeoutMsg" BU_SG_REL_ RDCM_CE SG_ 469 TCRRATR_CplReqAct 469;
BA_REL_ "GenSigSuprvResp" BU_SG_REL_ RDCM_CE SG_ 469 TCRRATR_CplReqAct 1;
BA_REL_ "GenSigTimeoutTime" BU_SG_REL_ RDCM_CE SG_ 469 TwnClLRAxlTrqRqPVal 250;
BA_REL_ "GenSigTimeoutMsg" BU_SG_REL_ RDCM_CE SG_ 469 TwnClLRAxlTrqRqPVal 469;
BA_REL_ "GenSigSuprvResp" BU_SG_REL_ RDCM_CE SG_ 469 TwnClLRAxlTrqRqPVal 1;
BA_REL_ "GenSigTimeoutTime" BU_SG_REL_ RDCM_CE SG_ 469 TwnClLRAxlTrqRqARC 250;
BA_REL_ "GenSigTimeoutMsg" BU_SG_REL_ RDCM_CE SG_ 469 TwnClLRAxlTrqRqARC 469;
BA_REL_ "GenSigSuprvResp" BU_SG_REL_ RDCM_CE SG_ 469 TwnClLRAxlTrqRqARC 1;
BA_REL_ "GenSigTimeoutTime" BU_SG_REL_ RDCM_CE SG_ 469 TCLRATR_CplReqVal 250;
BA_REL_ "GenSigTimeoutMsg" BU_SG_REL_ RDCM_CE SG_ 469 TCLRATR_CplReqVal 469;
BA_REL_ "GenSigSuprvResp" BU_SG_REL_ RDCM_CE SG_ 469 TCLRATR_CplReqVal 1;
BA_REL_ "GenSigTimeoutTime" BU_SG_REL_ RDCM_CE SG_ 469 TCLRATR_CplReqTp 250;
BA_REL_ "GenSigTimeoutMsg" BU_SG_REL_ RDCM_CE SG_ 469 TCLRATR_CplReqTp 469;
BA_REL_ "GenSigSuprvResp" BU_SG_REL_ RDCM_CE SG_ 469 TCLRATR_CplReqTp 1;
BA_REL_ "GenSigTimeoutTime" BU_SG_REL_ RDCM_CE SG_ 469 TCLRATR_CplReqAct 250;
BA_REL_ "GenSigTimeoutMsg" BU_SG_REL_ RDCM_CE SG_ 469 TCLRATR_CplReqAct 469;
BA_REL_ "GenSigSuprvResp" BU_SG_REL_ RDCM_CE SG_ 469 TCLRATR_CplReqAct 1;
BA_REL_ "GenSigTimeoutTime" BU_SG_REL_ EBCM_OBD_CE SG_ 467 TwnClThrmlProtReqAct 250;
BA_REL_ "GenSigTimeoutMsg" BU_SG_REL_ EBCM_OBD_CE SG_ 467 TwnClThrmlProtReqAct 467;
BA_REL_ "GenSigSuprvResp" BU_SG_REL_ EBCM_OBD_CE SG_ 467 TwnClThrmlProtReqAct 1;
BA_REL_ "GenSigTimeoutTime" BU_SG_REL_ EBCM_CE SG_ 467 TwnClThrmlProtReqAct 250;
BA_REL_ "GenSigTimeoutMsg" BU_SG_REL_ EBCM_CE SG_ 467 TwnClThrmlProtReqAct 467;
BA_REL_ "GenSigSuprvResp" BU_SG_REL_ EBCM_CE SG_ 467 TwnClThrmlProtReqAct 1;
BA_REL_ "GenSigTimeoutTime" BU_SG_REL_ EBCM_OBD_CE SG_ 467 TwnCltchRrAxlRC 250;
BA_REL_ "GenSigTimeoutMsg" BU_SG_REL_ EBCM_OBD_CE SG_ 467 TwnCltchRrAxlRC 467;
BA_REL_ "GenSigSuprvResp" BU_SG_REL_ EBCM_OBD_CE SG_ 467 TwnCltchRrAxlRC 1;
BA_REL_ "GenSigTimeoutTime" BU_SG_REL_ EBCM_CE SG_ 467 TwnCltchRrAxlRC 250;
BA_REL_ "GenSigTimeoutMsg" BU_SG_REL_ EBCM_CE SG_ 467 TwnCltchRrAxlRC 467;
BA_REL_ "GenSigSuprvResp" BU_SG_REL_ EBCM_CE SG_ 467 TwnCltchRrAxlRC 1;
BA_REL_ "GenSigTimeoutTime" BU_SG_REL_ EBCM_OBD_CE SG_ 467 TwnCltchRrAxlMd 250;
BA_REL_ "GenSigTimeoutMsg" BU_SG_REL_ EBCM_OBD_CE SG_ 467 TwnCltchRrAxlMd 467;
BA_REL_ "GenSigSuprvResp" BU_SG_REL_ EBCM_OBD_CE SG_ 467 TwnCltchRrAxlMd 1;
BA_REL_ "GenSigTimeoutTime" BU_SG_REL_ EBCM_CE SG_ 467 TwnCltchRrAxlMd 250;
BA_REL_ "GenSigTimeoutMsg" BU_SG_REL_ EBCM_CE SG_ 467 TwnCltchRrAxlMd 467;
BA_REL_ "GenSigSuprvResp" BU_SG_REL_ EBCM_CE SG_ 467 TwnCltchRrAxlMd 1;
BA_REL_ "GenSigTimeoutTime" BU_SG_REL_ EBCM_OBD_CE SG_ 467 TwnCltchRrAxlCtrlStat 250;
BA_REL_ "GenSigTimeoutMsg" BU_SG_REL_ EBCM_OBD_CE SG_ 467 TwnCltchRrAxlCtrlStat 467;
BA_REL_ "GenSigSuprvResp" BU_SG_REL_ EBCM_OBD_CE SG_ 467 TwnCltchRrAxlCtrlStat 1;
BA_REL_ "GenSigTimeoutTime" BU_SG_REL_ EBCM_CE SG_ 467 TwnCltchRrAxlCtrlStat 250;
BA_REL_ "GenSigTimeoutMsg" BU_SG_REL_ EBCM_CE SG_ 467 TwnCltchRrAxlCtrlStat 467;
BA_REL_ "GenSigSuprvResp" BU_SG_REL_ EBCM_CE SG_ 467 TwnCltchRrAxlCtrlStat 1;
BA_REL_ "GenSigTimeoutTime" BU_SG_REL_ EBCM_OBD_CE SG_ 467 TwnCltchRrAxlChksm 250;
BA_REL_ "GenSigTimeoutMsg" BU_SG_REL_ EBCM_OBD_CE SG_ 467 TwnCltchRrAxlChksm 467;
BA_REL_ "GenSigSuprvResp" BU_SG_REL_ EBCM_OBD_CE SG_ 467 TwnCltchRrAxlChksm 1;
BA_REL_ "GenSigTimeoutTime" BU_SG_REL_ EBCM_CE SG_ 467 TwnCltchRrAxlChksm 250;
BA_REL_ "GenSigTimeoutMsg" BU_SG_REL_ EBCM_CE SG_ 467 TwnCltchRrAxlChksm 467;
BA_REL_ "GenSigSuprvResp" BU_SG_REL_ EBCM_CE SG_ 467 TwnCltchRrAxlChksm 1;
BA_REL_ "GenSigTimeoutTime" BU_SG_REL_ EBCM_OBD_CE SG_ 467 TwnClRrAxlThrmCap 250;
BA_REL_ "GenSigTimeoutMsg" BU_SG_REL_ EBCM_OBD_CE SG_ 467 TwnClRrAxlThrmCap 467;
BA_REL_ "GenSigSuprvResp" BU_SG_REL_ EBCM_OBD_CE SG_ 467 TwnClRrAxlThrmCap 1;
BA_REL_ "GenSigTimeoutTime" BU_SG_REL_ EBCM_CE SG_ 467 TwnClRrAxlThrmCap 250;
BA_REL_ "GenSigTimeoutMsg" BU_SG_REL_ EBCM_CE SG_ 467 TwnClRrAxlThrmCap 467;
BA_REL_ "GenSigSuprvResp" BU_SG_REL_ EBCM_CE SG_ 467 TwnClRrAxlThrmCap 1;
BA_REL_ "GenSigTimeoutTime" BU_SG_REL_ EBCM_OBD_CE SG_ 467 RtRrAxlEstTrq 250;
BA_REL_ "GenSigTimeoutMsg" BU_SG_REL_ EBCM_OBD_CE SG_ 467 RtRrAxlEstTrq 467;
BA_REL_ "GenSigSuprvResp" BU_SG_REL_ EBCM_OBD_CE SG_ 467 RtRrAxlEstTrq 1;
BA_REL_ "GenSigTimeoutTime" BU_SG_REL_ EBCM_CE SG_ 467 RtRrAxlEstTrq 250;
BA_REL_ "GenSigTimeoutMsg" BU_SG_REL_ EBCM_CE SG_ 467 RtRrAxlEstTrq 467;
BA_REL_ "GenSigSuprvResp" BU_SG_REL_ EBCM_CE SG_ 467 RtRrAxlEstTrq 1;
BA_REL_ "GenSigTimeoutTime" BU_SG_REL_ EBCM_OBD_CE SG_ 467 LtRrAxlEstTrq 250;
BA_REL_ "GenSigTimeoutMsg" BU_SG_REL_ EBCM_OBD_CE SG_ 467 LtRrAxlEstTrq 467;
BA_REL_ "GenSigSuprvResp" BU_SG_REL_ EBCM_OBD_CE SG_ 467 LtRrAxlEstTrq 1;
BA_REL_ "GenSigTimeoutTime" BU_SG_REL_ EBCM_CE SG_ 467 LtRrAxlEstTrq 250;
BA_REL_ "GenSigTimeoutMsg" BU_SG_REL_ EBCM_CE SG_ 467 LtRrAxlEstTrq 467;
BA_REL_ "GenSigSuprvResp" BU_SG_REL_ EBCM_CE SG_ 467 LtRrAxlEstTrq 1;
BA_REL_ "GenSigTimeoutTime" BU_SG_REL_ EBCM_OBD_CE SG_ 467 TwnCltchRrAxlCtrlMd 250;
BA_REL_ "GenSigTimeoutMsg" BU_SG_REL_ EBCM_OBD_CE SG_ 467 TwnCltchRrAxlCtrlMd 467;
BA_REL_ "GenSigSuprvResp" BU_SG_REL_ EBCM_OBD_CE SG_ 467 TwnCltchRrAxlCtrlMd 1;
BA_REL_ "GenSigTimeoutTime" BU_SG_REL_ EBCM_CE SG_ 467 TwnCltchRrAxlCtrlMd 250;
BA_REL_ "GenSigTimeoutMsg" BU_SG_REL_ EBCM_CE SG_ 467 TwnCltchRrAxlCtrlMd 467;
BA_REL_ "GenSigSuprvResp" BU_SG_REL_ EBCM_CE SG_ 467 TwnCltchRrAxlCtrlMd 1;
BA_REL_ "GenSigTimeoutTime" BU_SG_REL_ EBCM_OBD_CE SG_ 467 TwnCltchRrAxlStat 250;
BA_REL_ "GenSigTimeoutMsg" BU_SG_REL_ EBCM_OBD_CE SG_ 467 TwnCltchRrAxlStat 467;
BA_REL_ "GenSigSuprvResp" BU_SG_REL_ EBCM_OBD_CE SG_ 467 TwnCltchRrAxlStat 1;
BA_REL_ "GenSigTimeoutTime" BU_SG_REL_ EBCM_CE SG_ 467 TwnCltchRrAxlStat 250;
BA_REL_ "GenSigTimeoutMsg" BU_SG_REL_ EBCM_CE SG_ 467 TwnCltchRrAxlStat 467;
BA_REL_ "GenSigSuprvResp" BU_SG_REL_ EBCM_CE SG_ 467 TwnCltchRrAxlStat 1;
BA_REL_ "GenSigTimeoutTime" BU_SG_REL_ ICCM_CE SG_ 817 RrAxlActrEstmtdTrq 250;
BA_REL_ "GenSigTimeoutMsg" BU_SG_REL_ ICCM_CE SG_ 817 RrAxlActrEstmtdTrq 817;
BA_REL_ "GenSigSuprvResp" BU_SG_REL_ ICCM_CE SG_ 817 RrAxlActrEstmtdTrq 1;
BA_REL_ "GenSigTimeoutTime" BU_SG_REL_ ICCM_CE SG_ 817 RrAxlActrThrmlCpcty 250;
BA_REL_ "GenSigTimeoutMsg" BU_SG_REL_ ICCM_CE SG_ 817 RrAxlActrThrmlCpcty 817;
BA_REL_ "GenSigSuprvResp" BU_SG_REL_ ICCM_CE SG_ 817 RrAxlActrThrmlCpcty 1;
BA_REL_ "GenSigTimeoutTime" BU_SG_REL_ ICCM_CE SG_ 817 RrAxlActrStat 250;
BA_REL_ "GenSigTimeoutMsg" BU_SG_REL_ ICCM_CE SG_ 817 RrAxlActrStat 817;
BA_REL_ "GenSigSuprvResp" BU_SG_REL_ ICCM_CE SG_ 817 RrAxlActrStat 1;
BA_REL_ "GenSigTimeoutTime" BU_SG_REL_ RDCM_CE SG_ 566 RrAxlEstmtdRngGrTrq 250;
BA_REL_ "GenSigTimeoutMsg" BU_SG_REL_ RDCM_CE SG_ 566 RrAxlEstmtdRngGrTrq 566;
BA_REL_ "GenSigSuprvResp" BU_SG_REL_ RDCM_CE SG_ 566 RrAxlEstmtdRngGrTrq 1;
BA_REL_ "GenSigTimeoutTime" BU_SG_REL_ RDCM_CE SG_ 566 RrAxlActrTrqRqstRC 250;
BA_REL_ "GenSigSuprvResp" BU_SG_REL_ RDCM_CE SG_ 566 RrAxlActrTrqRqstRC 1;
BA_REL_ "GenSigTimeoutTime" BU_SG_REL_ RDCM_CE SG_ 566 RrAxlActrTrqRqstPVal 250;
BA_REL_ "GenSigSuprvResp" BU_SG_REL_ RDCM_CE SG_ 566 RrAxlActrTrqRqstPVal 1;
BA_REL_ "GenSigTimeoutTime" BU_SG_REL_ RDCM_CE SG_ 566 RAATR_RrAxlTrqVl 250;
BA_REL_ "GenSigSuprvResp" BU_SG_REL_ RDCM_CE SG_ 566 RAATR_RrAxlTrqVl 1;
BA_REL_ "GenSigTimeoutTime" BU_SG_REL_ RDCM_CE SG_ 566 RAATR_RrAxlMdRqst 250;
BA_REL_ "GenSigSuprvResp" BU_SG_REL_ RDCM_CE SG_ 566 RAATR_RrAxlMdRqst 1;
BA_REL_ "GenSigTimeoutTime" BU_SG_REL_ FCM_CE SG_ 320 IMULonAccPri 250;
BA_REL_ "GenSigTimeoutMsg" BU_SG_REL_ FCM_CE SG_ 320 IMULonAccPri 320;
BA_REL_ "GenSigSuprvResp" BU_SG_REL_ FCM_CE SG_ 320 IMULonAccPri 1;
BA_REL_ "GenSigTimeoutTime" BU_SG_REL_ EPS_JR_CE SG_ 320 IMULonAccPri 250;
BA_REL_ "GenSigTimeoutMsg" BU_SG_REL_ EPS_JR_CE SG_ 320 IMULonAccPri 320;
BA_REL_ "GenSigSuprvResp" BU_SG_REL_ EPS_JR_CE SG_ 320 IMULonAccPri 1;
BA_REL_ "GenSigTimeoutTime" BU_SG_REL_ EPS_CE SG_ 320 IMULonAccPri 250;
BA_REL_ "GenSigTimeoutMsg" BU_SG_REL_ EPS_CE SG_ 320 IMULonAccPri 320;
BA_REL_ "GenSigSuprvResp" BU_SG_REL_ EPS_CE SG_ 320 IMULonAccPri 1;
BA_REL_ "GenSigTimeoutTime" BU_SG_REL_ APA_CE SG_ 320 IMUXAxisClbrtd 250;
BA_REL_ "GenSigTimeoutMsg" BU_SG_REL_ APA_CE SG_ 320 IMUXAxisClbrtd 320;
BA_REL_ "GenSigSuprvResp" BU_SG_REL_ APA_CE SG_ 320 IMUXAxisClbrtd 1;
BA_REL_ "GenSigTimeoutTime" BU_SG_REL_ FCM_CE SG_ 320 IMUXAxisClbrtd 250;
BA_REL_ "GenSigTimeoutMsg" BU_SG_REL_ FCM_CE SG_ 320 IMUXAxisClbrtd 320;
BA_REL_ "GenSigSuprvResp" BU_SG_REL_ FCM_CE SG_ 320 IMUXAxisClbrtd 1;
BA_REL_ "GenSigTimeoutTime" BU_SG_REL_ EPS_JR_CE SG_ 320 IMUXAxisClbrtd 250;
BA_REL_ "GenSigTimeoutMsg" BU_SG_REL_ EPS_JR_CE SG_ 320 IMUXAxisClbrtd 320;
BA_REL_ "GenSigSuprvResp" BU_SG_REL_ EPS_JR_CE SG_ 320 IMUXAxisClbrtd 1;
BA_REL_ "GenSigTimeoutTime" BU_SG_REL_ EPS_CE SG_ 320 IMUXAxisClbrtd 250;
BA_REL_ "GenSigTimeoutMsg" BU_SG_REL_ EPS_CE SG_ 320 IMUXAxisClbrtd 320;
BA_REL_ "GenSigSuprvResp" BU_SG_REL_ EPS_CE SG_ 320 IMUXAxisClbrtd 1;
BA_REL_ "GenSigTimeoutTime" BU_SG_REL_ APA_CE SG_ 320 IMUXAxisOrntn 250;
BA_REL_ "GenSigTimeoutMsg" BU_SG_REL_ APA_CE SG_ 320 IMUXAxisOrntn 320;
BA_REL_ "GenSigSuprvResp" BU_SG_REL_ APA_CE SG_ 320 IMUXAxisOrntn 1;
BA_REL_ "GenSigTimeoutTime" BU_SG_REL_ FCM_CE SG_ 320 IMUXAxisOrntn 250;
BA_REL_ "GenSigTimeoutMsg" BU_SG_REL_ FCM_CE SG_ 320 IMUXAxisOrntn 320;
BA_REL_ "GenSigSuprvResp" BU_SG_REL_ FCM_CE SG_ 320 IMUXAxisOrntn 1;
BA_REL_ "GenSigTimeoutTime" BU_SG_REL_ EPS_JR_CE SG_ 320 IMUXAxisOrntn 250;
BA_REL_ "GenSigTimeoutMsg" BU_SG_REL_ EPS_JR_CE SG_ 320 IMUXAxisOrntn 320;
BA_REL_ "GenSigSuprvResp" BU_SG_REL_ EPS_JR_CE SG_ 320 IMUXAxisOrntn 1;
BA_REL_ "GenSigTimeoutTime" BU_SG_REL_ EPS_CE SG_ 320 IMUXAxisOrntn 250;
BA_REL_ "GenSigTimeoutMsg" BU_SG_REL_ EPS_CE SG_ 320 IMUXAxisOrntn 320;
BA_REL_ "GenSigSuprvResp" BU_SG_REL_ EPS_CE SG_ 320 IMUXAxisOrntn 1;
BA_REL_ "GenSigTimeoutTime" BU_SG_REL_ APA_CE SG_ 320 IMUPriYawDrftTyp 250;
BA_REL_ "GenSigTimeoutMsg" BU_SG_REL_ APA_CE SG_ 320 IMUPriYawDrftTyp 320;
BA_REL_ "GenSigSuprvResp" BU_SG_REL_ APA_CE SG_ 320 IMUPriYawDrftTyp 1;
BA_REL_ "GenSigTimeoutTime" BU_SG_REL_ FCM_CE SG_ 320 IMUPriYawDrftTyp 250;
BA_REL_ "GenSigTimeoutMsg" BU_SG_REL_ FCM_CE SG_ 320 IMUPriYawDrftTyp 320;
BA_REL_ "GenSigSuprvResp" BU_SG_REL_ FCM_CE SG_ 320 IMUPriYawDrftTyp 1;
BA_REL_ "GenSigTimeoutTime" BU_SG_REL_ EPS_JR_CE SG_ 320 IMUPriYawDrftTyp 250;
BA_REL_ "GenSigTimeoutMsg" BU_SG_REL_ EPS_JR_CE SG_ 320 IMUPriYawDrftTyp 320;
BA_REL_ "GenSigSuprvResp" BU_SG_REL_ EPS_JR_CE SG_ 320 IMUPriYawDrftTyp 1;
BA_REL_ "GenSigTimeoutTime" BU_SG_REL_ EPS_CE SG_ 320 IMUPriYawDrftTyp 250;
BA_REL_ "GenSigTimeoutMsg" BU_SG_REL_ EPS_CE SG_ 320 IMUPriYawDrftTyp 320;
BA_REL_ "GenSigSuprvResp" BU_SG_REL_ EPS_CE SG_ 320 IMUPriYawDrftTyp 1;
BA_REL_ "GenSigTimeoutTime" BU_SG_REL_ FCM_CE SG_ 320 IMUChksumSec 250;
BA_REL_ "GenSigTimeoutMsg" BU_SG_REL_ FCM_CE SG_ 320 IMUChksumSec 320;
BA_REL_ "GenSigSuprvResp" BU_SG_REL_ FCM_CE SG_ 320 IMUChksumSec 1;
BA_REL_ "GenSigTimeoutTime" BU_SG_REL_ EPS_JR_CE SG_ 320 IMUChksumSec 250;
BA_REL_ "GenSigTimeoutMsg" BU_SG_REL_ EPS_JR_CE SG_ 320 IMUChksumSec 320;
BA_REL_ "GenSigSuprvResp" BU_SG_REL_ EPS_JR_CE SG_ 320 IMUChksumSec 1;
BA_REL_ "GenSigTimeoutTime" BU_SG_REL_ EPS_CE SG_ 320 IMUChksumSec 250;
BA_REL_ "GenSigTimeoutMsg" BU_SG_REL_ EPS_CE SG_ 320 IMUChksumSec 320;
BA_REL_ "GenSigSuprvResp" BU_SG_REL_ EPS_CE SG_ 320 IMUChksumSec 1;
BA_REL_ "GenSigTimeoutTime" BU_SG_REL_ APA_CE SG_ 320 IMUYawRtSecAval 250;
BA_REL_ "GenSigTimeoutMsg" BU_SG_REL_ APA_CE SG_ 320 IMUYawRtSecAval 320;
BA_REL_ "GenSigSuprvResp" BU_SG_REL_ APA_CE SG_ 320 IMUYawRtSecAval 1;
BA_REL_ "GenSigTimeoutTime" BU_SG_REL_ FCM_CE SG_ 320 IMUYawRtSecAval 250;
BA_REL_ "GenSigTimeoutMsg" BU_SG_REL_ FCM_CE SG_ 320 IMUYawRtSecAval 320;
BA_REL_ "GenSigSuprvResp" BU_SG_REL_ FCM_CE SG_ 320 IMUYawRtSecAval 1;
BA_REL_ "GenSigTimeoutTime" BU_SG_REL_ EPS_JR_CE SG_ 320 IMUYawRtSecAval 250;
BA_REL_ "GenSigTimeoutMsg" BU_SG_REL_ EPS_JR_CE SG_ 320 IMUYawRtSecAval 320;
BA_REL_ "GenSigSuprvResp" BU_SG_REL_ EPS_JR_CE SG_ 320 IMUYawRtSecAval 1;
BA_REL_ "GenSigTimeoutTime" BU_SG_REL_ EPS_CE SG_ 320 IMUYawRtSecAval 250;
BA_REL_ "GenSigTimeoutMsg" BU_SG_REL_ EPS_CE SG_ 320 IMUYawRtSecAval 320;
BA_REL_ "GenSigSuprvResp" BU_SG_REL_ EPS_CE SG_ 320 IMUYawRtSecAval 1;
BA_REL_ "GenSigTimeoutTime" BU_SG_REL_ APA_CE SG_ 320 IMULatAccSecAval 250;
BA_REL_ "GenSigTimeoutMsg" BU_SG_REL_ APA_CE SG_ 320 IMULatAccSecAval 320;
BA_REL_ "GenSigSuprvResp" BU_SG_REL_ APA_CE SG_ 320 IMULatAccSecAval 1;
BA_REL_ "GenSigTimeoutTime" BU_SG_REL_ FCM_CE SG_ 320 IMULatAccSecAval 250;
BA_REL_ "GenSigTimeoutMsg" BU_SG_REL_ FCM_CE SG_ 320 IMULatAccSecAval 320;
BA_REL_ "GenSigSuprvResp" BU_SG_REL_ FCM_CE SG_ 320 IMULatAccSecAval 1;
BA_REL_ "GenSigTimeoutTime" BU_SG_REL_ EPS_JR_CE SG_ 320 IMULatAccSecAval 250;
BA_REL_ "GenSigTimeoutMsg" BU_SG_REL_ EPS_JR_CE SG_ 320 IMULatAccSecAval 320;
BA_REL_ "GenSigSuprvResp" BU_SG_REL_ EPS_JR_CE SG_ 320 IMULatAccSecAval 1;
BA_REL_ "GenSigTimeoutTime" BU_SG_REL_ EPS_CE SG_ 320 IMULatAccSecAval 250;
BA_REL_ "GenSigTimeoutMsg" BU_SG_REL_ EPS_CE SG_ 320 IMULatAccSecAval 320;
BA_REL_ "GenSigSuprvResp" BU_SG_REL_ EPS_CE SG_ 320 IMULatAccSecAval 1;
BA_REL_ "GenSigTimeoutTime" BU_SG_REL_ APA_CE SG_ 320 IMURollCntSec 250;
BA_REL_ "GenSigTimeoutMsg" BU_SG_REL_ APA_CE SG_ 320 IMURollCntSec 320;
BA_REL_ "GenSigSuprvResp" BU_SG_REL_ APA_CE SG_ 320 IMURollCntSec 1;
BA_REL_ "GenSigTimeoutTime" BU_SG_REL_ FCM_CE SG_ 320 IMURollCntSec 250;
BA_REL_ "GenSigTimeoutMsg" BU_SG_REL_ FCM_CE SG_ 320 IMURollCntSec 320;
BA_REL_ "GenSigSuprvResp" BU_SG_REL_ FCM_CE SG_ 320 IMURollCntSec 1;
BA_REL_ "GenSigTimeoutTime" BU_SG_REL_ EOCM_F_CE SG_ 320 IMURollCntSec 120;
BA_REL_ "GenSigTimeoutMsg" BU_SG_REL_ EOCM_F_CE SG_ 320 IMURollCntSec 320;
BA_REL_ "GenSigSuprvResp" BU_SG_REL_ EOCM_F_CE SG_ 320 IMURollCntSec 1;
BA_REL_ "GenSigTimeoutTime" BU_SG_REL_ EPS_JR_CE SG_ 320 IMURollCntSec 250;
BA_REL_ "GenSigTimeoutMsg" BU_SG_REL_ EPS_JR_CE SG_ 320 IMURollCntSec 320;
BA_REL_ "GenSigSuprvResp" BU_SG_REL_ EPS_JR_CE SG_ 320 IMURollCntSec 1;
BA_REL_ "GenSigTimeoutTime" BU_SG_REL_ EPS_CE SG_ 320 IMURollCntSec 250;
BA_REL_ "GenSigTimeoutMsg" BU_SG_REL_ EPS_CE SG_ 320 IMURollCntSec 320;
BA_REL_ "GenSigSuprvResp" BU_SG_REL_ EPS_CE SG_ 320 IMURollCntSec 1;
BA_REL_ "GenSigTimeoutTime" BU_SG_REL_ APA_CE SG_ 320 IMUYawRtSec 250;
BA_REL_ "GenSigTimeoutMsg" BU_SG_REL_ APA_CE SG_ 320 IMUYawRtSec 320;
BA_REL_ "GenSigSuprvResp" BU_SG_REL_ APA_CE SG_ 320 IMUYawRtSec 1;
BA_REL_ "GenSigTimeoutTime" BU_SG_REL_ FCM_CE SG_ 320 IMUYawRtSec 250;
BA_REL_ "GenSigTimeoutMsg" BU_SG_REL_ FCM_CE SG_ 320 IMUYawRtSec 320;
BA_REL_ "GenSigSuprvResp" BU_SG_REL_ FCM_CE SG_ 320 IMUYawRtSec 1;
BA_REL_ "GenSigTimeoutTime" BU_SG_REL_ ACC_CE SG_ 320 IMUYawRtSec 125;
BA_REL_ "GenSigTimeoutMsg" BU_SG_REL_ ACC_CE SG_ 320 IMUYawRtSec 320;
BA_REL_ "GenSigSuprvResp" BU_SG_REL_ ACC_CE SG_ 320 IMUYawRtSec 1;
BA_REL_ "GenSigTimeoutTime" BU_SG_REL_ EPS_JR_CE SG_ 320 IMUYawRtSec 250;
BA_REL_ "GenSigTimeoutMsg" BU_SG_REL_ EPS_JR_CE SG_ 320 IMUYawRtSec 320;
BA_REL_ "GenSigSuprvResp" BU_SG_REL_ EPS_JR_CE SG_ 320 IMUYawRtSec 1;
BA_REL_ "GenSigTimeoutTime" BU_SG_REL_ EPS_CE SG_ 320 IMUYawRtSec 250;
BA_REL_ "GenSigTimeoutMsg" BU_SG_REL_ EPS_CE SG_ 320 IMUYawRtSec 320;
BA_REL_ "GenSigSuprvResp" BU_SG_REL_ EPS_CE SG_ 320 IMUYawRtSec 1;
BA_REL_ "GenSigTimeoutTime" BU_SG_REL_ APA_CE SG_ 320 IMULatACCSec 250;
BA_REL_ "GenSigTimeoutMsg" BU_SG_REL_ APA_CE SG_ 320 IMULatACCSec 320;
BA_REL_ "GenSigSuprvResp" BU_SG_REL_ APA_CE SG_ 320 IMULatACCSec 1;
BA_REL_ "GenSigTimeoutTime" BU_SG_REL_ FCM_CE SG_ 320 IMULatACCSec 250;
BA_REL_ "GenSigTimeoutMsg" BU_SG_REL_ FCM_CE SG_ 320 IMULatACCSec 320;
BA_REL_ "GenSigSuprvResp" BU_SG_REL_ FCM_CE SG_ 320 IMULatACCSec 1;
BA_REL_ "GenSigTimeoutTime" BU_SG_REL_ EPS_JR_CE SG_ 320 IMULatACCSec 250;
BA_REL_ "GenSigTimeoutMsg" BU_SG_REL_ EPS_JR_CE SG_ 320 IMULatACCSec 320;
BA_REL_ "GenSigSuprvResp" BU_SG_REL_ EPS_JR_CE SG_ 320 IMULatACCSec 1;
BA_REL_ "GenSigTimeoutTime" BU_SG_REL_ EPS_CE SG_ 320 IMULatACCSec 250;
BA_REL_ "GenSigTimeoutMsg" BU_SG_REL_ EPS_CE SG_ 320 IMULatACCSec 320;
BA_REL_ "GenSigSuprvResp" BU_SG_REL_ EPS_CE SG_ 320 IMULatACCSec 1;
BA_REL_ "GenSigTimeoutTime" BU_SG_REL_ EBCM_OBD_CE SG_ 320 IMULatACCSec 25;
BA_REL_ "GenSigTimeoutMsg" BU_SG_REL_ EBCM_OBD_CE SG_ 320 IMULatACCSec 320;
BA_REL_ "GenSigSuprvResp" BU_SG_REL_ EBCM_OBD_CE SG_ 320 IMULatACCSec 1;
BA_REL_ "GenSigTimeoutTime" BU_SG_REL_ EBCM_CE SG_ 320 IMULatACCSec 25;
BA_REL_ "GenSigTimeoutMsg" BU_SG_REL_ EBCM_CE SG_ 320 IMULatACCSec 320;
BA_REL_ "GenSigSuprvResp" BU_SG_REL_ EBCM_CE SG_ 320 IMULatACCSec 1;
BA_REL_ "GenSigTimeoutTime" BU_SG_REL_ EBOOST_CE SG_ 290 BkupPwrModeMstrVDA 250;
BA_REL_ "GenSigTimeoutMsg" BU_SG_REL_ EBOOST_CE SG_ 290 BkupPwrModeMstrVDA 290;
BA_REL_ "GenSigSuprvResp" BU_SG_REL_ EBOOST_CE SG_ 290 BkupPwrModeMstrVDA 1;
BA_REL_ "GenSigTimeoutTime" BU_SG_REL_ TRCM_CE SG_ 290 BkupPwrModeMstrVDA 250;
BA_REL_ "GenSigTimeoutMsg" BU_SG_REL_ TRCM_CE SG_ 290 BkupPwrModeMstrVDA 290;
BA_REL_ "GenSigSuprvResp" BU_SG_REL_ TRCM_CE SG_ 290 BkupPwrModeMstrVDA 1;
BA_REL_ "GenSigTimeoutTime" BU_SG_REL_ EPS_JR_CE SG_ 290 BkupPwrModeMstrVDA 250;
BA_REL_ "GenSigTimeoutMsg" BU_SG_REL_ EPS_JR_CE SG_ 290 BkupPwrModeMstrVDA 290;
BA_REL_ "GenSigSuprvResp" BU_SG_REL_ EPS_JR_CE SG_ 290 BkupPwrModeMstrVDA 1;
BA_REL_ "GenSigTimeoutTime" BU_SG_REL_ MSB1_CE SG_ 290 BkupPwrModeMstrVDA 250;
BA_REL_ "GenSigTimeoutMsg" BU_SG_REL_ MSB1_CE SG_ 290 BkupPwrModeMstrVDA 290;
BA_REL_ "GenSigSuprvResp" BU_SG_REL_ MSB1_CE SG_ 290 BkupPwrModeMstrVDA 1;
BA_REL_ "GenSigTimeoutTime" BU_SG_REL_ MSB2_CE SG_ 290 BkupPwrModeMstrVDA 250;
BA_REL_ "GenSigTimeoutMsg" BU_SG_REL_ MSB2_CE SG_ 290 BkupPwrModeMstrVDA 290;
BA_REL_ "GenSigSuprvResp" BU_SG_REL_ MSB2_CE SG_ 290 BkupPwrModeMstrVDA 1;
BA_REL_ "GenSigTimeoutTime" BU_SG_REL_ SDM_CE SG_ 290 BkupPwrModeMstrVDA 250;
BA_REL_ "GenSigTimeoutMsg" BU_SG_REL_ SDM_CE SG_ 290 BkupPwrModeMstrVDA 290;
BA_REL_ "GenSigSuprvResp" BU_SG_REL_ SDM_CE SG_ 290 BkupPwrModeMstrVDA 1;
BA_REL_ "GenSigTimeoutTime" BU_SG_REL_ FCM_CE SG_ 290 BkupPwrModeMstrVDA 250;
BA_REL_ "GenSigTimeoutMsg" BU_SG_REL_ FCM_CE SG_ 290 BkupPwrModeMstrVDA 290;
BA_REL_ "GenSigSuprvResp" BU_SG_REL_ FCM_CE SG_ 290 BkupPwrModeMstrVDA 1;
BA_REL_ "GenSigTimeoutTime" BU_SG_REL_ IMU_CE SG_ 290 BkupPwrModeMstrVDA 250;
BA_REL_ "GenSigTimeoutMsg" BU_SG_REL_ IMU_CE SG_ 290 BkupPwrModeMstrVDA 290;
BA_REL_ "GenSigSuprvResp" BU_SG_REL_ IMU_CE SG_ 290 BkupPwrModeMstrVDA 1;
BA_REL_ "GenSigTimeoutTime" BU_SG_REL_ SAS_CE SG_ 290 BkupPwrModeMstrVDA 250;
BA_REL_ "GenSigTimeoutMsg" BU_SG_REL_ SAS_CE SG_ 290 BkupPwrModeMstrVDA 290;
BA_REL_ "GenSigSuprvResp" BU_SG_REL_ SAS_CE SG_ 290 BkupPwrModeMstrVDA 1;
BA_REL_ "GenSigTimeoutTime" BU_SG_REL_ EBOOST_CE SG_ 290 SysBkupPwrMdEn 250;
BA_REL_ "GenSigTimeoutMsg" BU_SG_REL_ EBOOST_CE SG_ 290 SysBkupPwrMdEn 290;
BA_REL_ "GenSigSuprvResp" BU_SG_REL_ EBOOST_CE SG_ 290 SysBkupPwrMdEn 1;
BA_REL_ "GenSigTimeoutTime" BU_SG_REL_ TRCM_CE SG_ 290 SysBkupPwrMdEn 250;
BA_REL_ "GenSigTimeoutMsg" BU_SG_REL_ TRCM_CE SG_ 290 SysBkupPwrMdEn 290;
BA_REL_ "GenSigSuprvResp" BU_SG_REL_ TRCM_CE SG_ 290 SysBkupPwrMdEn 1;
BA_REL_ "GenSigTimeoutTime" BU_SG_REL_ EPS_JR_CE SG_ 290 SysBkupPwrMdEn 250;
BA_REL_ "GenSigTimeoutMsg" BU_SG_REL_ EPS_JR_CE SG_ 290 SysBkupPwrMdEn 290;
BA_REL_ "GenSigSuprvResp" BU_SG_REL_ EPS_JR_CE SG_ 290 SysBkupPwrMdEn 1;
BA_REL_ "GenSigTimeoutTime" BU_SG_REL_ MSB1_CE SG_ 290 SysBkupPwrMdEn 250;
BA_REL_ "GenSigTimeoutMsg" BU_SG_REL_ MSB1_CE SG_ 290 SysBkupPwrMdEn 290;
BA_REL_ "GenSigSuprvResp" BU_SG_REL_ MSB1_CE SG_ 290 SysBkupPwrMdEn 1;
BA_REL_ "GenSigTimeoutTime" BU_SG_REL_ MSB2_CE SG_ 290 SysBkupPwrMdEn 250;
BA_REL_ "GenSigTimeoutMsg" BU_SG_REL_ MSB2_CE SG_ 290 SysBkupPwrMdEn 290;
BA_REL_ "GenSigSuprvResp" BU_SG_REL_ MSB2_CE SG_ 290 SysBkupPwrMdEn 1;
BA_REL_ "GenSigTimeoutTime" BU_SG_REL_ SDM_CE SG_ 290 SysBkupPwrMdEn 250;
BA_REL_ "GenSigTimeoutMsg" BU_SG_REL_ SDM_CE SG_ 290 SysBkupPwrMdEn 290;
BA_REL_ "GenSigSuprvResp" BU_SG_REL_ SDM_CE SG_ 290 SysBkupPwrMdEn 1;
BA_REL_ "GenSigTimeoutTime" BU_SG_REL_ FCM_CE SG_ 290 SysBkupPwrMdEn 250;
BA_REL_ "GenSigTimeoutMsg" BU_SG_REL_ FCM_CE SG_ 290 SysBkupPwrMdEn 290;
BA_REL_ "GenSigSuprvResp" BU_SG_REL_ FCM_CE SG_ 290 SysBkupPwrMdEn 1;
BA_REL_ "GenSigTimeoutTime" BU_SG_REL_ IMU_CE SG_ 290 SysBkupPwrMdEn 250;
BA_REL_ "GenSigTimeoutMsg" BU_SG_REL_ IMU_CE SG_ 290 SysBkupPwrMdEn 290;
BA_REL_ "GenSigSuprvResp" BU_SG_REL_ IMU_CE SG_ 290 SysBkupPwrMdEn 1;
BA_REL_ "GenSigTimeoutTime" BU_SG_REL_ SAS_CE SG_ 290 SysBkupPwrMdEn 250;
BA_REL_ "GenSigTimeoutMsg" BU_SG_REL_ SAS_CE SG_ 290 SysBkupPwrMdEn 290;
BA_REL_ "GenSigSuprvResp" BU_SG_REL_ SAS_CE SG_ 290 SysBkupPwrMdEn 1;
BA_REL_ "GenSigTimeoutTime" BU_SG_REL_ EBOOST_CE SG_ 290 SysBkUpPwrMd 250;
BA_REL_ "GenSigTimeoutMsg" BU_SG_REL_ EBOOST_CE SG_ 290 SysBkUpPwrMd 290;
BA_REL_ "GenSigSuprvResp" BU_SG_REL_ EBOOST_CE SG_ 290 SysBkUpPwrMd 1;
BA_REL_ "GenSigVDAFailResp" BU_SG_REL_ EBOOST_CE SG_ 290 SysBkUpPwrMd 1;
BA_REL_ "GenSigVDAFailComment" BU_SG_REL_ EBOOST_CE SG_ 290 SysBkUpPwrMd "Backup Power Mode Master Virtual Device Availability";
BA_REL_ "GenSigTimeoutTime" BU_SG_REL_ TRCM_CE SG_ 290 SysBkUpPwrMd 250;
BA_REL_ "GenSigTimeoutMsg" BU_SG_REL_ TRCM_CE SG_ 290 SysBkUpPwrMd 290;
BA_REL_ "GenSigSuprvResp" BU_SG_REL_ TRCM_CE SG_ 290 SysBkUpPwrMd 1;
BA_REL_ "GenSigVDAFailResp" BU_SG_REL_ TRCM_CE SG_ 290 SysBkUpPwrMd 1;
BA_REL_ "GenSigVDAFailComment" BU_SG_REL_ TRCM_CE SG_ 290 SysBkUpPwrMd "Backup Power Mode Master Virtual Device Availability";
BA_REL_ "GenSigTimeoutTime" BU_SG_REL_ EPS_JR_CE SG_ 290 SysBkUpPwrMd 250;
BA_REL_ "GenSigTimeoutMsg" BU_SG_REL_ EPS_JR_CE SG_ 290 SysBkUpPwrMd 290;
BA_REL_ "GenSigSuprvResp" BU_SG_REL_ EPS_JR_CE SG_ 290 SysBkUpPwrMd 1;
BA_REL_ "GenSigVDAFailResp" BU_SG_REL_ EPS_JR_CE SG_ 290 SysBkUpPwrMd 1;
BA_REL_ "GenSigVDAFailComment" BU_SG_REL_ EPS_JR_CE SG_ 290 SysBkUpPwrMd "Backup Power Mode Master Virtual Device Availability";
BA_REL_ "GenSigTimeoutTime" BU_SG_REL_ MSB1_CE SG_ 290 SysBkUpPwrMd 250;
BA_REL_ "GenSigTimeoutMsg" BU_SG_REL_ MSB1_CE SG_ 290 SysBkUpPwrMd 290;
BA_REL_ "GenSigSuprvResp" BU_SG_REL_ MSB1_CE SG_ 290 SysBkUpPwrMd 1;
BA_REL_ "GenSigVDAFailResp" BU_SG_REL_ MSB1_CE SG_ 290 SysBkUpPwrMd 1;
BA_REL_ "GenSigVDAFailComment" BU_SG_REL_ MSB1_CE SG_ 290 SysBkUpPwrMd "Backup Power Mode Master Virtual Device Availability";
BA_REL_ "GenSigTimeoutTime" BU_SG_REL_ MSB2_CE SG_ 290 SysBkUpPwrMd 250;
BA_REL_ "GenSigTimeoutMsg" BU_SG_REL_ MSB2_CE SG_ 290 SysBkUpPwrMd 290;
BA_REL_ "GenSigSuprvResp" BU_SG_REL_ MSB2_CE SG_ 290 SysBkUpPwrMd 1;
BA_REL_ "GenSigVDAFailResp" BU_SG_REL_ MSB2_CE SG_ 290 SysBkUpPwrMd 1;
BA_REL_ "GenSigVDAFailComment" BU_SG_REL_ MSB2_CE SG_ 290 SysBkUpPwrMd "Backup Power Mode Master Virtual Device Availability";
BA_REL_ "GenSigTimeoutTime" BU_SG_REL_ SDM_CE SG_ 290 SysBkUpPwrMd 250;
BA_REL_ "GenSigTimeoutMsg" BU_SG_REL_ SDM_CE SG_ 290 SysBkUpPwrMd 290;
BA_REL_ "GenSigSuprvResp" BU_SG_REL_ SDM_CE SG_ 290 SysBkUpPwrMd 1;
BA_REL_ "GenSigVDAFailResp" BU_SG_REL_ SDM_CE SG_ 290 SysBkUpPwrMd 1;
BA_REL_ "GenSigVDAFailComment" BU_SG_REL_ SDM_CE SG_ 290 SysBkUpPwrMd "Backup Power Mode Master Virtual Device Availability";
BA_REL_ "GenSigTimeoutTime" BU_SG_REL_ FCM_CE SG_ 290 SysBkUpPwrMd 250;
BA_REL_ "GenSigTimeoutMsg" BU_SG_REL_ FCM_CE SG_ 290 SysBkUpPwrMd 290;
BA_REL_ "GenSigSuprvResp" BU_SG_REL_ FCM_CE SG_ 290 SysBkUpPwrMd 1;
BA_REL_ "GenSigVDAFailResp" BU_SG_REL_ FCM_CE SG_ 290 SysBkUpPwrMd 1;
BA_REL_ "GenSigVDAFailComment" BU_SG_REL_ FCM_CE SG_ 290 SysBkUpPwrMd "Backup Power Mode Master Virtual Device Availability";
BA_REL_ "GenSigTimeoutTime" BU_SG_REL_ IMU_CE SG_ 290 SysBkUpPwrMd 250;
BA_REL_ "GenSigTimeoutMsg" BU_SG_REL_ IMU_CE SG_ 290 SysBkUpPwrMd 290;
BA_REL_ "GenSigSuprvResp" BU_SG_REL_ IMU_CE SG_ 290 SysBkUpPwrMd 1;
BA_REL_ "GenSigVDAFailResp" BU_SG_REL_ IMU_CE SG_ 290 SysBkUpPwrMd 1;
BA_REL_ "GenSigVDAFailComment" BU_SG_REL_ IMU_CE SG_ 290 SysBkUpPwrMd "Backup Power Mode Master Virtual Device Availability";
BA_REL_ "GenSigTimeoutTime" BU_SG_REL_ SAS_CE SG_ 290 SysBkUpPwrMd 250;
BA_REL_ "GenSigTimeoutMsg" BU_SG_REL_ SAS_CE SG_ 290 SysBkUpPwrMd 290;
BA_REL_ "GenSigSuprvResp" BU_SG_REL_ SAS_CE SG_ 290 SysBkUpPwrMd 1;
BA_REL_ "GenSigVDAFailResp" BU_SG_REL_ SAS_CE SG_ 290 SysBkUpPwrMd 1;
BA_REL_ "GenSigVDAFailComment" BU_SG_REL_ SAS_CE SG_ 290 SysBkUpPwrMd "Backup Power Mode Master Virtual Device Availability";
BA_REL_ "GenSigTimeoutTime" BU_SG_REL_ APA_CE SG_ 304 IMULonAccPriAval 250;
BA_REL_ "GenSigTimeoutMsg" BU_SG_REL_ APA_CE SG_ 304 IMULonAccPriAval 304;
BA_REL_ "GenSigSuprvResp" BU_SG_REL_ APA_CE SG_ 304 IMULonAccPriAval 1;
BA_REL_ "GenSigTimeoutTime" BU_SG_REL_ FCM_CE SG_ 304 IMULonAccPriAval 250;
BA_REL_ "GenSigTimeoutMsg" BU_SG_REL_ FCM_CE SG_ 304 IMULonAccPriAval 304;
BA_REL_ "GenSigSuprvResp" BU_SG_REL_ FCM_CE SG_ 304 IMULonAccPriAval 1;
BA_REL_ "GenSigTimeoutTime" BU_SG_REL_ EPS_JR_CE SG_ 304 IMULonAccPriAval 250;
BA_REL_ "GenSigTimeoutMsg" BU_SG_REL_ EPS_JR_CE SG_ 304 IMULonAccPriAval 304;
BA_REL_ "GenSigSuprvResp" BU_SG_REL_ EPS_JR_CE SG_ 304 IMULonAccPriAval 1;
BA_REL_ "GenSigTimeoutTime" BU_SG_REL_ EPS_CE SG_ 304 IMULonAccPriAval 250;
BA_REL_ "GenSigTimeoutMsg" BU_SG_REL_ EPS_CE SG_ 304 IMULonAccPriAval 304;
BA_REL_ "GenSigSuprvResp" BU_SG_REL_ EPS_CE SG_ 304 IMULonAccPriAval 1;
BA_REL_ "GenSigTimeoutTime" BU_SG_REL_ APA_CE SG_ 304 IMULonAccSecAval 250;
BA_REL_ "GenSigTimeoutMsg" BU_SG_REL_ APA_CE SG_ 304 IMULonAccSecAval 304;
BA_REL_ "GenSigSuprvResp" BU_SG_REL_ APA_CE SG_ 304 IMULonAccSecAval 1;
BA_REL_ "GenSigTimeoutTime" BU_SG_REL_ FCM_CE SG_ 304 IMULonAccSecAval 250;
BA_REL_ "GenSigTimeoutMsg" BU_SG_REL_ FCM_CE SG_ 304 IMULonAccSecAval 304;
BA_REL_ "GenSigSuprvResp" BU_SG_REL_ FCM_CE SG_ 304 IMULonAccSecAval 1;
BA_REL_ "GenSigTimeoutTime" BU_SG_REL_ EPS_JR_CE SG_ 304 IMULonAccSecAval 250;
BA_REL_ "GenSigTimeoutMsg" BU_SG_REL_ EPS_JR_CE SG_ 304 IMULonAccSecAval 304;
BA_REL_ "GenSigSuprvResp" BU_SG_REL_ EPS_JR_CE SG_ 304 IMULonAccSecAval 1;
BA_REL_ "GenSigTimeoutTime" BU_SG_REL_ EPS_CE SG_ 304 IMULonAccSecAval 250;
BA_REL_ "GenSigTimeoutMsg" BU_SG_REL_ EPS_CE SG_ 304 IMULonAccSecAval 304;
BA_REL_ "GenSigSuprvResp" BU_SG_REL_ EPS_CE SG_ 304 IMULonAccSecAval 1;
BA_REL_ "GenSigTimeoutTime" BU_SG_REL_ APA_CE SG_ 304 IMUYawRtAccPriSecure 250;
BA_REL_ "GenSigTimeoutMsg" BU_SG_REL_ APA_CE SG_ 304 IMUYawRtAccPriSecure 304;
BA_REL_ "GenSigSuprvResp" BU_SG_REL_ APA_CE SG_ 304 IMUYawRtAccPriSecure 1;
BA_REL_ "GenSigTimeoutTime" BU_SG_REL_ FCM_CE SG_ 304 IMUYawRtAccPriSecure 250;
BA_REL_ "GenSigTimeoutMsg" BU_SG_REL_ FCM_CE SG_ 304 IMUYawRtAccPriSecure 304;
BA_REL_ "GenSigSuprvResp" BU_SG_REL_ FCM_CE SG_ 304 IMUYawRtAccPriSecure 1;
BA_REL_ "GenSigTimeoutTime" BU_SG_REL_ EPS_JR_CE SG_ 304 IMUYawRtAccPriSecure 250;
BA_REL_ "GenSigTimeoutMsg" BU_SG_REL_ EPS_JR_CE SG_ 304 IMUYawRtAccPriSecure 304;
BA_REL_ "GenSigSuprvResp" BU_SG_REL_ EPS_JR_CE SG_ 304 IMUYawRtAccPriSecure 1;
BA_REL_ "GenSigTimeoutTime" BU_SG_REL_ EPS_CE SG_ 304 IMUYawRtAccPriSecure 250;
BA_REL_ "GenSigTimeoutMsg" BU_SG_REL_ EPS_CE SG_ 304 IMUYawRtAccPriSecure 304;
BA_REL_ "GenSigSuprvResp" BU_SG_REL_ EPS_CE SG_ 304 IMUYawRtAccPriSecure 1;
BA_REL_ "GenSigRxStartValue" BU_SG_REL_ ACC_CE SG_ 304 IMUYawRtPriV "0";
BA_REL_ "GenSigTimeoutTime" BU_SG_REL_ FCM_CE SG_ 304 IMUYawRtPri 250;
BA_REL_ "GenSigTimeoutMsg" BU_SG_REL_ FCM_CE SG_ 304 IMUYawRtPri 304;
BA_REL_ "GenSigSuprvResp" BU_SG_REL_ FCM_CE SG_ 304 IMUYawRtPri 1;
BA_REL_ "GenSigTimeoutTime" BU_SG_REL_ EPS_JR_CE SG_ 304 IMUYawRtPri 250;
BA_REL_ "GenSigTimeoutMsg" BU_SG_REL_ EPS_JR_CE SG_ 304 IMUYawRtPri 304;
BA_REL_ "GenSigSuprvResp" BU_SG_REL_ EPS_JR_CE SG_ 304 IMUYawRtPri 1;
BA_REL_ "GenSigTimeoutTime" BU_SG_REL_ EPS_CE SG_ 304 IMUYawRtPri 250;
BA_REL_ "GenSigTimeoutMsg" BU_SG_REL_ EPS_CE SG_ 304 IMUYawRtPri 304;
BA_REL_ "GenSigSuprvResp" BU_SG_REL_ EPS_CE SG_ 304 IMUYawRtPri 1;
BA_REL_ "GenSigTimeoutTime" BU_SG_REL_ ACC_CE SG_ 304 IMUYawRtPri 125;
BA_REL_ "GenSigTimeoutMsg" BU_SG_REL_ ACC_CE SG_ 304 IMUYawRtPri 304;
BA_REL_ "GenSigSuprvResp" BU_SG_REL_ ACC_CE SG_ 304 IMUYawRtPri 1;
BA_REL_ "GenSigRxStartValue" BU_SG_REL_ ACC_CE SG_ 304 IMUYawRtPri "0";
BA_REL_ "GenSigVBitResp" BU_SG_REL_ ACC_CE SG_ 304 IMUYawRtPri 1;
BA_REL_ "GenSigRxStartValue" BU_SG_REL_ RDCM_CE SG_ 304 IMUYawRtPri "0";
BA_REL_ "GenSigVBitResp" BU_SG_REL_ SADS_CE SG_ 304 IMUYawRtPri 1;
BA_REL_ "GenSigTimeoutTime" BU_SG_REL_ APA_CE SG_ 304 IMURollCntPri 250;
BA_REL_ "GenSigTimeoutMsg" BU_SG_REL_ APA_CE SG_ 304 IMURollCntPri 304;
BA_REL_ "GenSigSuprvResp" BU_SG_REL_ APA_CE SG_ 304 IMURollCntPri 1;
BA_REL_ "GenSigTimeoutTime" BU_SG_REL_ FCM_CE SG_ 304 IMURollCntPri 250;
BA_REL_ "GenSigTimeoutMsg" BU_SG_REL_ FCM_CE SG_ 304 IMURollCntPri 304;
BA_REL_ "GenSigSuprvResp" BU_SG_REL_ FCM_CE SG_ 304 IMURollCntPri 1;
BA_REL_ "GenSigTimeoutTime" BU_SG_REL_ EOCM_F_CE SG_ 304 IMURollCntPri 120;
BA_REL_ "GenSigTimeoutMsg" BU_SG_REL_ EOCM_F_CE SG_ 304 IMURollCntPri 304;
BA_REL_ "GenSigSuprvResp" BU_SG_REL_ EOCM_F_CE SG_ 304 IMURollCntPri 1;
BA_REL_ "GenSigTimeoutTime" BU_SG_REL_ EPS_JR_CE SG_ 304 IMURollCntPri 250;
BA_REL_ "GenSigTimeoutMsg" BU_SG_REL_ EPS_JR_CE SG_ 304 IMURollCntPri 304;
BA_REL_ "GenSigSuprvResp" BU_SG_REL_ EPS_JR_CE SG_ 304 IMURollCntPri 1;
BA_REL_ "GenSigTimeoutTime" BU_SG_REL_ EPS_CE SG_ 304 IMURollCntPri 250;
BA_REL_ "GenSigTimeoutMsg" BU_SG_REL_ EPS_CE SG_ 304 IMURollCntPri 304;
BA_REL_ "GenSigSuprvResp" BU_SG_REL_ EPS_CE SG_ 304 IMURollCntPri 1;
BA_REL_ "GenSigRxStartValue" BU_SG_REL_ RDCM_CE SG_ 304 IMURollCntPri "0";
BA_REL_ "GenSigTimeoutTime" BU_SG_REL_ FCM_CE SG_ 304 IMUChksumPri 250;
BA_REL_ "GenSigTimeoutMsg" BU_SG_REL_ FCM_CE SG_ 304 IMUChksumPri 304;
BA_REL_ "GenSigSuprvResp" BU_SG_REL_ FCM_CE SG_ 304 IMUChksumPri 1;
BA_REL_ "GenSigTimeoutTime" BU_SG_REL_ EPS_JR_CE SG_ 304 IMUChksumPri 250;
BA_REL_ "GenSigTimeoutMsg" BU_SG_REL_ EPS_JR_CE SG_ 304 IMUChksumPri 304;
BA_REL_ "GenSigSuprvResp" BU_SG_REL_ EPS_JR_CE SG_ 304 IMUChksumPri 1;
BA_REL_ "GenSigTimeoutTime" BU_SG_REL_ EPS_CE SG_ 304 IMUChksumPri 250;
BA_REL_ "GenSigTimeoutMsg" BU_SG_REL_ EPS_CE SG_ 304 IMUChksumPri 304;
BA_REL_ "GenSigSuprvResp" BU_SG_REL_ EPS_CE SG_ 304 IMUChksumPri 1;
BA_REL_ "GenSigRxStartValue" BU_SG_REL_ ACC_CE SG_ 304 IMUChksumPri "0";
BA_REL_ "GenSigTimeoutTime" BU_SG_REL_ APA_CE SG_ 304 IMULonAccSec 250;
BA_REL_ "GenSigTimeoutMsg" BU_SG_REL_ APA_CE SG_ 304 IMULonAccSec 304;
BA_REL_ "GenSigSuprvResp" BU_SG_REL_ APA_CE SG_ 304 IMULonAccSec 1;
BA_REL_ "GenSigTimeoutTime" BU_SG_REL_ FCM_CE SG_ 304 IMULonAccSec 250;
BA_REL_ "GenSigTimeoutMsg" BU_SG_REL_ FCM_CE SG_ 304 IMULonAccSec 304;
BA_REL_ "GenSigSuprvResp" BU_SG_REL_ FCM_CE SG_ 304 IMULonAccSec 1;
BA_REL_ "GenSigTimeoutTime" BU_SG_REL_ EPS_JR_CE SG_ 304 IMULonAccSec 250;
BA_REL_ "GenSigTimeoutMsg" BU_SG_REL_ EPS_JR_CE SG_ 304 IMULonAccSec 304;
BA_REL_ "GenSigSuprvResp" BU_SG_REL_ EPS_JR_CE SG_ 304 IMULonAccSec 1;
BA_REL_ "GenSigTimeoutTime" BU_SG_REL_ EPS_CE SG_ 304 IMULonAccSec 250;
BA_REL_ "GenSigTimeoutMsg" BU_SG_REL_ EPS_CE SG_ 304 IMULonAccSec 304;
BA_REL_ "GenSigSuprvResp" BU_SG_REL_ EPS_CE SG_ 304 IMULonAccSec 1;
BA_REL_ "GenSigTimeoutTime" BU_SG_REL_ FCM_CE SG_ 304 IMULatAccPrim 250;
BA_REL_ "GenSigTimeoutMsg" BU_SG_REL_ FCM_CE SG_ 304 IMULatAccPrim 304;
BA_REL_ "GenSigSuprvResp" BU_SG_REL_ FCM_CE SG_ 304 IMULatAccPrim 1;
BA_REL_ "GenSigTimeoutTime" BU_SG_REL_ EPS_JR_CE SG_ 304 IMULatAccPrim 250;
BA_REL_ "GenSigTimeoutMsg" BU_SG_REL_ EPS_JR_CE SG_ 304 IMULatAccPrim 304;
BA_REL_ "GenSigSuprvResp" BU_SG_REL_ EPS_JR_CE SG_ 304 IMULatAccPrim 1;
BA_REL_ "GenSigTimeoutTime" BU_SG_REL_ EPS_CE SG_ 304 IMULatAccPrim 250;
BA_REL_ "GenSigTimeoutMsg" BU_SG_REL_ EPS_CE SG_ 304 IMULatAccPrim 304;
BA_REL_ "GenSigSuprvResp" BU_SG_REL_ EPS_CE SG_ 304 IMULatAccPrim 1;
BA_REL_ "GenSigTimeoutTime" BU_SG_REL_ EBCM_OBD_CE SG_ 304 IMULatAccPrim 25;
BA_REL_ "GenSigTimeoutMsg" BU_SG_REL_ EBCM_OBD_CE SG_ 304 IMULatAccPrim 304;
BA_REL_ "GenSigSuprvResp" BU_SG_REL_ EBCM_OBD_CE SG_ 304 IMULatAccPrim 1;
BA_REL_ "GenSigTimeoutTime" BU_SG_REL_ EBCM_CE SG_ 304 IMULatAccPrim 25;
BA_REL_ "GenSigTimeoutMsg" BU_SG_REL_ EBCM_CE SG_ 304 IMULatAccPrim 304;
BA_REL_ "GenSigSuprvResp" BU_SG_REL_ EBCM_CE SG_ 304 IMULatAccPrim 1;
BA_REL_ "GenSigTimeoutTime" BU_SG_REL_ RDCM_CE SG_ 304 IMULatAccPrim 250;
BA_REL_ "GenSigTimeoutMsg" BU_SG_REL_ RDCM_CE SG_ 304 IMULatAccPrim 304;
BA_REL_ "GenSigSuprvResp" BU_SG_REL_ RDCM_CE SG_ 304 IMULatAccPrim 1;
BA_REL_ "GenSigRxStartValue" BU_SG_REL_ RDCM_CE SG_ 304 IMULatAccPrim "0";
BA_REL_ "GenSigVBitResp" BU_SG_REL_ RDCM_CE SG_ 304 IMULatAccPrim 1;
BA_REL_ "GenSigTimeoutTime" BU_SG_REL_ SADS_CE SG_ 304 IMULatAccPrim 250;
BA_REL_ "GenSigTimeoutMsg" BU_SG_REL_ SADS_CE SG_ 304 IMULatAccPrim 304;
BA_REL_ "GenSigSuprvResp" BU_SG_REL_ SADS_CE SG_ 304 IMULatAccPrim 1;
BA_REL_ "GenSigVBitResp" BU_SG_REL_ SADS_CE SG_ 304 IMULatAccPrim 1;
BA_REL_ "GenSigTimeoutTime" BU_SG_REL_ ACC_CE SG_ 304 IMULatAccPrim 250;
BA_REL_ "GenSigTimeoutMsg" BU_SG_REL_ ACC_CE SG_ 304 IMULatAccPrim 304;
BA_REL_ "GenSigSuprvResp" BU_SG_REL_ ACC_CE SG_ 304 IMULatAccPrim 1;
BA_REL_ "GenSigRxStartValue" BU_SG_REL_ ACC_CE SG_ 304 IMULatAccPrim "0";
BA_REL_ "GenSigVBitResp" BU_SG_REL_ ACC_CE SG_ 304 IMULatAccPrim 1;
BA_REL_ "GenSigRxStartValue" BU_SG_REL_ ACC_CE SG_ 304 IMULatAccPrimV "0";
BA_REL_ "GenSigTimeoutTime" BU_SG_REL_ EBOOST_CE SG_ 289 TrStLgMdAtv 250;
BA_REL_ "GenSigTimeoutMsg" BU_SG_REL_ EBOOST_CE SG_ 289 TrStLgMdAtv 289;
BA_REL_ "GenSigSuprvResp" BU_SG_REL_ EBOOST_CE SG_ 289 TrStLgMdAtv 1;
BA_REL_ "GenSigVDAFailResp" BU_SG_REL_ EBOOST_CE SG_ 289 TrStLgMdAtv 1;
BA_REL_ "GenSigVDAFailComment" BU_SG_REL_ EBOOST_CE SG_ 289 TrStLgMdAtv "System Power Mode Virtual Device Availability";
BA_REL_ "GenSigTimeoutTime" BU_SG_REL_ TRCM_CE SG_ 289 TrStLgMdAtv 250;
BA_REL_ "GenSigTimeoutMsg" BU_SG_REL_ TRCM_CE SG_ 289 TrStLgMdAtv 289;
BA_REL_ "GenSigSuprvResp" BU_SG_REL_ TRCM_CE SG_ 289 TrStLgMdAtv 1;
BA_REL_ "GenSigVDAFailResp" BU_SG_REL_ TRCM_CE SG_ 289 TrStLgMdAtv 1;
BA_REL_ "GenSigVDAFailComment" BU_SG_REL_ TRCM_CE SG_ 289 TrStLgMdAtv "System Power Mode Virtual Device Availability";
BA_REL_ "GenSigTimeoutTime" BU_SG_REL_ EPS_JR_CE SG_ 289 TrStLgMdAtv 250;
BA_REL_ "GenSigTimeoutMsg" BU_SG_REL_ EPS_JR_CE SG_ 289 TrStLgMdAtv 289;
BA_REL_ "GenSigSuprvResp" BU_SG_REL_ EPS_JR_CE SG_ 289 TrStLgMdAtv 1;
BA_REL_ "GenSigVDAFailResp" BU_SG_REL_ EPS_JR_CE SG_ 289 TrStLgMdAtv 1;
BA_REL_ "GenSigVDAFailComment" BU_SG_REL_ EPS_JR_CE SG_ 289 TrStLgMdAtv "System Power Mode Virtual Device Availability";
BA_REL_ "GenSigTimeoutTime" BU_SG_REL_ MSB1_CE SG_ 289 TrStLgMdAtv 250;
BA_REL_ "GenSigTimeoutMsg" BU_SG_REL_ MSB1_CE SG_ 289 TrStLgMdAtv 289;
BA_REL_ "GenSigSuprvResp" BU_SG_REL_ MSB1_CE SG_ 289 TrStLgMdAtv 1;
BA_REL_ "GenSigVDAFailResp" BU_SG_REL_ MSB1_CE SG_ 289 TrStLgMdAtv 1;
BA_REL_ "GenSigVDAFailComment" BU_SG_REL_ MSB1_CE SG_ 289 TrStLgMdAtv "System Power Mode Virtual Device Availability";
BA_REL_ "GenSigTimeoutTime" BU_SG_REL_ MSB2_CE SG_ 289 TrStLgMdAtv 250;
BA_REL_ "GenSigTimeoutMsg" BU_SG_REL_ MSB2_CE SG_ 289 TrStLgMdAtv 289;
BA_REL_ "GenSigSuprvResp" BU_SG_REL_ MSB2_CE SG_ 289 TrStLgMdAtv 1;
BA_REL_ "GenSigVDAFailResp" BU_SG_REL_ MSB2_CE SG_ 289 TrStLgMdAtv 1;
BA_REL_ "GenSigVDAFailComment" BU_SG_REL_ MSB2_CE SG_ 289 TrStLgMdAtv "System Power Mode Virtual Device Availability";
BA_REL_ "GenSigTimeoutTime" BU_SG_REL_ FCM_CE SG_ 289 TrStLgMdAtv 250;
BA_REL_ "GenSigTimeoutMsg" BU_SG_REL_ FCM_CE SG_ 289 TrStLgMdAtv 289;
BA_REL_ "GenSigSuprvResp" BU_SG_REL_ FCM_CE SG_ 289 TrStLgMdAtv 1;
BA_REL_ "GenSigVDAFailResp" BU_SG_REL_ FCM_CE SG_ 289 TrStLgMdAtv 1;
BA_REL_ "GenSigVDAFailComment" BU_SG_REL_ FCM_CE SG_ 289 TrStLgMdAtv "System Power Mode Virtual Device Availability";
BA_REL_ "GenSigTimeoutTime" BU_SG_REL_ IMU_CE SG_ 289 TrStLgMdAtv 250;
BA_REL_ "GenSigTimeoutMsg" BU_SG_REL_ IMU_CE SG_ 289 TrStLgMdAtv 289;
BA_REL_ "GenSigSuprvResp" BU_SG_REL_ IMU_CE SG_ 289 TrStLgMdAtv 1;
BA_REL_ "GenSigVDAFailResp" BU_SG_REL_ IMU_CE SG_ 289 TrStLgMdAtv 1;
BA_REL_ "GenSigVDAFailComment" BU_SG_REL_ IMU_CE SG_ 289 TrStLgMdAtv "System Power Mode Virtual Device Availability";
BA_REL_ "GenSigTimeoutTime" BU_SG_REL_ SAS_CE SG_ 289 TrStLgMdAtv 250;
BA_REL_ "GenSigTimeoutMsg" BU_SG_REL_ SAS_CE SG_ 289 TrStLgMdAtv 289;
BA_REL_ "GenSigSuprvResp" BU_SG_REL_ SAS_CE SG_ 289 TrStLgMdAtv 1;
BA_REL_ "GenSigVDAFailResp" BU_SG_REL_ SAS_CE SG_ 289 TrStLgMdAtv 1;
BA_REL_ "GenSigVDAFailComment" BU_SG_REL_ SAS_CE SG_ 289 TrStLgMdAtv "System Power Mode Virtual Device Availability";
BA_REL_ "GenSigTimeoutTime" BU_SG_REL_ RDCM_CE SG_ 289 SysPwrMd 250;
BA_REL_ "GenSigTimeoutMsg" BU_SG_REL_ RDCM_CE SG_ 289 SysPwrMd 289;
BA_REL_ "GenSigSuprvResp" BU_SG_REL_ RDCM_CE SG_ 289 SysPwrMd 1;
BA_REL_ "GenSigTimeoutTime" BU_SG_REL_ EBOOST_CE SG_ 289 SysPwrMd 250;
BA_REL_ "GenSigTimeoutMsg" BU_SG_REL_ EBOOST_CE SG_ 289 SysPwrMd 289;
BA_REL_ "GenSigSuprvResp" BU_SG_REL_ EBOOST_CE SG_ 289 SysPwrMd 1;
BA_REL_ "GenSigVDAFailResp" BU_SG_REL_ EBOOST_CE SG_ 289 SysPwrMd 1;
BA_REL_ "GenSigVDAFailComment" BU_SG_REL_ EBOOST_CE SG_ 289 SysPwrMd "System Power Mode Virtual Device Availability";
BA_REL_ "GenSigTimeoutTime" BU_SG_REL_ TRCM_CE SG_ 289 SysPwrMd 250;
BA_REL_ "GenSigTimeoutMsg" BU_SG_REL_ TRCM_CE SG_ 289 SysPwrMd 289;
BA_REL_ "GenSigSuprvResp" BU_SG_REL_ TRCM_CE SG_ 289 SysPwrMd 1;
BA_REL_ "GenSigVDAFailResp" BU_SG_REL_ TRCM_CE SG_ 289 SysPwrMd 1;
BA_REL_ "GenSigVDAFailComment" BU_SG_REL_ TRCM_CE SG_ 289 SysPwrMd "System Power Mode Virtual Device Availability";
BA_REL_ "GenSigTimeoutTime" BU_SG_REL_ EPS_JR_CE SG_ 289 SysPwrMd 250;
BA_REL_ "GenSigTimeoutMsg" BU_SG_REL_ EPS_JR_CE SG_ 289 SysPwrMd 289;
BA_REL_ "GenSigSuprvResp" BU_SG_REL_ EPS_JR_CE SG_ 289 SysPwrMd 1;
BA_REL_ "GenSigVDAFailResp" BU_SG_REL_ EPS_JR_CE SG_ 289 SysPwrMd 1;
BA_REL_ "GenSigVDAFailComment" BU_SG_REL_ EPS_JR_CE SG_ 289 SysPwrMd "System Power Mode Virtual Device Availability";
BA_REL_ "GenSigTimeoutTime" BU_SG_REL_ MSB1_CE SG_ 289 SysPwrMd 250;
BA_REL_ "GenSigTimeoutMsg" BU_SG_REL_ MSB1_CE SG_ 289 SysPwrMd 289;
BA_REL_ "GenSigSuprvResp" BU_SG_REL_ MSB1_CE SG_ 289 SysPwrMd 1;
BA_REL_ "GenSigVDAFailResp" BU_SG_REL_ MSB1_CE SG_ 289 SysPwrMd 1;
BA_REL_ "GenSigVDAFailComment" BU_SG_REL_ MSB1_CE SG_ 289 SysPwrMd "System Power Mode Virtual Device Availability";
BA_REL_ "GenSigTimeoutTime" BU_SG_REL_ MSB2_CE SG_ 289 SysPwrMd 250;
BA_REL_ "GenSigTimeoutMsg" BU_SG_REL_ MSB2_CE SG_ 289 SysPwrMd 289;
BA_REL_ "GenSigSuprvResp" BU_SG_REL_ MSB2_CE SG_ 289 SysPwrMd 1;
BA_REL_ "GenSigVDAFailResp" BU_SG_REL_ MSB2_CE SG_ 289 SysPwrMd 1;
BA_REL_ "GenSigVDAFailComment" BU_SG_REL_ MSB2_CE SG_ 289 SysPwrMd "System Power Mode Virtual Device Availability";
BA_REL_ "GenSigTimeoutTime" BU_SG_REL_ SDM_CE SG_ 289 SysPwrMd 250;
BA_REL_ "GenSigTimeoutMsg" BU_SG_REL_ SDM_CE SG_ 289 SysPwrMd 289;
BA_REL_ "GenSigSuprvResp" BU_SG_REL_ SDM_CE SG_ 289 SysPwrMd 1;
BA_REL_ "GenSigVDAFailResp" BU_SG_REL_ SDM_CE SG_ 289 SysPwrMd 1;
BA_REL_ "GenSigVDAFailComment" BU_SG_REL_ SDM_CE SG_ 289 SysPwrMd "System Power Mode Virtual Device Availability";
BA_REL_ "GenSigTimeoutTime" BU_SG_REL_ FCM_CE SG_ 289 SysPwrMd 250;
BA_REL_ "GenSigTimeoutMsg" BU_SG_REL_ FCM_CE SG_ 289 SysPwrMd 289;
BA_REL_ "GenSigSuprvResp" BU_SG_REL_ FCM_CE SG_ 289 SysPwrMd 1;
BA_REL_ "GenSigVDAFailResp" BU_SG_REL_ FCM_CE SG_ 289 SysPwrMd 1;
BA_REL_ "GenSigVDAFailComment" BU_SG_REL_ FCM_CE SG_ 289 SysPwrMd "System Power Mode Virtual Device Availability";
BA_REL_ "GenSigTimeoutTime" BU_SG_REL_ IMU_CE SG_ 289 SysPwrMd 250;
BA_REL_ "GenSigTimeoutMsg" BU_SG_REL_ IMU_CE SG_ 289 SysPwrMd 289;
BA_REL_ "GenSigSuprvResp" BU_SG_REL_ IMU_CE SG_ 289 SysPwrMd 1;
BA_REL_ "GenSigVDAFailResp" BU_SG_REL_ IMU_CE SG_ 289 SysPwrMd 1;
BA_REL_ "GenSigVDAFailComment" BU_SG_REL_ IMU_CE SG_ 289 SysPwrMd "System Power Mode Virtual Device Availability";
BA_REL_ "GenSigTimeoutTime" BU_SG_REL_ SAS_CE SG_ 289 SysPwrMd 250;
BA_REL_ "GenSigTimeoutMsg" BU_SG_REL_ SAS_CE SG_ 289 SysPwrMd 289;
BA_REL_ "GenSigSuprvResp" BU_SG_REL_ SAS_CE SG_ 289 SysPwrMd 1;
BA_REL_ "GenSigVDAFailResp" BU_SG_REL_ SAS_CE SG_ 289 SysPwrMd 1;
BA_REL_ "GenSigVDAFailComment" BU_SG_REL_ SAS_CE SG_ 289 SysPwrMd "System Power Mode Virtual Device Availability";
BA_REL_ "GenSigTimeoutTime" BU_SG_REL_ EPS_JR_CE SG_ 192 WRSCD_RNDrvnCkVa 250;
BA_REL_ "GenSigTimeoutMsg" BU_SG_REL_ EPS_JR_CE SG_ 192 WRSCD_RNDrvnCkVa 192;
BA_REL_ "GenSigSuprvResp" BU_SG_REL_ EPS_JR_CE SG_ 192 WRSCD_RNDrvnCkVa 1;
BA_REL_ "GenSigTimeoutTime" BU_SG_REL_ ARS_CE SG_ 192 WRSCD_RNDrvnCkVa 250;
BA_REL_ "GenSigTimeoutMsg" BU_SG_REL_ ARS_CE SG_ 192 WRSCD_RNDrvnCkVa 192;
BA_REL_ "GenSigSuprvResp" BU_SG_REL_ ARS_CE SG_ 192 WRSCD_RNDrvnCkVa 1;
BA_REL_ "GenSigTimeoutTime" BU_SG_REL_ EOCM_F_CE SG_ 192 WRSCD_RNDrvnCkVa 120;
BA_REL_ "GenSigTimeoutMsg" BU_SG_REL_ EOCM_F_CE SG_ 192 WRSCD_RNDrvnCkVa 192;
BA_REL_ "GenSigSuprvResp" BU_SG_REL_ EOCM_F_CE SG_ 192 WRSCD_RNDrvnCkVa 1;
BA_REL_ "GenSigTimeoutTime" BU_SG_REL_ EPS_JR_CE SG_ 192 WRSCD_LfNDrvnCkVa 250;
BA_REL_ "GenSigTimeoutMsg" BU_SG_REL_ EPS_JR_CE SG_ 192 WRSCD_LfNDrvnCkVa 192;
BA_REL_ "GenSigSuprvResp" BU_SG_REL_ EPS_JR_CE SG_ 192 WRSCD_LfNDrvnCkVa 1;
BA_REL_ "GenSigTimeoutTime" BU_SG_REL_ ARS_CE SG_ 192 WRSCD_LfNDrvnCkVa 250;
BA_REL_ "GenSigTimeoutMsg" BU_SG_REL_ ARS_CE SG_ 192 WRSCD_LfNDrvnCkVa 192;
BA_REL_ "GenSigSuprvResp" BU_SG_REL_ ARS_CE SG_ 192 WRSCD_LfNDrvnCkVa 1;
BA_REL_ "GenSigTimeoutTime" BU_SG_REL_ EOCM_F_CE SG_ 192 WRSCD_LfNDrvnCkVa 120;
BA_REL_ "GenSigTimeoutMsg" BU_SG_REL_ EOCM_F_CE SG_ 192 WRSCD_LfNDrvnCkVa 192;
BA_REL_ "GenSigSuprvResp" BU_SG_REL_ EOCM_F_CE SG_ 192 WRSCD_LfNDrvnCkVa 1;
BA_REL_ "GenSigTimeoutTime" BU_SG_REL_ EPS_JR_CE SG_ 192 WRSCD_RDrvnCkVa 250;
BA_REL_ "GenSigTimeoutMsg" BU_SG_REL_ EPS_JR_CE SG_ 192 WRSCD_RDrvnCkVa 192;
BA_REL_ "GenSigSuprvResp" BU_SG_REL_ EPS_JR_CE SG_ 192 WRSCD_RDrvnCkVa 1;
BA_REL_ "GenSigTimeoutTime" BU_SG_REL_ ARS_CE SG_ 192 WRSCD_RDrvnCkVa 250;
BA_REL_ "GenSigTimeoutMsg" BU_SG_REL_ ARS_CE SG_ 192 WRSCD_RDrvnCkVa 192;
BA_REL_ "GenSigSuprvResp" BU_SG_REL_ ARS_CE SG_ 192 WRSCD_RDrvnCkVa 1;
BA_REL_ "GenSigTimeoutTime" BU_SG_REL_ EOCM_F_CE SG_ 192 WRSCD_RDrvnCkVa 120;
BA_REL_ "GenSigTimeoutMsg" BU_SG_REL_ EOCM_F_CE SG_ 192 WRSCD_RDrvnCkVa 192;
BA_REL_ "GenSigSuprvResp" BU_SG_REL_ EOCM_F_CE SG_ 192 WRSCD_RDrvnCkVa 1;
BA_REL_ "GenSigTimeoutTime" BU_SG_REL_ EPS_JR_CE SG_ 192 WRSCD_LfDrvnCkVa 250;
BA_REL_ "GenSigTimeoutMsg" BU_SG_REL_ EPS_JR_CE SG_ 192 WRSCD_LfDrvnCkVa 192;
BA_REL_ "GenSigSuprvResp" BU_SG_REL_ EPS_JR_CE SG_ 192 WRSCD_LfDrvnCkVa 1;
BA_REL_ "GenSigTimeoutTime" BU_SG_REL_ ARS_CE SG_ 192 WRSCD_LfDrvnCkVa 250;
BA_REL_ "GenSigTimeoutMsg" BU_SG_REL_ ARS_CE SG_ 192 WRSCD_LfDrvnCkVa 192;
BA_REL_ "GenSigSuprvResp" BU_SG_REL_ ARS_CE SG_ 192 WRSCD_LfDrvnCkVa 1;
BA_REL_ "GenSigTimeoutTime" BU_SG_REL_ EOCM_F_CE SG_ 192 WRSCD_LfDrvnCkVa 120;
BA_REL_ "GenSigTimeoutMsg" BU_SG_REL_ EOCM_F_CE SG_ 192 WRSCD_LfDrvnCkVa 192;
BA_REL_ "GenSigSuprvResp" BU_SG_REL_ EOCM_F_CE SG_ 192 WRSCD_LfDrvnCkVa 1;
BA_REL_ "GenSigTimeoutTime" BU_SG_REL_ EPS_JR_CE SG_ 192 WRSCD_RtNDrvnSNm 250;
BA_REL_ "GenSigTimeoutMsg" BU_SG_REL_ EPS_JR_CE SG_ 192 WRSCD_RtNDrvnSNm 192;
BA_REL_ "GenSigSuprvResp" BU_SG_REL_ EPS_JR_CE SG_ 192 WRSCD_RtNDrvnSNm 1;
BA_REL_ "GenSigTimeoutTime" BU_SG_REL_ ARS_CE SG_ 192 WRSCD_RtNDrvnSNm 250;
BA_REL_ "GenSigTimeoutMsg" BU_SG_REL_ ARS_CE SG_ 192 WRSCD_RtNDrvnSNm 192;
BA_REL_ "GenSigSuprvResp" BU_SG_REL_ ARS_CE SG_ 192 WRSCD_RtNDrvnSNm 1;
BA_REL_ "GenSigTimeoutTime" BU_SG_REL_ EOCM_F_CE SG_ 192 WRSCD_RtNDrvnSNm 120;
BA_REL_ "GenSigTimeoutMsg" BU_SG_REL_ EOCM_F_CE SG_ 192 WRSCD_RtNDrvnSNm 192;
BA_REL_ "GenSigSuprvResp" BU_SG_REL_ EOCM_F_CE SG_ 192 WRSCD_RtNDrvnSNm 1;
BA_REL_ "GenSigTimeoutTime" BU_SG_REL_ EPS_JR_CE SG_ 192 WRSCD_LftNDrvnSNm 250;
BA_REL_ "GenSigTimeoutMsg" BU_SG_REL_ EPS_JR_CE SG_ 192 WRSCD_LftNDrvnSNm 192;
BA_REL_ "GenSigSuprvResp" BU_SG_REL_ EPS_JR_CE SG_ 192 WRSCD_LftNDrvnSNm 1;
BA_REL_ "GenSigTimeoutTime" BU_SG_REL_ ARS_CE SG_ 192 WRSCD_LftNDrvnSNm 250;
BA_REL_ "GenSigTimeoutMsg" BU_SG_REL_ ARS_CE SG_ 192 WRSCD_LftNDrvnSNm 192;
BA_REL_ "GenSigSuprvResp" BU_SG_REL_ ARS_CE SG_ 192 WRSCD_LftNDrvnSNm 1;
BA_REL_ "GenSigTimeoutTime" BU_SG_REL_ EOCM_F_CE SG_ 192 WRSCD_LftNDrvnSNm 120;
BA_REL_ "GenSigTimeoutMsg" BU_SG_REL_ EOCM_F_CE SG_ 192 WRSCD_LftNDrvnSNm 192;
BA_REL_ "GenSigSuprvResp" BU_SG_REL_ EOCM_F_CE SG_ 192 WRSCD_LftNDrvnSNm 1;
BA_REL_ "GenSigTimeoutTime" BU_SG_REL_ EPS_JR_CE SG_ 192 WRSCD_RtDrvnSqNm 250;
BA_REL_ "GenSigTimeoutMsg" BU_SG_REL_ EPS_JR_CE SG_ 192 WRSCD_RtDrvnSqNm 192;
BA_REL_ "GenSigSuprvResp" BU_SG_REL_ EPS_JR_CE SG_ 192 WRSCD_RtDrvnSqNm 1;
BA_REL_ "GenSigTimeoutTime" BU_SG_REL_ ARS_CE SG_ 192 WRSCD_RtDrvnSqNm 250;
BA_REL_ "GenSigTimeoutMsg" BU_SG_REL_ ARS_CE SG_ 192 WRSCD_RtDrvnSqNm 192;
BA_REL_ "GenSigSuprvResp" BU_SG_REL_ ARS_CE SG_ 192 WRSCD_RtDrvnSqNm 1;
BA_REL_ "GenSigTimeoutTime" BU_SG_REL_ EOCM_F_CE SG_ 192 WRSCD_RtDrvnSqNm 120;
BA_REL_ "GenSigTimeoutMsg" BU_SG_REL_ EOCM_F_CE SG_ 192 WRSCD_RtDrvnSqNm 192;
BA_REL_ "GenSigSuprvResp" BU_SG_REL_ EOCM_F_CE SG_ 192 WRSCD_RtDrvnSqNm 1;
BA_REL_ "GenSigTimeoutTime" BU_SG_REL_ EPS_JR_CE SG_ 192 WRSCD_LftDrvnSqNm 250;
BA_REL_ "GenSigTimeoutMsg" BU_SG_REL_ EPS_JR_CE SG_ 192 WRSCD_LftDrvnSqNm 192;
BA_REL_ "GenSigSuprvResp" BU_SG_REL_ EPS_JR_CE SG_ 192 WRSCD_LftDrvnSqNm 1;
BA_REL_ "GenSigTimeoutTime" BU_SG_REL_ ARS_CE SG_ 192 WRSCD_LftDrvnSqNm 250;
BA_REL_ "GenSigTimeoutMsg" BU_SG_REL_ ARS_CE SG_ 192 WRSCD_LftDrvnSqNm 192;
BA_REL_ "GenSigSuprvResp" BU_SG_REL_ ARS_CE SG_ 192 WRSCD_LftDrvnSqNm 1;
BA_REL_ "GenSigTimeoutTime" BU_SG_REL_ EOCM_F_CE SG_ 192 WRSCD_LftDrvnSqNm 120;
BA_REL_ "GenSigTimeoutMsg" BU_SG_REL_ EOCM_F_CE SG_ 192 WRSCD_LftDrvnSqNm 192;
BA_REL_ "GenSigSuprvResp" BU_SG_REL_ EOCM_F_CE SG_ 192 WRSCD_LftDrvnSqNm 1;
BA_REL_ "GenSigTimeoutTime" BU_SG_REL_ EBCM_OBD_CE SG_ 328 StrngAsstRdcdIO 2500;
BA_REL_ "GenSigTimeoutMsg" BU_SG_REL_ EBCM_OBD_CE SG_ 328 StrngAsstRdcdIO 328;
BA_REL_ "GenSigSuprvResp" BU_SG_REL_ EBCM_OBD_CE SG_ 328 StrngAsstRdcdIO 1;
BA_REL_ "GenSigTimeoutTime" BU_SG_REL_ EBCM_CE SG_ 328 StrngAsstRdcdIO 2500;
BA_REL_ "GenSigTimeoutMsg" BU_SG_REL_ EBCM_CE SG_ 328 StrngAsstRdcdIO 328;
BA_REL_ "GenSigSuprvResp" BU_SG_REL_ EBCM_CE SG_ 328 StrngAsstRdcdIO 1;
VAL_ 832 BrkPedTrvlAchvd 1 "true" 0 "false" ;
VAL_ 832 BrkPedTrvlAchvdV 1 "Invalid" 0 "Valid" ;
VAL_ 832 AccActPosV 1 "Invalid" 0 "Valid" ;
VAL_ 462 SecAxlLkTqRqCplRqTp 0 "No Action" 1 "Maximum Allowed Torque" 2 "Minimum Allowed Torque" 3 "Control To Requested Torque" ;
VAL_ 462 SATRCplReqAtv 1 "true" 0 "false" ;
VAL_ 368 VehMvngStat 0 "Moving" 1 "Stopped" ;
VAL_ 368 FSRACCBrkngReqDenied 1 "true" 0 "false" ;
VAL_ 368 BrkSysPlsStat 0 "Not Active" 1 "In Progress" 2 "Pulse Failed" 3 "Pulse Complete" ;
VAL_ 368 BrkSysAutBrkStat 0 "Not active" 1 "Active" 2 "Limited" 3 "Failed" ;
VAL_ 368 BrkSysExtHldCpbltyFld 1 "true" 0 "false" ;
VAL_ 368 BrkSysAutBrkTrgtDclV 1 "Invalid" 0 "Valid" ;
VAL_ 368 BrkSysAutBrkActDclV 1 "Invalid" 0 "Valid" ;
VAL_ 469 TCRRATR_CplReqTp 0 "No Action" 1 "Maximum Allowed Torque" 2 "Minimum Allowed Torque" 3 "Control To Requested Torque" ;
VAL_ 469 TCRRATR_CplReqAct 1 "true" 0 "false" ;
VAL_ 469 TCLRATR_CplReqTp 0 "No Action" 1 "Maximum Allowed Torque" 2 "Minimum Allowed Torque" 3 "Control To Requested Torque" ;
VAL_ 469 TCLRATR_CplReqAct 1 "true" 0 "false" ;
VAL_ 467 TwnClThrmlProtReqAct 1 "true" 0 "false" ;
VAL_ 467 TwnCltchRrAxlMd 0 "Open" 1 "Differential" 2 "Yaw Control" 3 "Traction" 4 "Slip Control" ;
VAL_ 467 TwnCltchRrAxlCtrlStat 0 "Open" 1 "Active" ;
VAL_ 467 TwnClRrAxlThrmCapV 1 "Invalid" 0 "Valid" ;
VAL_ 467 RtRrAxlEstTrqV 1 "Invalid" 0 "Valid" ;
VAL_ 467 RtRrAxlEstTrqM 0 "Don't Use Data" 1 "Use Data" ;
VAL_ 467 LtRrAxlEstTrqV 1 "Invalid" 0 "Valid" ;
VAL_ 467 LtRrAxlEstTrqM 0 "Don't Use Data" 1 "Use Data" ;
VAL_ 467 TwnCltchRrAxlCtrlMd 0 "Internal" 1 "External" ;
VAL_ 467 TwnCltchRrAxlStat 0 "Normal" 1 "Temporary Inhibit" 2 "Temporary Limited" 3 "Permanently Failed" ;
VAL_ 352 RRDmpFrmnActValV 1 "Invalid" 0 "Valid" ;
VAL_ 352 RLDmpFrmnActValV 1 "Invalid" 0 "Valid" ;
VAL_ 352 FRDmpFrmnActValV 1 "Invalid" 0 "Valid" ;
VAL_ 352 FLDmpFrmnActValV 1 "Invalid" 0 "Valid" ;
VAL_ 352 DmpCtrlStat 4 "Force ESC ON" 3 "Communication failure" 0 "No control" 1 "Closed loop" 2 "Stability control failure" ;
VAL_ 805 RrVrtBmpBrkPrfReq 1 "true" 0 "false" ;
VAL_ 805 RVBCBSCE_BrkPlsReq 1 "true" 0 "false" ;
VAL_ 805 RVBCBSCE_AutoBrkReq 1 "true" 0 "false" ;
VAL_ 805 RVBCBSCE_AutoBrkReqTyp 0 "none" 1 "hold" ;
VAL_ 817 RrAxlActrEstmtdTrqV 1 "Invalid" 0 "Valid" ;
VAL_ 817 RrAxlActrEstmtdTrqM 0 "Don't Use Data" 1 "Use Data" ;
VAL_ 817 RrAxlActrThrmlCpctyV 1 "Invalid" 0 "Valid" ;
VAL_ 817 RrAxlActrThrmlCpctyM 0 "Don't Use Data" 1 "Use Data" ;
VAL_ 817 RrAxlActrStat 0 "Normal" 1 "Temporarily Inhibited" 2 "Temporarily Limited" 3 "Failure Detected" ;
VAL_ 566 RrAxlEstmtdRngGrTrqV 1 "Invalid" 0 "Valid" ;
VAL_ 566 RAATR_RrAxlMdRqst 0 "Normal" 1 "Retract Clutch Decay Profile 1" 2 "Retract Clutch Decay Profile 2" ;
VAL_ 320 IMULonAccPriV 1 "Invalid" 0 "Valid" ;
VAL_ 320 IMUXAxisClbrtd 0 "Not Calibrated" 1 "Calibrated" ;
VAL_ 320 IMUXAxisOrntn 0 "Connector Forward" 1 "Connector Rearward" ;
VAL_ 320 IMUPriYawDrftTyp 0 "Base" 1 "Low Drift" ;
VAL_ 320 IMUDataMsk 1 "true" 0 "false" ;
VAL_ 320 IMUYawRtSecAval 1 "true" 0 "false" ;
VAL_ 320 IMULatAccSecAval 1 "true" 0 "false" ;
VAL_ 320 IMUYawRtSecV 1 "Invalid" 0 "Valid" ;
VAL_ 320 IMULatACCSecV 1 "Invalid" 0 "Valid" ;
VAL_ 512 VhDynRRWhlSt 2 "Exiting Active" 1 "Active" 0 "Inactive" ;
VAL_ 512 VhDynRLWhlSt 2 "Exiting Active" 1 "Active" 0 "Inactive" ;
VAL_ 512 VhDynFRWhlSt 2 "Exiting Active" 1 "Active" 0 "Inactive" ;
VAL_ 512 VhDynFLWhlSt 2 "Exiting Active" 1 "Active" 0 "Inactive" ;
VAL_ 512 SASCalRq 1 "Calibrate Sensor" 0 "No Action" ;
VAL_ 512 PnonAngSnsCalReq 1 "true" 0 "false" ;
VAL_ 290 BkupPwrModeMstrVDA 1 "VirtualDeviceAvailable" 0 "VirtualDeviceUnavailable" ;
VAL_ 290 SysBkupPwrMdEn 1 "true" 0 "false" ;
VAL_ 290 SysBkUpPwrMd 3 "Crank Request" 2 "Run" 1 "Accessory" 0 "Off" ;
VAL_ 304 IMULonAccPriAval 1 "true" 0 "false" ;
VAL_ 304 IMULonAccSecAval 1 "true" 0 "false" ;
VAL_ 304 IMULonAccSecV 1 "Invalid" 0 "Valid" ;
VAL_ 304 IMUYawRtPriV 1 "Invalid" 0 "Valid" ;
VAL_ 304 IMULatAccPrimV 1 "Invalid" 0 "Valid" ;
VAL_ 289 SysPwMdVDA 1 "VirtualDeviceAvailable" 0 "VirtualDeviceUnavailable" ;
VAL_ 289 TrStLgMdAtv 1 "true" 0 "false" ;
VAL_ 289 SysPwrMd 3 "Crank Request" 2 "Run" 1 "Accessory" 0 "Off" ;
VAL_ 328 StrngAsstRdcdIO 1 "true" 0 "false" ;
VAL_ 328 PwrStrIO 1 "true" 0 "false" ;
VAL_ 458 TrqOvrlTrqDStat 0 "Inactive" 1 "Active" 2 "Temporarily Limited" 3 "Permanently Failed" ;
SIG_GROUP_ 832 BrkPedInitTrvlAchvdStat 1 : BrkPedTrvlAchvd BrkPedTrvlAchvdV;
SIG_GROUP_ 462 SecAxlTrqReq 1 : SATRCplReqVal SATRCplReqAtv;
SIG_GROUP_ 469 TwnClRRAxlTrqRq 1 : TCRRATR_CplReqVal TCRRATR_CplReqTp TCRRATR_CplReqAct;
SIG_GROUP_ 469 TwnClLRAxlTrqRq 1 : TCLRATR_CplReqVal TCLRATR_CplReqTp TCLRATR_CplReqAct;
SIG_GROUP_ 805 RVBCtrlBrkSysCmdExt 1 : RVBCBSCE_CtrlAcc RVBCBSCE_BrkPlsReq RVBCBSCE_AutoBrkReq RVBCBSCE_AutoBrkReqTyp;
SIG_GROUP_ 566 RrAxlActrTrqRqst 1 : RAATR_RrAxlTrqVl RAATR_RrAxlMdRqst;
SIG_GROUP_ 192 WhlRotatStatChkData 1 : WRSCD_RNDrvnCkVa WRSCD_LfNDrvnCkVa WRSCD_RDrvnCkVa WRSCD_LfDrvnCkVa WRSCD_RtNDrvnSNm WRSCD_LftNDrvnSNm WRSCD_RtDrvnSqNm WRSCD_LftDrvnSqNm;
